VERSION ""

NS_ :

BS_:

BU_: WPC2 PSB SHVU_RR FCS vHS_B2 EMCU SLB GW_APSU GW_DLBCU RCM ARS CGW_CCU vDummy_HS_B GW_RLPSU ATS RLHV SGU PFSU GW_RRPSU ALBCU DSAU SWRC SHVU_FR RCS GW_DPSU BLTN_CAM SCM OHCL RWPC RRHV WPC HOD ASAU

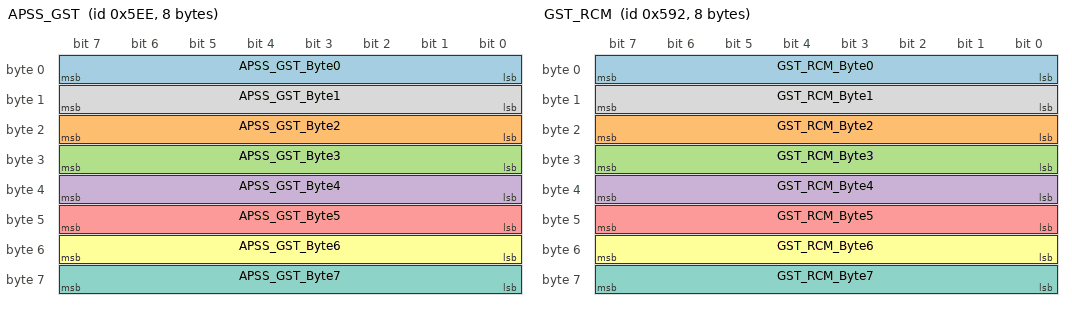
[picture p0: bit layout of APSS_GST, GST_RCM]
BO_ 1518 APSS_GST: 8 GW_APSU
 SG_ APSS_GST_Byte0 : 0|8@1+ (1,0) [0|0] ""  CGW_CCU
 SG_ APSS_GST_Byte2 : 16|8@1+ (1,0) [0|0] ""  CGW_CCU
 SG_ APSS_GST_Byte3 : 24|8@1+ (1,0) [0|0] ""  CGW_CCU
 SG_ APSS_GST_Byte4 : 32|8@1+ (1,0) [0|0] ""  CGW_CCU
 SG_ APSS_GST_Byte5 : 40|8@1+ (1,0) [0|0] ""  CGW_CCU
 SG_ APSS_GST_Byte6 : 48|8@1+ (1,0) [0|0] ""  CGW_CCU
 SG_ APSS_GST_Byte7 : 56|8@1+ (1,0) [0|0] ""  CGW_CCU
 SG_ APSS_GST_Byte1 : 8|8@1+ (1,0) [0|0] ""  CGW_CCU

BO_ 1426 GST_RCM: 8 CGW_CCU
 SG_ GST_RCM_Byte0 : 0|8@1+ (1,0) [0|0] ""  RCM
 SG_ GST_RCM_Byte2 : 16|8@1+ (1,0) [0|0] ""  RCM
 SG_ GST_RCM_Byte3 : 24|8@1+ (1,0) [0|0] ""  RCM
 SG_ GST_RCM_Byte4 : 32|8@1+ (1,0) [0|0] ""  RCM
 SG_ GST_RCM_Byte5 : 40|8@1+ (1,0) [0|0] ""  RCM
 SG_ GST_RCM_Byte6 : 48|8@1+ (1,0) [0|0] ""  RCM
 SG_ GST_RCM_Byte7 : 56|8@1+ (1,0) [0|0] ""  RCM
 SG_ GST_RCM_Byte1 : 8|8@1+ (1,0) [0|0] ""  RCM

BO_ 479 ALBCU_06_200ms: 8 ALBCU
 SG_ ALBCU_LumbarUpDis : 0|2@1+ (1,0) [0|0] "" Vector__XXX
 SG_ ALBCU_BolsterDefDis : 10|2@1+ (1,0) [0|0] "" Vector__XXX
 SG_ ALBCU_CushInfDis : 12|2@1+ (1,0) [0|0] "" Vector__XXX
 SG_ ALBCU_CushDefDis : 14|2@1+ (1,0) [0|0] "" Vector__XXX
 SG_ ALBCU_ActiveDis : 16|3@1+ (1,0) [0|0] ""  CGW_CCU
 SG_ ALBCU_DrvModUSMSta : 19|2@1+ (1,0) [0|0] ""  CGW_CCU
 SG_ ALBCU_LumbarMidDis : 2|2@1+ (1,0) [0|0] "" Vector__XXX
 SG_ ALBCU_ActiveStrSta : 21|2@1+ (1,0) [0|0] ""  CGW_CCU
 SG_ ALBCU_ActiveTimeSta : 23|3@1+ (1,0) [0|0] ""  CGW_CCU
 SG_ ALBCU_CellOpt : 26|3@1+ (1,0) [0|0] ""  CGW_CCU
 SG_ ALBCU_BodySpprtSta : 29|2@1+ (1,0) [0|0] ""  CGW_CCU
 SG_ ALBCU_BodySpprtDis : 31|2@1+ (1,0) [0|0] "" Vector__XXX
 SG_ ALBCU_SmartCtrl_Set_Rvalue : 33|4@1+ (1,0) [0|0] "" Vector__XXX
 SG_ ALBCU_MoodTrpyRValueSet : 37|2@1+ (1,0) [0|0] ""  CGW_CCU
 SG_ ALBCU_MoodTrpyCareSta : 39|2@1+ (1,0) [0|0] ""  CGW_CCU
 SG_ ALBCU_LumbarLowDis : 4|2@1+ (1,0) [0|0] "" Vector__XXX
 SG_ ALBCU_MoodTrpyComfSta : 41|2@1+ (1,0) [0|0] ""  CGW_CCU
 SG_ ALBCU_CushLeftPSnsrVtg : 48|6@1+ (1,0) [0|0] "V"  CGW_CCU
 SG_ ALBCU_CushRightPSnsrVtg : 56|6@1+ (1,0) [0|0] "V"  CGW_CCU
 SG_ ALBCU_LumbarDefDis : 6|2@1+ (1,0) [0|0] "" Vector__XXX
 SG_ ALBCU_BolsterInfDis : 8|2@1+ (1,0) [0|0] "" Vector__XXX

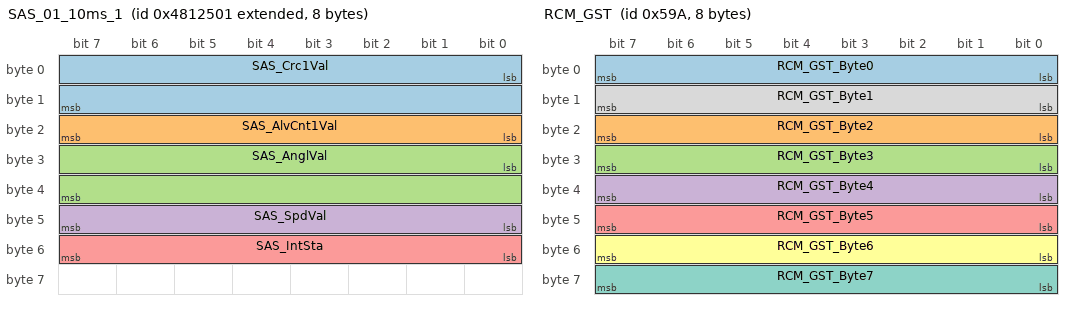
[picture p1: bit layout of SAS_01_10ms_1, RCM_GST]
BO_ 2223056129 SAS_01_10ms_1: 8 CGW_CCU
 SG_ SAS_Crc1Val : 0|16@1+ (1,0) [0|0] "" Vector__XXX
 SG_ SAS_AlvCnt1Val : 16|8@1+ (1,0) [0|0] "" Vector__XXX
 SG_ SAS_AnglVal : 24|16@1- (0.1,0) [0|0] "Deg"  BLTN_CAM,GW_DLBCU,PSB
 SG_ SAS_SpdVal : 40|8@1+ (4,0) [0|0] "Deg/s"  GW_DLBCU
 SG_ SAS_IntSta : 48|8@1+ (1,0) [0|0] "" Vector__XXX

BO_ 2223056130 SAS_01_10ms_2: 8 CGW_CCU

BO_ 1434 RCM_GST: 8 RCM
 SG_ RCM_GST_Byte0 : 0|8@1+ (1,0) [0|0] ""  CGW_CCU
 SG_ RCM_GST_Byte2 : 16|8@1+ (1,0) [0|0] ""  CGW_CCU
 SG_ RCM_GST_Byte3 : 24|8@1+ (1,0) [0|0] ""  CGW_CCU
 SG_ RCM_GST_Byte4 : 32|8@1+ (1,0) [0|0] ""  CGW_CCU
 SG_ RCM_GST_Byte5 : 40|8@1+ (1,0) [0|0] ""  CGW_CCU
 SG_ RCM_GST_Byte6 : 48|8@1+ (1,0) [0|0] ""  CGW_CCU
 SG_ RCM_GST_Byte7 : 56|8@1+ (1,0) [0|0] ""  CGW_CCU
 SG_ RCM_GST_Byte1 : 8|8@1+ (1,0) [0|0] ""  CGW_CCU

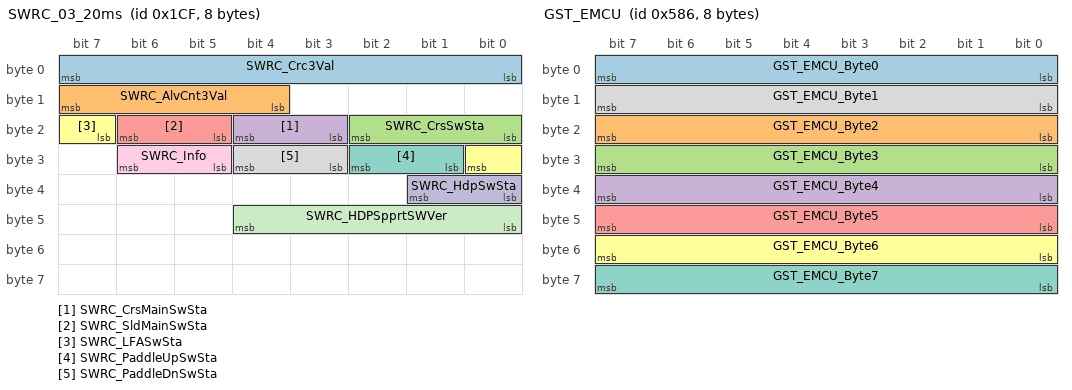
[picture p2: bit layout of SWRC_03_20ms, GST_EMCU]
BO_ 463 SWRC_03_20ms: 8 SWRC
 SG_ SWRC_Crc3Val : 0|8@1+ (1,0) [0|0] ""  CGW_CCU
 SG_ SWRC_AlvCnt3Val : 12|4@1+ (1,0) [0|0] ""  CGW_CCU
 SG_ SWRC_CrsSwSta : 16|3@1+ (1,0) [0|0] ""  CGW_CCU
 SG_ SWRC_CrsMainSwSta : 19|2@1+ (1,0) [0|0] ""  CGW_CCU
 SG_ SWRC_SldMainSwSta : 21|2@1+ (1,0) [0|0] ""  CGW_CCU
 SG_ SWRC_LFASwSta : 23|2@1+ (1,0) [0|0] ""  CGW_CCU
 SG_ SWRC_PaddleUpSwSta : 25|2@1+ (1,0) [0|0] ""  CGW_CCU
 SG_ SWRC_PaddleDnSwSta : 27|2@1+ (1,0) [0|0] ""  CGW_CCU
 SG_ SWRC_Info : 29|2@1+ (1,0) [0|0] ""  CGW_CCU
 SG_ SWRC_HdpSwSta : 32|2@1+ (1,0) [0|0] ""  CGW_CCU
 SG_ SWRC_HDPSpprtSWVer : 40|5@1+ (1,0) [0|0] ""  CGW_CCU

BO_ 1414 GST_EMCU: 8 CGW_CCU
 SG_ GST_EMCU_Byte0 : 0|8@1+ (1,0) [0|0] ""  EMCU
 SG_ GST_EMCU_Byte2 : 16|8@1+ (1,0) [0|0] ""  EMCU
 SG_ GST_EMCU_Byte3 : 24|8@1+ (1,0) [0|0] ""  EMCU
 SG_ GST_EMCU_Byte4 : 32|8@1+ (1,0) [0|0] ""  EMCU
 SG_ GST_EMCU_Byte5 : 40|8@1+ (1,0) [0|0] ""  EMCU
 SG_ GST_EMCU_Byte6 : 48|8@1+ (1,0) [0|0] ""  EMCU
 SG_ GST_EMCU_Byte7 : 56|8@1+ (1,0) [0|0] ""  EMCU
 SG_ GST_EMCU_Byte1 : 8|8@1+ (1,0) [0|0] ""  EMCU

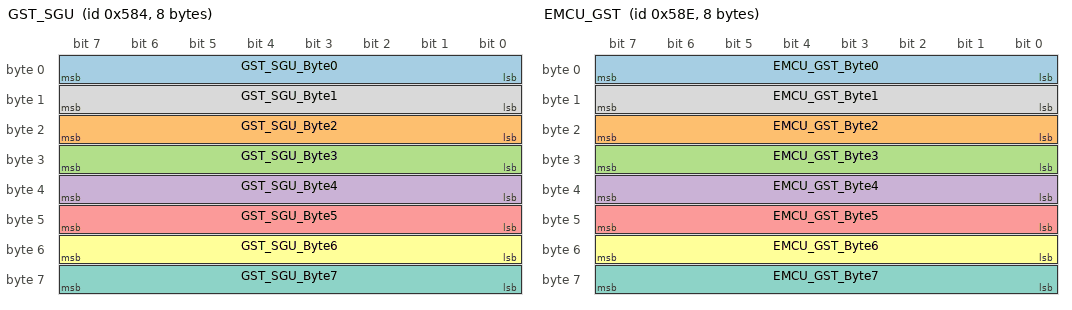
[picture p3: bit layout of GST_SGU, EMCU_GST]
BO_ 1412 GST_SGU: 8 CGW_CCU
 SG_ GST_SGU_Byte0 : 0|8@1+ (1,0) [0|0] ""  SGU
 SG_ GST_SGU_Byte2 : 16|8@1+ (1,0) [0|0] ""  SGU
 SG_ GST_SGU_Byte3 : 24|8@1+ (1,0) [0|0] ""  SGU
 SG_ GST_SGU_Byte4 : 32|8@1+ (1,0) [0|0] ""  SGU
 SG_ GST_SGU_Byte5 : 40|8@1+ (1,0) [0|0] ""  SGU
 SG_ GST_SGU_Byte6 : 48|8@1+ (1,0) [0|0] ""  SGU
 SG_ GST_SGU_Byte7 : 56|8@1+ (1,0) [0|0] ""  SGU
 SG_ GST_SGU_Byte1 : 8|8@1+ (1,0) [0|0] ""  SGU

BO_ 1422 EMCU_GST: 8 EMCU
 SG_ EMCU_GST_Byte0 : 0|8@1+ (1,0) [0|0] ""  CGW_CCU
 SG_ EMCU_GST_Byte2 : 16|8@1+ (1,0) [0|0] ""  CGW_CCU
 SG_ EMCU_GST_Byte3 : 24|8@1+ (1,0) [0|0] ""  CGW_CCU
 SG_ EMCU_GST_Byte4 : 32|8@1+ (1,0) [0|0] ""  CGW_CCU
 SG_ EMCU_GST_Byte5 : 40|8@1+ (1,0) [0|0] ""  CGW_CCU
 SG_ EMCU_GST_Byte6 : 48|8@1+ (1,0) [0|0] ""  CGW_CCU
 SG_ EMCU_GST_Byte7 : 56|8@1+ (1,0) [0|0] ""  CGW_CCU
 SG_ EMCU_GST_Byte1 : 8|8@1+ (1,0) [0|0] ""  CGW_CCU

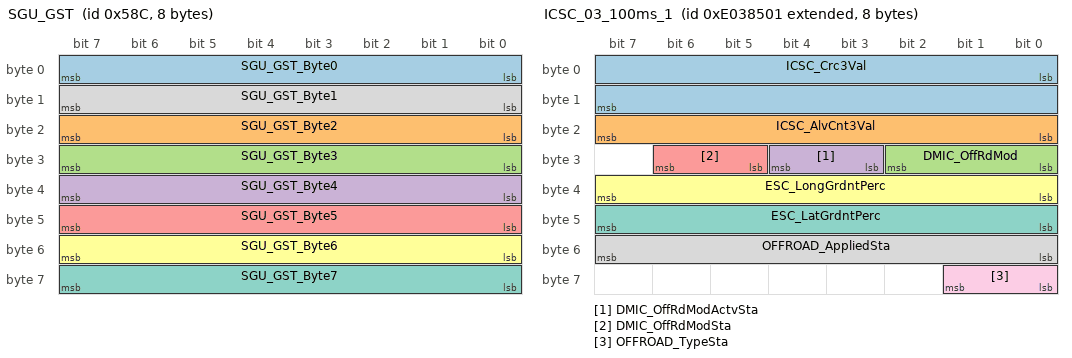
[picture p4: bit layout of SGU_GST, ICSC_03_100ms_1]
BO_ 1420 SGU_GST: 8 SGU
 SG_ SGU_GST_Byte0 : 0|8@1+ (1,0) [0|0] ""  CGW_CCU
 SG_ SGU_GST_Byte2 : 16|8@1+ (1,0) [0|0] ""  CGW_CCU
 SG_ SGU_GST_Byte3 : 24|8@1+ (1,0) [0|0] ""  CGW_CCU
 SG_ SGU_GST_Byte4 : 32|8@1+ (1,0) [0|0] ""  CGW_CCU
 SG_ SGU_GST_Byte5 : 40|8@1+ (1,0) [0|0] ""  CGW_CCU
 SG_ SGU_GST_Byte6 : 48|8@1+ (1,0) [0|0] ""  CGW_CCU
 SG_ SGU_GST_Byte7 : 56|8@1+ (1,0) [0|0] ""  CGW_CCU
 SG_ SGU_GST_Byte1 : 8|8@1+ (1,0) [0|0] ""  CGW_CCU

BO_ 2382595329 ICSC_03_100ms_1: 8 CGW_CCU
 SG_ ICSC_Crc3Val : 0|16@1+ (1,0) [0|0] "" Vector__XXX
 SG_ ICSC_AlvCnt3Val : 16|8@1+ (1,0) [0|0] "" Vector__XXX
 SG_ DMIC_OffRdMod : 24|3@1+ (1,0) [0|0] "" Vector__XXX
 SG_ DMIC_OffRdModActvSta : 27|2@1+ (1,0) [0|0] ""  RCS
 SG_ DMIC_OffRdModSta : 29|2@1+ (1,0) [0|0] "" Vector__XXX
 SG_ ESC_LongGrdntPerc : 32|8@1- (1,0) [0|0] "%"  EMCU
 SG_ ESC_LatGrdntPerc : 40|8@1- (1,0) [0|0] "%"  EMCU
 SG_ OFFROAD_AppliedSta : 48|8@1+ (1,0) [0|0] "" Vector__XXX
 SG_ OFFROAD_TypeSta : 56|2@1+ (1,0) [0|0] "" Vector__XXX

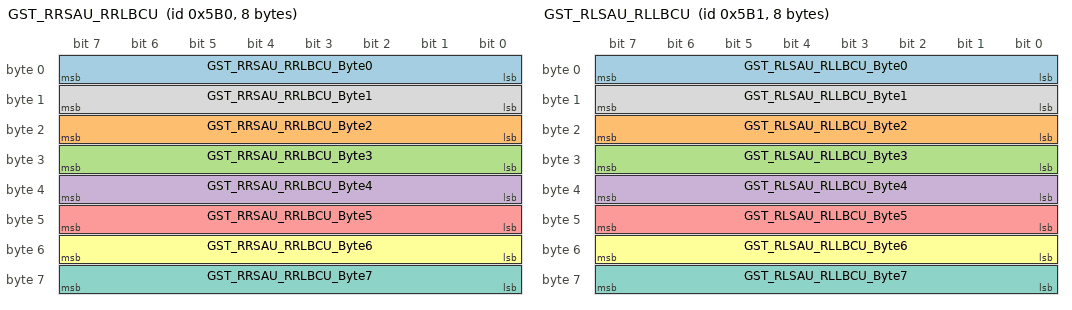
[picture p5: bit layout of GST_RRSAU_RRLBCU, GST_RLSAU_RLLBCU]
BO_ 1456 GST_RRSAU_RRLBCU: 8 CGW_CCU
 SG_ GST_RRSAU_RRLBCU_Byte0 : 0|8@1+ (1,0) [0|0] ""  GW_DLBCU
 SG_ GST_RRSAU_RRLBCU_Byte2 : 16|8@1+ (1,0) [0|0] ""  GW_DLBCU
 SG_ GST_RRSAU_RRLBCU_Byte3 : 24|8@1+ (1,0) [0|0] ""  GW_DLBCU
 SG_ GST_RRSAU_RRLBCU_Byte4 : 32|8@1+ (1,0) [0|0] ""  GW_DLBCU
 SG_ GST_RRSAU_RRLBCU_Byte5 : 40|8@1+ (1,0) [0|0] ""  GW_DLBCU
 SG_ GST_RRSAU_RRLBCU_Byte6 : 48|8@1+ (1,0) [0|0] ""  GW_DLBCU
 SG_ GST_RRSAU_RRLBCU_Byte7 : 56|8@1+ (1,0) [0|0] ""  GW_DLBCU
 SG_ GST_RRSAU_RRLBCU_Byte1 : 8|8@1+ (1,0) [0|0] ""  GW_DLBCU

BO_ 1457 GST_RLSAU_RLLBCU: 8 CGW_CCU
 SG_ GST_RLSAU_RLLBCU_Byte0 : 0|8@1+ (1,0) [0|0] ""  GW_DLBCU
 SG_ GST_RLSAU_RLLBCU_Byte2 : 16|8@1+ (1,0) [0|0] ""  GW_DLBCU
 SG_ GST_RLSAU_RLLBCU_Byte3 : 24|8@1+ (1,0) [0|0] ""  GW_DLBCU
 SG_ GST_RLSAU_RLLBCU_Byte4 : 32|8@1+ (1,0) [0|0] ""  GW_DLBCU
 SG_ GST_RLSAU_RLLBCU_Byte5 : 40|8@1+ (1,0) [0|0] ""  GW_DLBCU
 SG_ GST_RLSAU_RLLBCU_Byte6 : 48|8@1+ (1,0) [0|0] ""  GW_DLBCU
 SG_ GST_RLSAU_RLLBCU_Byte7 : 56|8@1+ (1,0) [0|0] ""  GW_DLBCU
 SG_ GST_RLSAU_RLLBCU_Byte1 : 8|8@1+ (1,0) [0|0] ""  GW_DLBCU

BO_ 2328014852 DATC_17_200ms_4: 8 CGW_CCU

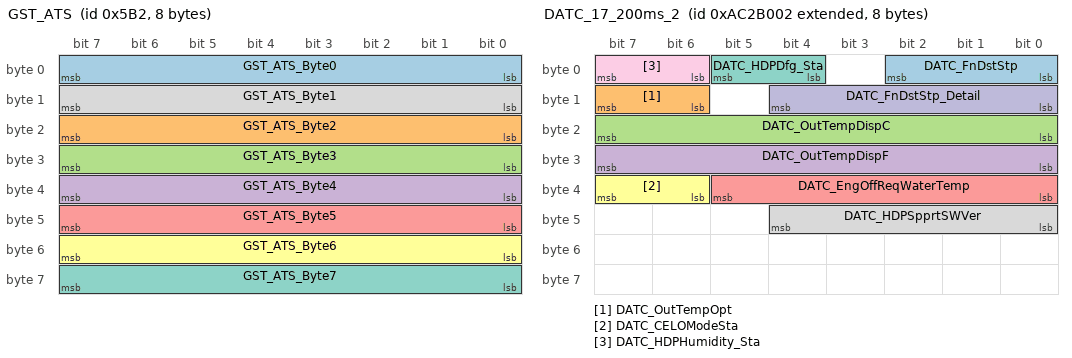
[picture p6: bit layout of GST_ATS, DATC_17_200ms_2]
BO_ 1458 GST_ATS: 8 CGW_CCU
 SG_ GST_ATS_Byte0 : 0|8@1+ (1,0) [0|0] ""  ATS
 SG_ GST_ATS_Byte2 : 16|8@1+ (1,0) [0|0] ""  ATS
 SG_ GST_ATS_Byte3 : 24|8@1+ (1,0) [0|0] ""  ATS
 SG_ GST_ATS_Byte4 : 32|8@1+ (1,0) [0|0] ""  ATS
 SG_ GST_ATS_Byte5 : 40|8@1+ (1,0) [0|0] ""  ATS
 SG_ GST_ATS_Byte6 : 48|8@1+ (1,0) [0|0] ""  ATS
 SG_ GST_ATS_Byte7 : 56|8@1+ (1,0) [0|0] ""  ATS
 SG_ GST_ATS_Byte1 : 8|8@1+ (1,0) [0|0] ""  ATS

BO_ 2328014850 DATC_17_200ms_2: 8 CGW_CCU
 SG_ DATC_FnDstStp : 0|3@1+ (1,0) [0|0] ""  ATS
 SG_ DATC_OutTempOpt : 14|2@1+ (1,0) [0|0] "" Vector__XXX
 SG_ DATC_OutTempDispC : 16|8@1+ (0.5,-41) [0|0] "¡É"  ATS
 SG_ DATC_OutTempDispF : 24|8@1+ (1,-42) [0|0] "¢µ"  ATS
 SG_ DATC_EngOffReqWaterTemp : 32|6@1+ (1,38) [0|0] "¡É" Vector__XXX
 SG_ DATC_CELOModeSta : 38|2@1+ (1,0) [0|0] "" Vector__XXX
 SG_ DATC_HDPDfg_Sta : 4|2@1+ (1,0) [0|0] "" Vector__XXX
 SG_ DATC_HDPSpprtSWVer : 40|5@1+ (1,0) [0|0] "" Vector__XXX
 SG_ DATC_HDPHumidity_Sta : 6|2@1+ (1,0) [0|0] "" Vector__XXX
 SG_ DATC_FnDstStp_Detail : 8|5@1+ (1,0) [0|0] ""  ATS

BO_ 2328014851 DATC_17_200ms_3: 8 CGW_CCU

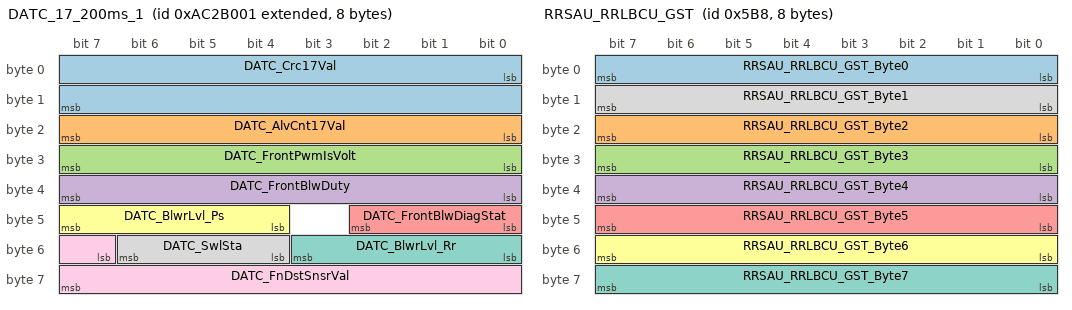
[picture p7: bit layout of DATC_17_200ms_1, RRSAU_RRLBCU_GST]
BO_ 2328014849 DATC_17_200ms_1: 8 CGW_CCU
 SG_ DATC_Crc17Val : 0|16@1+ (1,0) [0|0] "" Vector__XXX
 SG_ DATC_AlvCnt17Val : 16|8@1+ (1,0) [0|0] "" Vector__XXX
 SG_ DATC_FrontPwmIsVolt : 24|8@1+ (0.02,0) [0|0] "V" Vector__XXX
 SG_ DATC_FrontBlwDuty : 32|8@1+ (1,0) [0|0] "" Vector__XXX
 SG_ DATC_FrontBlwDiagStat : 40|3@1+ (1,0) [0|0] "" Vector__XXX
 SG_ DATC_BlwrLvl_Ps : 44|4@1+ (1,0) [0|0] "" Vector__XXX
 SG_ DATC_BlwrLvl_Rr : 48|4@1+ (1,0) [0|0] "" Vector__XXX
 SG_ DATC_SwlSta : 52|3@1+ (1,0) [0|0] "" Vector__XXX
 SG_ DATC_FnDstSnsrVal : 55|9@1+ (1,0) [0|0] "" Vector__XXX

BO_ 1464 RRSAU_RRLBCU_GST: 8 GW_DLBCU
 SG_ RRSAU_RRLBCU_GST_Byte0 : 0|8@1+ (1,0) [0|0] ""  CGW_CCU
 SG_ RRSAU_RRLBCU_GST_Byte2 : 16|8@1+ (1,0) [0|0] ""  CGW_CCU
 SG_ RRSAU_RRLBCU_GST_Byte3 : 24|8@1+ (1,0) [0|0] ""  CGW_CCU
 SG_ RRSAU_RRLBCU_GST_Byte4 : 32|8@1+ (1,0) [0|0] ""  CGW_CCU
 SG_ RRSAU_RRLBCU_GST_Byte5 : 40|8@1+ (1,0) [0|0] ""  CGW_CCU
 SG_ RRSAU_RRLBCU_GST_Byte6 : 48|8@1+ (1,0) [0|0] ""  CGW_CCU
 SG_ RRSAU_RRLBCU_GST_Byte7 : 56|8@1+ (1,0) [0|0] ""  CGW_CCU
 SG_ RRSAU_RRLBCU_GST_Byte1 : 8|8@1+ (1,0) [0|0] ""  CGW_CCU

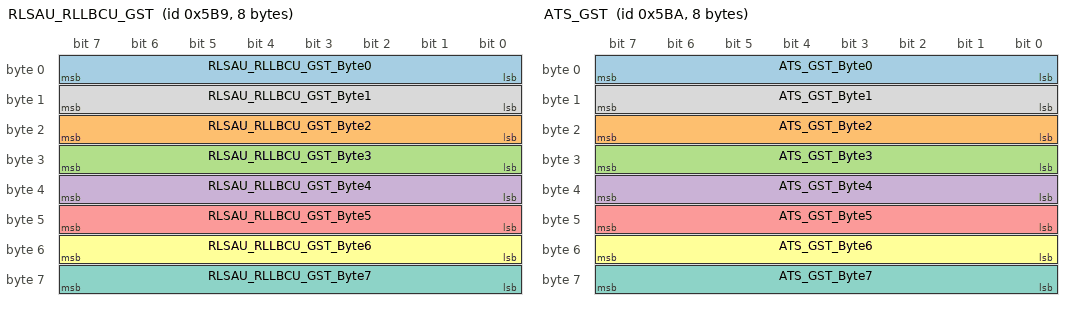
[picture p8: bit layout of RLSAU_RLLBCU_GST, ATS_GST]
BO_ 1465 RLSAU_RLLBCU_GST: 8 GW_DLBCU
 SG_ RLSAU_RLLBCU_GST_Byte0 : 0|8@1+ (1,0) [0|0] ""  CGW_CCU
 SG_ RLSAU_RLLBCU_GST_Byte2 : 16|8@1+ (1,0) [0|0] ""  CGW_CCU
 SG_ RLSAU_RLLBCU_GST_Byte3 : 24|8@1+ (1,0) [0|0] ""  CGW_CCU
 SG_ RLSAU_RLLBCU_GST_Byte4 : 32|8@1+ (1,0) [0|0] ""  CGW_CCU
 SG_ RLSAU_RLLBCU_GST_Byte5 : 40|8@1+ (1,0) [0|0] ""  CGW_CCU
 SG_ RLSAU_RLLBCU_GST_Byte6 : 48|8@1+ (1,0) [0|0] ""  CGW_CCU
 SG_ RLSAU_RLLBCU_GST_Byte7 : 56|8@1+ (1,0) [0|0] ""  CGW_CCU
 SG_ RLSAU_RLLBCU_GST_Byte1 : 8|8@1+ (1,0) [0|0] ""  CGW_CCU

BO_ 1466 ATS_GST: 8 ATS
 SG_ ATS_GST_Byte0 : 0|8@1+ (1,0) [0|0] ""  CGW_CCU
 SG_ ATS_GST_Byte2 : 16|8@1+ (1,0) [0|0] ""  CGW_CCU
 SG_ ATS_GST_Byte3 : 24|8@1+ (1,0) [0|0] ""  CGW_CCU
 SG_ ATS_GST_Byte4 : 32|8@1+ (1,0) [0|0] ""  CGW_CCU
 SG_ ATS_GST_Byte5 : 40|8@1+ (1,0) [0|0] ""  CGW_CCU
 SG_ ATS_GST_Byte6 : 48|8@1+ (1,0) [0|0] ""  CGW_CCU
 SG_ ATS_GST_Byte7 : 56|8@1+ (1,0) [0|0] ""  CGW_CCU
 SG_ ATS_GST_Byte1 : 8|8@1+ (1,0) [0|0] ""  CGW_CCU

BO_ 491 HU_USM_E_14: 8 CGW_CCU
 SG_ CF_AVN_Roof_OprLvSet : 0|3@1+ (1,0) [0|0] ""  SGU
 SG_ CF_AVN_3rdRightDoor_OptLvlSet : 12|3@1+ (1,0) [0|0] ""  SGU
 SG_ CF_AVN_RearDoor_OptLvlSet : 15|3@1+ (1,0) [0|0] ""  SGU
 SG_ CF_AVN_RollBlindOnOffSet : 18|2@1+ (1,0) [0|0] ""  SGU
 SG_ CF_AVN_CluThmAutoSet_New : 20|2@1+ (1,0) [0|0] "" Vector__XXX
 SG_ CF_AVN_CluThmSet_New : 22|3@1+ (1,0) [0|0] "" Vector__XXX
 SG_ CF_AVN_CluThmDtlSet_New : 25|3@1+ (1,0) [0|0] "" Vector__XXX
 SG_ CF_AVN_MdLmpAIVoiceUSMNValueSet : 28|2@1+ (1,0) [0|0] "" Vector__XXX
 SG_ CF_AVN_2ndLeftDoor_OptLvSet : 3|3@1+ (1,0) [0|0] ""  SGU
 SG_ CF_AVN_DWL_SelectNvalueSet : 30|4@1+ (1,0) [0|0] "" Vector__XXX
 SG_ PwrDRClosingDrvDrReq : 34|2@1+ (1,0) [0|0] "" Vector__XXX
 SG_ CF_Gway_WPCAnimationNvalueSet : 40|3@1+ (1,0) [0|0] ""  RWPC,WPC,WPC2
 SG_ PwrDRClosingAstDrReq : 43|2@1+ (1,0) [0|0] "" Vector__XXX
 SG_ PwrDRClosingRLDrReq : 45|2@1+ (1,0) [0|0] "" Vector__XXX
 SG_ PwrDrClosingRRDrReq : 47|2@1+ (1,0) [0|0] "" Vector__XXX
 SG_ USM_BtnIllumiAlwaysOnReq : 49|2@1+ (1,0) [0|0] "" Vector__XXX
 SG_ CF_AVN_LKAWrngVolNvalueSet : 51|2@1+ (1,0) [0|0] "" Vector__XXX
 SG_ DAB_IlluminationVrModeSet : 53|3@1+ (1,0) [0|0] ""  SWRC
 SG_ USM_IllAlwaysOnwithPSTNReq : 56|3@1+ (1,0) [0|0] "" Vector__XXX
 SG_ CF_AVN_AutoStopTimerResetSet : 59|3@1+ (1,0) [0|0] "" Vector__XXX
 SG_ CF_AVN_2ndRightDoor_OptLvSet : 6|3@1+ (1,0) [0|0] ""  SGU
 SG_ USM_RrCurtainSet : 62|2@1+ (1,0) [0|0] "" Vector__XXX
 SG_ CF_AVN_3rdLeftDoor_OptLvlSet : 9|3@1+ (1,0) [0|0] ""  SGU

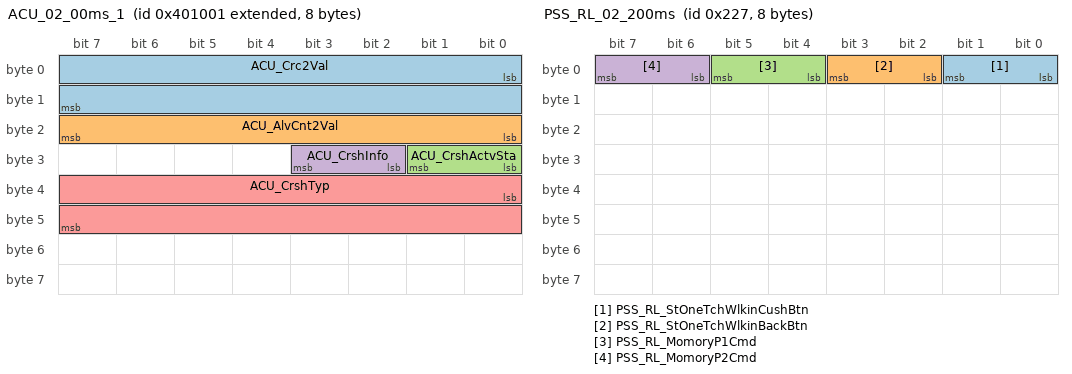
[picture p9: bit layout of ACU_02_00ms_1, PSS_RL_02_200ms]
BO_ 2151682049 ACU_02_00ms_1: 8 CGW_CCU
 SG_ ACU_Crc2Val : 0|16@1+ (1,0) [0|0] "" Vector__XXX
 SG_ ACU_AlvCnt2Val : 16|8@1+ (1,0) [0|0] "" Vector__XXX
 SG_ ACU_CrshActvSta : 24|2@1+ (1,0) [0|0] ""  GW_APSU,GW_DPSU,GW_RLPSU,GW_RRPSU
 SG_ ACU_CrshInfo : 26|2@1+ (1,0) [0|0] "" Vector__XXX
 SG_ ACU_CrshTyp : 32|16@1+ (1,0) [0|0] "" Vector__XXX

BO_ 550 PSS_RL_01_200ms: 8 GW_RLPSU
 SG_ PSS_RL_StSldFwdMvBtn : 0|2@1+ (1,0) [0|0] ""  CGW_CCU
 SG_ PSS_RL_StTltDnMvBtn : 10|2@1+ (1,0) [0|0] ""  CGW_CCU
 SG_ PSS_RL_StHRestUpMvBtn : 12|2@1+ (1,0) [0|0] ""  CGW_CCU
 SG_ PSS_RL_StHRestDnMvBtn : 14|2@1+ (1,0) [0|0] ""  CGW_CCU
 SG_ PSS_RL_StHRestFwdMvBtn : 16|2@1+ (1,0) [0|0] ""  CGW_CCU
 SG_ PSS_RL_StHRestBwdMvBtn : 18|2@1+ (1,0) [0|0] ""  CGW_CCU
 SG_ PSS_RL_StSldBwdMvBtn : 2|2@1+ (1,0) [0|0] ""  CGW_CCU
 SG_ PSS_RL_StLegRestUpBtn : 20|2@1+ (1,0) [0|0] ""  CGW_CCU
 SG_ PSS_RL_StLegRestDnBtn : 22|2@1+ (1,0) [0|0] ""  CGW_CCU
 SG_ PSS_RL_StLegRestExtFwdBtn : 24|2@1+ (1,0) [0|0] ""  CGW_CCU
 SG_ PSS_RL_StLegRestExtBwdBtn : 26|2@1+ (1,0) [0|0] ""  CGW_CCU
 SG_ PSS_RL_StRlxModeBtn : 28|2@1+ (1,0) [0|0] ""  CGW_CCU
 SG_ PSS_RL_StRlxReturnBtn : 30|2@1+ (1,0) [0|0] ""  CGW_CCU
 SG_ PSS_RL_StRlxTltUpMvBtn : 32|2@1+ (1,0) [0|0] ""  CGW_CCU
 SG_ PSS_RL_StRlxTltDnMvBtn : 34|2@1+ (1,0) [0|0] ""  CGW_CCU
 SG_ PSS_RL_StMnlRlxModeBtn : 36|2@1+ (1,0) [0|0] ""  CGW_CCU
 SG_ PSS_RL_StMnlRlxReturnBtn : 38|2@1+ (1,0) [0|0] ""  CGW_CCU
 SG_ PSS_RL_StRclFwdMvBtn : 4|2@1+ (1,0) [0|0] ""  CGW_CCU
 SG_ PSS_RL_WalkInSwitchSts : 40|2@1+ (1,0) [0|0] ""  CGW_CCU
 SG_ PSS_RL_StRclBwdMvBtn : 6|2@1+ (1,0) [0|0] ""  CGW_CCU
 SG_ PSS_RL_StTltUpMvBtn : 8|2@1+ (1,0) [0|0] ""  CGW_CCU

BO_ 551 PSS_RL_02_200ms: 8 GW_RLPSU
 SG_ PSS_RL_StOneTchWlkinCushBtn : 0|2@1+ (1,0) [0|0] ""  CGW_CCU
 SG_ PSS_RL_StOneTchWlkinBackBtn : 2|2@1+ (1,0) [0|0] ""  CGW_CCU
 SG_ PSS_RL_MomoryP1Cmd : 4|2@1+ (1,0) [0|0] ""  CGW_CCU
 SG_ PSS_RL_MomoryP2Cmd : 6|2@1+ (1,0) [0|0] ""  CGW_CCU

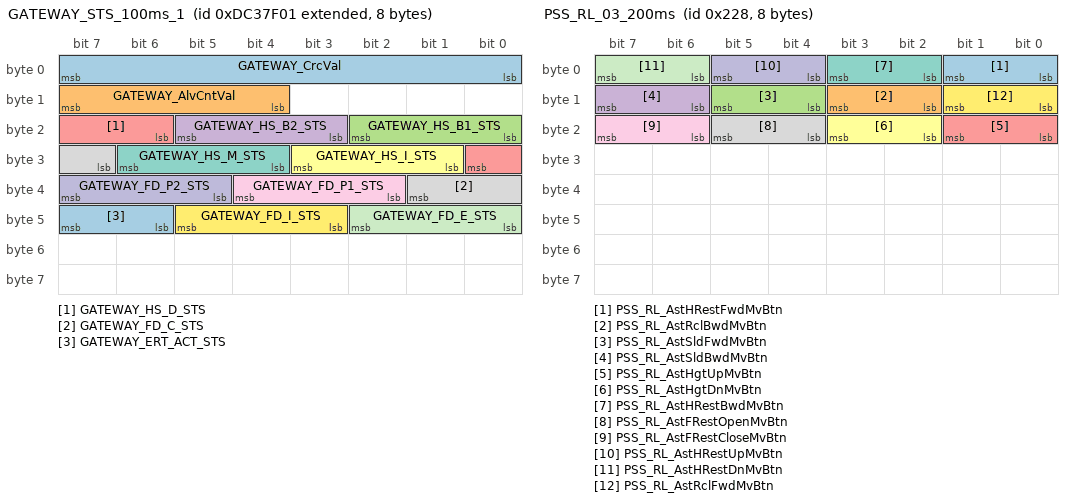
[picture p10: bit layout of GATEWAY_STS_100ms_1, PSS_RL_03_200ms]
BO_ 2378399489 GATEWAY_STS_100ms_1: 8 CGW_CCU
 SG_ GATEWAY_CrcVal : 0|8@1+ (1,0) [0|0] ""  vHS_B2
 SG_ GATEWAY_AlvCntVal : 12|4@1+ (1,0) [0|0] "" Vector__XXX
 SG_ GATEWAY_HS_B1_STS : 16|3@1+ (1,0) [0|0] ""  vHS_B2
 SG_ GATEWAY_HS_B2_STS : 19|3@1+ (1,0) [0|0] ""  vHS_B2
 SG_ GATEWAY_HS_D_STS : 22|3@1+ (1,0) [0|0] ""  vHS_B2
 SG_ GATEWAY_HS_I_STS : 25|3@1+ (1,0) [0|0] "" Vector__XXX
 SG_ GATEWAY_HS_M_STS : 28|3@1+ (1,0) [0|0] "" Vector__XXX
 SG_ GATEWAY_FD_C_STS : 31|3@1+ (1,0) [0|0] "" Vector__XXX
 SG_ GATEWAY_FD_P1_STS : 34|3@1+ (1,0) [0|0] "" Vector__XXX
 SG_ GATEWAY_FD_P2_STS : 37|3@1+ (1,0) [0|0] "" Vector__XXX
 SG_ GATEWAY_FD_E_STS : 40|3@1+ (1,0) [0|0] "" Vector__XXX
 SG_ GATEWAY_FD_I_STS : 43|3@1+ (1,0) [0|0] ""  vHS_B2
 SG_ GATEWAY_ERT_ACT_STS : 46|2@1+ (1,0) [0|0] "" Vector__XXX

BO_ 552 PSS_RL_03_200ms: 8 GW_RLPSU
 SG_ PSS_RL_AstHRestFwdMvBtn : 0|2@1+ (1,0) [0|0] ""  CGW_CCU
 SG_ PSS_RL_AstRclBwdMvBtn : 10|2@1+ (1,0) [0|0] ""  CGW_CCU
 SG_ PSS_RL_AstSldFwdMvBtn : 12|2@1+ (1,0) [0|0] ""  CGW_CCU
 SG_ PSS_RL_AstSldBwdMvBtn : 14|2@1+ (1,0) [0|0] ""  CGW_CCU
 SG_ PSS_RL_AstHgtUpMvBtn : 16|2@1+ (1,0) [0|0] ""  CGW_CCU
 SG_ PSS_RL_AstHgtDnMvBtn : 18|2@1+ (1,0) [0|0] ""  CGW_CCU
 SG_ PSS_RL_AstHRestBwdMvBtn : 2|2@1+ (1,0) [0|0] ""  CGW_CCU
 SG_ PSS_RL_AstFRestOpenMvBtn : 20|2@1+ (1,0) [0|0] ""  CGW_CCU
 SG_ PSS_RL_AstFRestCloseMvBtn : 22|2@1+ (1,0) [0|0] ""  CGW_CCU
 SG_ PSS_RL_AstHRestUpMvBtn : 4|2@1+ (1,0) [0|0] ""  CGW_CCU
 SG_ PSS_RL_AstHRestDnMvBtn : 6|2@1+ (1,0) [0|0] ""  CGW_CCU
 SG_ PSS_RL_AstRclFwdMvBtn : 8|2@1+ (1,0) [0|0] ""  CGW_CCU

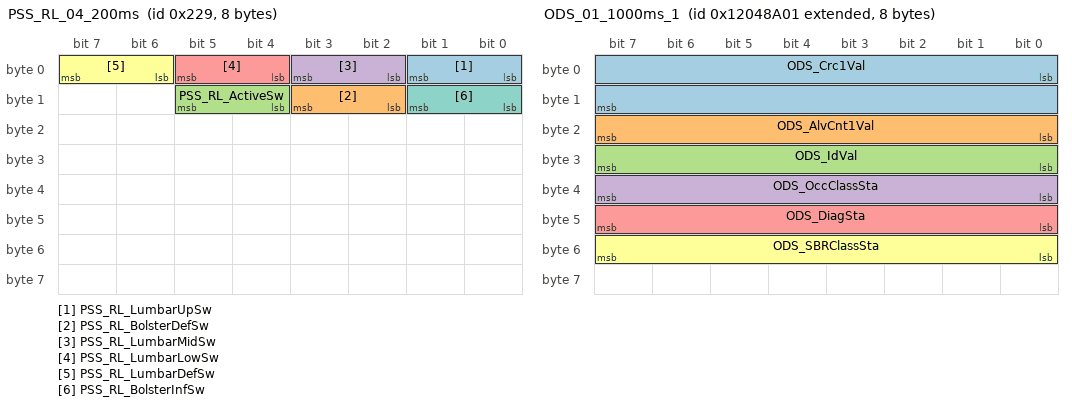
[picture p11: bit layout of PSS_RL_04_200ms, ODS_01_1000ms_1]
BO_ 553 PSS_RL_04_200ms: 8 GW_RLPSU
 SG_ PSS_RL_LumbarUpSw : 0|2@1+ (1,0) [0|0] ""  CGW_CCU,DSAU,GW_DLBCU
 SG_ PSS_RL_BolsterDefSw : 10|2@1+ (1,0) [0|0] ""  CGW_CCU,DSAU,GW_DLBCU
 SG_ PSS_RL_ActiveSw : 12|2@1+ (1,0) [0|0] ""  CGW_CCU,DSAU,GW_DLBCU
 SG_ PSS_RL_LumbarMidSw : 2|2@1+ (1,0) [0|0] ""  CGW_CCU,DSAU,GW_DLBCU
 SG_ PSS_RL_LumbarLowSw : 4|2@1+ (1,0) [0|0] ""  CGW_CCU,DSAU,GW_DLBCU
 SG_ PSS_RL_LumbarDefSw : 6|2@1+ (1,0) [0|0] ""  CGW_CCU,DSAU,GW_DLBCU
 SG_ PSS_RL_BolsterInfSw : 8|2@1+ (1,0) [0|0] ""  CGW_CCU,DSAU,GW_DLBCU

BO_ 2449771009 ODS_01_1000ms_1: 8 CGW_CCU
 SG_ ODS_Crc1Val : 0|16@1+ (1,0) [0|0] "" Vector__XXX
 SG_ ODS_AlvCnt1Val : 16|8@1+ (1,0) [0|0] "" Vector__XXX
 SG_ ODS_IdVal : 24|8@1+ (1,0) [0|0] "" Vector__XXX
 SG_ ODS_OccClassSta : 32|8@1+ (1,0) [0|0] ""  ATS,GW_APSU,GW_DPSU,GW_RLPSU,GW_RRPSU
 SG_ ODS_DiagSta : 40|8@1+ (1,0) [0|0] "" Vector__XXX
 SG_ ODS_SBRClassSta : 48|8@1+ (1,0) [0|0] "" Vector__XXX

BO_ 2449771010 ODS_01_1000ms_2: 8 CGW_CCU

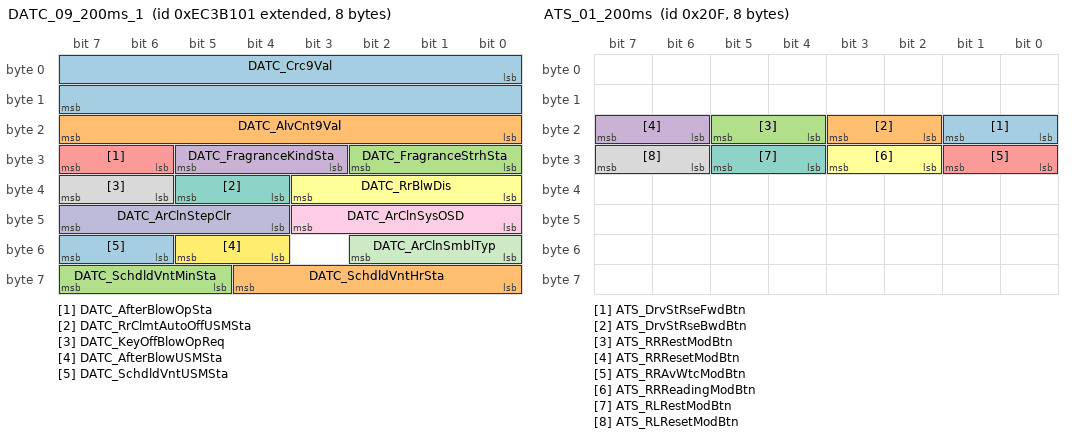
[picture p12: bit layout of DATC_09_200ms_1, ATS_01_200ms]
BO_ 2395189505 DATC_09_200ms_1: 8 CGW_CCU
 SG_ DATC_Crc9Val : 0|16@1+ (1,0) [0|0] "" Vector__XXX
 SG_ DATC_AlvCnt9Val : 16|8@1+ (1,0) [0|0] "" Vector__XXX
 SG_ DATC_FragranceStrhSta : 24|3@1+ (1,0) [0|0] ""  ATS
 SG_ DATC_FragranceKindSta : 27|3@1+ (1,0) [0|0] ""  ATS
 SG_ DATC_AfterBlowOpSta : 30|2@1+ (1,0) [0|0] "" Vector__XXX
 SG_ DATC_RrBlwDis : 32|4@1+ (1,0) [0|0] ""  ATS
 SG_ DATC_RrClmtAutoOffUSMSta : 36|2@1+ (1,0) [0|0] "" Vector__XXX
 SG_ DATC_KeyOffBlowOpReq : 38|2@1+ (1,0) [0|0] "" Vector__XXX
 SG_ DATC_ArClnSysOSD : 40|4@1+ (1,0) [0|0] "" Vector__XXX
 SG_ DATC_ArClnStepClr : 44|4@1+ (1,0) [0|0] ""  ATS
 SG_ DATC_ArClnSmblTyp : 48|3@1+ (1,0) [0|0] ""  ATS
 SG_ DATC_AfterBlowUSMSta : 52|2@1+ (1,0) [0|0] "" Vector__XXX
 SG_ DATC_SchdldVntUSMSta : 54|2@1+ (1,0) [0|0] "" Vector__XXX
 SG_ DATC_SchdldVntHrSta : 56|5@1+ (1,0) [0|0] "" Vector__XXX
 SG_ DATC_SchdldVntMinSta : 61|3@1+ (1,0) [0|0] "" Vector__XXX

BO_ 527 ATS_01_200ms: 8 ATS
 SG_ ATS_DrvStRseFwdBtn : 16|2@1+ (1,0) [0|0] "" Vector__XXX
 SG_ ATS_DrvStRseBwdBtn : 18|2@1+ (1,0) [0|0] "" Vector__XXX
 SG_ ATS_RRRestModBtn : 20|2@1+ (1,0) [0|0] "" Vector__XXX
 SG_ ATS_RRResetModBtn : 22|2@1+ (1,0) [0|0] "" Vector__XXX
 SG_ ATS_RRAvWtcModBtn : 24|2@1+ (1,0) [0|0] "" Vector__XXX
 SG_ ATS_RRReadingModBtn : 26|2@1+ (1,0) [0|0] "" Vector__XXX
 SG_ ATS_RLRestModBtn : 28|2@1+ (1,0) [0|0] "" Vector__XXX
 SG_ ATS_RLResetModBtn : 30|2@1+ (1,0) [0|0] "" Vector__XXX

BO_ 1616 MKBD_HU_E_01: 8 CGW_CCU
 SG_ MKBD_IllumiState : 48|2@1+ (1,0) [0|0] "" Vector__XXX
 SG_ MKBD_SeatKeySet : 50|2@1+ (1,0) [0|0] ""  GW_APSU,GW_DPSU,SHVU_FR

BO_ 543 ATS_02_200ms: 8 ATS
 SG_ ATS_AstStSldFwdBtn : 16|2@1+ (1,0) [0|0] "" Vector__XXX
 SG_ ATS_AstStSldBwdBtn : 18|2@1+ (1,0) [0|0] "" Vector__XXX
 SG_ ATS_AstStRclFwdBtn : 20|2@1+ (1,0) [0|0] "" Vector__XXX
 SG_ ATS_AstStRclBwdBtn : 22|2@1+ (1,0) [0|0] "" Vector__XXX
 SG_ ATS_AstStHgtUpBtn : 28|2@1+ (1,0) [0|0] "" Vector__XXX
 SG_ ATS_AstStHgtDnBtn : 30|2@1+ (1,0) [0|0] "" Vector__XXX
 SG_ ATS_AstStHRestUpBtn : 40|2@1+ (1,0) [0|0] "" Vector__XXX
 SG_ ATS_AstStHRestDnBtn : 42|2@1+ (1,0) [0|0] "" Vector__XXX
 SG_ ATS_AstStHRestFwdBtn : 44|2@1+ (1,0) [0|0] "" Vector__XXX
 SG_ ATS_AstStHRestBwdBtn : 46|2@1+ (1,0) [0|0] "" Vector__XXX
 SG_ ATS_AstStHRestFldBtn : 48|2@1+ (1,0) [0|0] "" Vector__XXX
 SG_ ATS_AstStHRestUnFldBtn : 50|2@1+ (1,0) [0|0] "" Vector__XXX
 SG_ ATS_AstStRseFwdBtn : 52|2@1+ (1,0) [0|0] "" Vector__XXX
 SG_ ATS_AstStRseBwdBtn : 54|2@1+ (1,0) [0|0] "" Vector__XXX
 SG_ ATS_AstStFRestFldBtn : 56|2@1+ (1,0) [0|0] "" Vector__XXX
 SG_ ATS_AstStFRestUnFldBtn : 58|2@1+ (1,0) [0|0] "" Vector__XXX
 SG_ ATS_AstTltUpBtn : 60|2@1+ (1,0) [0|0] "" Vector__XXX
 SG_ ATS_AstTltDnBtn : 62|2@1+ (1,0) [0|0] "" Vector__XXX

CM_ BO_ 1518 "[TP] Transport Protocol";
CM_ BO_ 1426 "[TP] Transport Protocol";
CM_ BO_ 479 "[PE] Periodic and On Event";
CM_ SG_ 479 ALBCU_LumbarUpDis "ALBCU_LumbarUppperDisplay";
CM_ SG_ 479 ALBCU_BolsterDefDis "ALBCU_BolsterDeflationDisplay";
CM_ SG_ 479 ALBCU_CushInfDis "ALBCU_CushionInflationDisplay";
CM_ SG_ 479 ALBCU_CushDefDis "ALBCU_CushionDeflationDisplay";
CM_ SG_ 479 ALBCU_ActiveDis "ALBCU_ActiveModeDisplay";
CM_ SG_ 479 ALBCU_DrvModUSMSta "ALBCU_DriveModeStatus";
CM_ SG_ 479 ALBCU_LumbarMidDis "ALBCU_LumbarMidDisplay";
CM_ SG_ 479 ALBCU_ActiveStrSta "ALBCU_ActiveStrengthStatus";
CM_ SG_ 479 ALBCU_ActiveTimeSta "ALBCU_ActiveTimeStatus";
CM_ SG_ 479 ALBCU_CellOpt "ALBCU_CellOption Status";
CM_ SG_ 479 ALBCU_BodySpprtSta "Seat Body Support Function USM R Value";
CM_ SG_ 479 ALBCU_BodySpprtDis "Seat body Support Function Display Request";
CM_ SG_ 479 ALBCU_SmartCtrl_Set_Rvalue "Smart Posture Adjust Function USM R Value";
CM_ SG_ 479 ALBCU_MoodTrpyRValueSet "Passenger Seat Mood Therapy R Value";
CM_ SG_ 479 ALBCU_MoodTrpyCareSta "Passenger Seat Mood Therapy Care Mode R Value";
CM_ SG_ 479 ALBCU_LumbarLowDis "ALBCU_LumbarLowerDisplay";
CM_ SG_ 479 ALBCU_MoodTrpyComfSta "Passenger Seat Mood Therapy Comfort Mode R Value";
CM_ SG_ 479 ALBCU_LumbarDefDis "ALBCU_LumbarDeflationDisplay";
CM_ SG_ 479 ALBCU_BolsterInfDis "ALBCU_BolsterInflationDisplay";
CM_ BO_ 2223056129 "[P] Periodic";
CM_ SG_ 2223056129 SAS_Crc1Val "SAS_CyclicRedundancyCheck1Value";
CM_ SG_ 2223056129 SAS_AlvCnt1Val "SAS_AliveCounter1Value";
CM_ SG_ 2223056129 SAS_AnglVal "SAS_AngleValue";
CM_ SG_ 2223056129 SAS_SpdVal "SAS_SpeedValue";
CM_ SG_ 2223056129 SAS_IntSta "SAS_InternalStatus";
CM_ BO_ 2223056130 "[P] Periodic";
CM_ BO_ 1434 "[TP] Transport Protocol";
CM_ BO_ 463 "[P] Periodic";
CM_ SG_ 463 SWRC_Crc3Val "SWRC_CyclicRedundancyCheck3Value";
CM_ SG_ 463 SWRC_AlvCnt3Val "SWRC_AliveCounter3Value";
CM_ SG_ 463 SWRC_CrsSwSta "SWRC_CruiseSwitchStatus";
CM_ SG_ 463 SWRC_CrsMainSwSta "SWRC_CruiseMainSwitchStatus";
CM_ SG_ 463 SWRC_SldMainSwSta "SWRC_SpeedLimiterMainSwitchStatus";
CM_ SG_ 463 SWRC_LFASwSta "SWRC_LFASwitchStatus";
CM_ SG_ 463 SWRC_PaddleUpSwSta "SWRC_PaddleUpSwitchStatus";
CM_ SG_ 463 SWRC_PaddleDnSwSta "SWRC_PaddleDownSwitchStatus";
CM_ SG_ 463 SWRC_Info "SWRC_Information_Type";
CM_ SG_ 463 SWRC_HdpSwSta "SWRC_HDPSwitchStatus";
CM_ SG_ 463 SWRC_HDPSpprtSWVer "SWRC HDP Support Software Version";
CM_ BO_ 1414 "[TP] Transport Protocol";
CM_ BO_ 1412 "[TP] Transport Protocol";
CM_ BO_ 1422 "[TP] Transport Protocol";
CM_ BO_ 1420 "[TP] Transport Protocol";
CM_ BO_ 2382595329 "[P] Periodic";
CM_ SG_ 2382595329 ICSC_Crc3Val "ICSC_CyclicRedundancyCheck3Value";
CM_ SG_ 2382595329 ICSC_AlvCnt3Val "ICSC_AliveCounter3Value";
CM_ SG_ 2382595329 DMIC_OffRdMod "DMIC_OffRoadMode";
CM_ SG_ 2382595329 DMIC_OffRdModActvSta "DMIC_OffRoadModeActivationStatus";
CM_ SG_ 2382595329 DMIC_OffRdModSta "DMIC_OffRoadModeStatus";
CM_ SG_ 2382595329 ESC_LongGrdntPerc "ESC_LongitudinalGradientPercent";
CM_ SG_ 2382595329 ESC_LatGrdntPerc "ESC_LateralGradientPercent";
CM_ SG_ 2382595329 OFFROAD_AppliedSta "OFFROAD_AppliedStatus";
CM_ SG_ 2382595329 OFFROAD_TypeSta "OFFROAD_TypeStatus";
CM_ BO_ 1456 "[TP] Transport Protocol";
CM_ SG_ 1456 GST_RRSAU_RRLBCU_Byte0 "Diag Request for RRSAU, RRLBCU (Exclusion ECU)";
CM_ SG_ 1456 GST_RRSAU_RRLBCU_Byte2 "Diag Request for RRSAU, RRLBCU (Exclusion ECU)";
CM_ SG_ 1456 GST_RRSAU_RRLBCU_Byte3 "Diag Request for RRSAU, RRLBCU (Exclusion ECU)";
CM_ SG_ 1456 GST_RRSAU_RRLBCU_Byte4 "Diag Request for RRSAU, RRLBCU (Exclusion ECU)";
CM_ SG_ 1456 GST_RRSAU_RRLBCU_Byte5 "Diag Request for RRSAU, RRLBCU (Exclusion ECU)";
CM_ SG_ 1456 GST_RRSAU_RRLBCU_Byte6 "Diag Request for RRSAU, RRLBCU (Exclusion ECU)";
CM_ SG_ 1456 GST_RRSAU_RRLBCU_Byte7 "Diag Request for RRSAU, RRLBCU (Exclusion ECU)";
CM_ SG_ 1456 GST_RRSAU_RRLBCU_Byte1 "Diag Request for RRSAU, RRLBCU (Exclusion ECU)";
CM_ BO_ 1457 "[TP] Transport Protocol";
CM_ SG_ 1457 GST_RLSAU_RLLBCU_Byte0 "Diag Request for RLSAU, RLLBCU (Exclusion ECU)";
CM_ SG_ 1457 GST_RLSAU_RLLBCU_Byte2 "Diag Request for RLSAU, RLLBCU (Exclusion ECU)";
CM_ SG_ 1457 GST_RLSAU_RLLBCU_Byte3 "Diag Request for RLSAU, RLLBCU (Exclusion ECU)";
CM_ SG_ 1457 GST_RLSAU_RLLBCU_Byte4 "Diag Request for RLSAU, RLLBCU (Exclusion ECU)";
CM_ SG_ 1457 GST_RLSAU_RLLBCU_Byte5 "Diag Request for RLSAU, RLLBCU (Exclusion ECU)";
CM_ SG_ 1457 GST_RLSAU_RLLBCU_Byte6 "Diag Request for RLSAU, RLLBCU (Exclusion ECU)";
CM_ SG_ 1457 GST_RLSAU_RLLBCU_Byte7 "Diag Request for RLSAU, RLLBCU (Exclusion ECU)";
CM_ SG_ 1457 GST_RLSAU_RLLBCU_Byte1 "Diag Request for RLSAU, RLLBCU (Exclusion ECU)";
CM_ BO_ 2328014852 "[P] Periodic";
CM_ BO_ 1458 "[TP] Transport Protocol";
CM_ SG_ 1458 GST_ATS_Byte0 "Diag Request for ATS";
CM_ SG_ 1458 GST_ATS_Byte2 "Diag Request for ATS";
CM_ SG_ 1458 GST_ATS_Byte3 "Diag Request for ATS";
CM_ SG_ 1458 GST_ATS_Byte4 "Diag Request for ATS";
CM_ SG_ 1458 GST_ATS_Byte5 "Diag Request for ATS";
CM_ SG_ 1458 GST_ATS_Byte6 "Diag Request for ATS";
CM_ SG_ 1458 GST_ATS_Byte7 "Diag Request for ATS";
CM_ SG_ 1458 GST_ATS_Byte1 "Diag Request for ATS";
CM_ BO_ 2328014850 "[P] Periodic";
CM_ SG_ 2328014850 DATC_FnDstStp "DATC_FineDustStep";
CM_ SG_ 2328014850 DATC_OutTempDispC "DATC_OutsideTemperatureDisplay(¡É)";
CM_ SG_ 2328014850 DATC_OutTempDispF "DATC_OutsideTemperatureDisplay(¢µ)";
CM_ SG_ 2328014850 DATC_EngOffReqWaterTemp "Cooling water temperature conditions to request the engine off";
CM_ SG_ 2328014850 DATC_HDPDfg_Sta "DATC_HDPAutoDefog_Status";
CM_ SG_ 2328014850 DATC_HDPSpprtSWVer "DATC_HDPSupportSoftWareVersion";
CM_ SG_ 2328014850 DATC_HDPHumidity_Sta "DATC_HDPHumidity_Status";
CM_ SG_ 2328014850 DATC_FnDstStp_Detail "DATC_FineDustStep_Detail";
CM_ BO_ 2328014851 "[P] Periodic";
CM_ BO_ 2328014849 "[P] Periodic";
CM_ SG_ 2328014849 DATC_Crc17Val "DATC_CyclicRedundancyCheck17Value";
CM_ SG_ 2328014849 DATC_AlvCnt17Val "DATC_AliveCounter17Value";
CM_ SG_ 2328014849 DATC_FrontPwmIsVolt "DATC Blow Motor converted Voltage";
CM_ SG_ 2328014849 DATC_FrontBlwDuty "DATC Blow Motor command duty";
CM_ SG_ 2328014849 DATC_FrontBlwDiagStat "DATC Blow Motor diagnosis state";
CM_ SG_ 2328014849 DATC_BlwrLvl_Ps "DATC_BlowerLevel_Passenger";
CM_ SG_ 2328014849 DATC_BlwrLvl_Rr "DATC_BlowerLevel_Rear";
CM_ SG_ 2328014849 DATC_SwlSta "SRS Warning lamp status";
CM_ BO_ 1464 "[TP] Transport Protocol";
CM_ SG_ 1464 RRSAU_RRLBCU_GST_Byte0 "Diag Response from RRSAU, RRLBCU (Exclusion ECU)";
CM_ SG_ 1464 RRSAU_RRLBCU_GST_Byte2 "Diag Response from RRSAU, RRLBCU (Exclusion ECU)";
CM_ SG_ 1464 RRSAU_RRLBCU_GST_Byte3 "Diag Response from RRSAU, RRLBCU (Exclusion ECU)";
CM_ SG_ 1464 RRSAU_RRLBCU_GST_Byte4 "Diag Response from RRSAU, RRLBCU (Exclusion ECU)";
CM_ SG_ 1464 RRSAU_RRLBCU_GST_Byte5 "Diag Response from RRSAU, RRLBCU (Exclusion ECU)";
CM_ SG_ 1464 RRSAU_RRLBCU_GST_Byte6 "Diag Response from RRSAU, RRLBCU (Exclusion ECU)";
CM_ SG_ 1464 RRSAU_RRLBCU_GST_Byte7 "Diag Response from RRSAU, RRLBCU (Exclusion ECU)";
CM_ SG_ 1464 RRSAU_RRLBCU_GST_Byte1 "Diag Response from RRSAU, RRLBCU (Exclusion ECU)";
CM_ BO_ 1465 "[TP] Transport Protocol";
CM_ SG_ 1465 RLSAU_RLLBCU_GST_Byte0 "Diag Response from RLSAU, RLLBCU (Exclusion ECU)";
CM_ SG_ 1465 RLSAU_RLLBCU_GST_Byte2 "Diag Response from RLSAU, RLLBCU (Exclusion ECU)";
CM_ SG_ 1465 RLSAU_RLLBCU_GST_Byte3 "Diag Response from RLSAU, RLLBCU (Exclusion ECU)";
CM_ SG_ 1465 RLSAU_RLLBCU_GST_Byte4 "Diag Response from RLSAU, RLLBCU (Exclusion ECU)";
CM_ SG_ 1465 RLSAU_RLLBCU_GST_Byte5 "Diag Response from RLSAU, RLLBCU (Exclusion ECU)";
CM_ SG_ 1465 RLSAU_RLLBCU_GST_Byte6 "Diag Response from RLSAU, RLLBCU (Exclusion ECU)";
CM_ SG_ 1465 RLSAU_RLLBCU_GST_Byte7 "Diag Response from RLSAU, RLLBCU (Exclusion ECU)";
CM_ SG_ 1465 RLSAU_RLLBCU_GST_Byte1 "Diag Response from RLSAU, RLLBCU (Exclusion ECU)";
CM_ BO_ 1466 "[TP] Transport Protocol";
CM_ SG_ 1466 ATS_GST_Byte0 "Diag Response from ATS";
CM_ SG_ 1466 ATS_GST_Byte2 "Diag Response from ATS";
CM_ SG_ 1466 ATS_GST_Byte3 "Diag Response from ATS";
CM_ SG_ 1466 ATS_GST_Byte4 "Diag Response from ATS";
CM_ SG_ 1466 ATS_GST_Byte5 "Diag Response from ATS";
CM_ SG_ 1466 ATS_GST_Byte6 "Diag Response from ATS";
CM_ SG_ 1466 ATS_GST_Byte7 "Diag Response from ATS";
CM_ SG_ 1466 ATS_GST_Byte1 "Diag Response from ATS";
CM_ BO_ 491 "[EC] On Event and On Change";
CM_ SG_ 491 DAB_IlluminationVrModeSet "Signal of mood lamp concern about AI voice";
CM_ BO_ 2151682049 "[EW] On Event and On Write";
CM_ SG_ 2151682049 ACU_Crc2Val "ACU_CyclicRedundancyCheck2Value";
CM_ SG_ 2151682049 ACU_AlvCnt2Val "ACU_AliveCounter2Value";
CM_ SG_ 2151682049 ACU_CrshActvSta "ACU_CrashActiveStatus ##2G##ACU - ACU13 - CF_Acu_CshAct";
CM_ SG_ 2151682049 ACU_CrshInfo "ACU Crash Event information";
CM_ SG_ 2151682049 ACU_CrshTyp "Indication of crash type";
CM_ BO_ 550 "[PE] Periodic and On Event";
CM_ SG_ 550 PSS_RL_StSldFwdMvBtn "PSS_RL_SlideForwardMoveButton";
CM_ SG_ 550 PSS_RL_StTltDnMvBtn "PSS_RL_TiltDownMoveButton";
CM_ SG_ 550 PSS_RL_StHRestUpMvBtn "PSS_RL_StHRestUpMvBtn";
CM_ SG_ 550 PSS_RL_StHRestDnMvBtn "PSS_RL_StHRestDnMvBtn";
CM_ SG_ 550 PSS_RL_StHRestFwdMvBtn "PSS_RL_StHRestFwdMvBtn";
CM_ SG_ 550 PSS_RL_StHRestBwdMvBtn "PSS_RL_StHRestBwdMvBtn";
CM_ SG_ 550 PSS_RL_StSldBwdMvBtn "PSS_RL_SlideBackwardMoveButton";
CM_ SG_ 550 PSS_RL_StLegRestUpBtn "PSS_RL_LegUpMoveButton";
CM_ SG_ 550 PSS_RL_StLegRestDnBtn "PSS_RL_LegDownMoveButton";
CM_ SG_ 550 PSS_RL_StLegRestExtFwdBtn "PSS_RL_LegExtFwdMoveButton";
CM_ SG_ 550 PSS_RL_StLegRestExtBwdBtn "PSS_RL_LegExtBwdMoveButton";
CM_ SG_ 550 PSS_RL_StRlxModeBtn "PSS_RL_RelaxModeButton";
CM_ SG_ 550 PSS_RL_StRlxReturnBtn "PSS_RL_RelaxReturnButton";
CM_ SG_ 550 PSS_RL_StRlxTltUpMvBtn "PSS_RL_RelaxTiltUpMoveButton";
CM_ SG_ 550 PSS_RL_StRlxTltDnMvBtn "PSS_RL_RelaxTiltDownMoveButton";
CM_ SG_ 550 PSS_RL_StMnlRlxModeBtn "PSS_RL_MnlRelaxModeButton";
CM_ SG_ 550 PSS_RL_StMnlRlxReturnBtn "PSS_RL_MnlRelaxReturnButton";
CM_ SG_ 550 PSS_RL_StRclFwdMvBtn "PSS_RL_ReclinerForwardMoveButton";
CM_ SG_ 550 PSS_RL_WalkInSwitchSts "PSS_RL_WalkInSwitchStatus";
CM_ SG_ 550 PSS_RL_StRclBwdMvBtn "PSS_RL_ReclinerBackwardMoveButton";
CM_ SG_ 550 PSS_RL_StTltUpMvBtn "PSS_RL_TiltUpMoveButton";
CM_ BO_ 551 "[PE] Periodic and On Event";
CM_ SG_ 551 PSS_RL_StOneTchWlkinCushBtn "PSS_RL_OnetouchWalkinCushMoveButton";
CM_ SG_ 551 PSS_RL_StOneTchWlkinBackBtn "PSS_RL_OnetouchWalkinBackMoveButton";
CM_ SG_ 551 PSS_RL_MomoryP1Cmd "PSS_RL_SeatPositionMemoryP1Request";
CM_ SG_ 551 PSS_RL_MomoryP2Cmd "PSS_RL_SeatPositionMemoryP2Request";
CM_ BO_ 2378399489 "[P] Periodic";
CM_ SG_ 2378399489 GATEWAY_CrcVal "GATEWAY_CyclicRedundancyCheckValue";
CM_ SG_ 2378399489 GATEWAY_AlvCntVal "GATEWAY_AliveCounterValue";
CM_ SG_ 2378399489 GATEWAY_ERT_ACT_STS "ERT_ACT Value";
CM_ BO_ 552 "[PE] Periodic and On Event";
CM_ SG_ 552 PSS_RL_AstHRestFwdMvBtn "PSS_RL_AstStHead Rest UpMoveButton";
CM_ SG_ 552 PSS_RL_AstRclBwdMvBtn "PSS_RL_AstStReclinerBackwardMoveButton";
CM_ SG_ 552 PSS_RL_AstSldFwdMvBtn "PSS_RL_AstStSlideForwardMoveButton";
CM_ SG_ 552 PSS_RL_AstSldBwdMvBtn "PSS_RL_AstStSlideBackwardMoveButton";
CM_ SG_ 552 PSS_RL_AstHgtUpMvBtn "PSS_RL_AstStHeightUpMoveButton";
CM_ SG_ 552 PSS_RL_AstHgtDnMvBtn "PSS_RL_AstStHeightDownMoveButton";
CM_ SG_ 552 PSS_RL_AstHRestBwdMvBtn "PSS_RL_AstStHead Rest DownMoveButton";
CM_ SG_ 552 PSS_RL_AstFRestOpenMvBtn "PSS_RL_AstStFootrestOpenButton";
CM_ SG_ 552 PSS_RL_AstFRestCloseMvBtn "PSS_RL_AstStFootrestCloseButton";
CM_ SG_ 552 PSS_RL_AstHRestUpMvBtn "PSS_RL_AstStHead Rest ForwardMoveButton";
CM_ SG_ 552 PSS_RL_AstHRestDnMvBtn "PSS_RL_AstStHead Rest BackwardMoveButton";
CM_ SG_ 552 PSS_RL_AstRclFwdMvBtn "PSS_RL_AstStReclinerForwardMoveButton";
CM_ BO_ 553 "[PE] Periodic and On Event";
CM_ SG_ 553 PSS_RL_LumbarUpSw "PSS_RL_LumbarUpSwMoveButton";
CM_ SG_ 553 PSS_RL_BolsterDefSw "PSS_RL_BolsterBwdMoveButton";
CM_ SG_ 553 PSS_RL_ActiveSw "PSS_RL_ActiveSw";
CM_ SG_ 553 PSS_RL_LumbarMidSw "PSS_RL_LumbarFwdSwMoveButton";
CM_ SG_ 553 PSS_RL_LumbarLowSw "PSS_RL_LumbarDnSwMoveButton";
CM_ SG_ 553 PSS_RL_LumbarDefSw "PSS_RL_LumbarBwdSwMoveButton";
CM_ SG_ 553 PSS_RL_BolsterInfSw "PSS_RL_BolsterFwdMoveButton";
CM_ BO_ 2449771009 "[P] Periodic";
CM_ SG_ 2449771009 ODS_Crc1Val "ODS_CyclicRedundancyCheck1Value";
CM_ SG_ 2449771009 ODS_AlvCnt1Val "ODS_AliveCounter1Value";
CM_ SG_ 2449771009 ODS_IdVal "ODS_IdValue ##2G##ODS - ODS13 - CR_Ods_ID";
CM_ SG_ 2449771009 ODS_OccClassSta "ODS_OccupantClassificationStatus ##2G##ODS - ODS11 - CR_Wcs_ClassStat";
CM_ SG_ 2449771009 ODS_DiagSta "ODS_SelfDiagnosticStatus ##2G##ODS - ODS11 - CR_Wcs_ErrStat";
CM_ SG_ 2449771009 ODS_SBRClassSta "ODS_SBRClassSta";
CM_ BO_ 2449771010 "[P] Periodic";
CM_ BO_ 2395189505 "[PE] Periodic and On Event";
CM_ SG_ 2395189505 DATC_Crc9Val "DATC_CyclicRedundancyCheck9Value";
CM_ SG_ 2395189505 DATC_AlvCnt9Val "DATC_AliveCounter9Value";
CM_ SG_ 2395189505 DATC_FragranceStrhSta "Fragrance Strength State";
CM_ SG_ 2395189505 DATC_FragranceKindSta "Fragrance Kind State";
CM_ SG_ 2395189505 DATC_AfterBlowOpSta "DATC_AfterBlow Operation Status";
CM_ SG_ 2395189505 DATC_RrBlwDis "DATC_RearBlowerDisplay";
CM_ SG_ 2395189505 DATC_RrClmtAutoOffUSMSta "DATC_RearClimateAutoOffUSMState";
CM_ SG_ 2395189505 DATC_ArClnSysOSD "DATC_AirCleaningSystemOSD";
CM_ SG_ 2395189505 DATC_ArClnStepClr "DATC_AirCleaningStepColor";
CM_ SG_ 2395189505 DATC_ArClnSmblTyp "DATC_AirCleaningSymbolType";
CM_ SG_ 2395189505 DATC_AfterBlowUSMSta "DATC_AfterBlowUSMStatus";
CM_ SG_ 2395189505 DATC_SchdldVntUSMSta "DATC_ScheduledVentilationUSMStatus";
CM_ SG_ 2395189505 DATC_SchdldVntHrSta "DATC_ScheduledVentilationHourStatus";
CM_ SG_ 2395189505 DATC_SchdldVntMinSta "DATC_ScheduledVentilationMinutesStatus";
CM_ BO_ 527 "[PE] Periodic and On Event";
CM_ SG_ 527 ATS_DrvStRseFwdBtn "Drive Seat  RSE Forward Touch Button";
CM_ SG_ 527 ATS_DrvStRseBwdBtn "Drive Seat  RSE Backward Touch Button";
CM_ SG_ 527 ATS_RRRestModBtn "Rear Right Rest Mode Touch Button";
CM_ SG_ 527 ATS_RRResetModBtn "Rear Right Return Mode Touch Button";
CM_ SG_ 527 ATS_RRAvWtcModBtn "Rear Right AV Watching Mode Touch Button";
CM_ SG_ 527 ATS_RRReadingModBtn "Rear Right Reading Mode Touch Button";
CM_ SG_ 527 ATS_RLRestModBtn "Rear Left Rest Mode Touch Button";
CM_ SG_ 527 ATS_RLResetModBtn "Rear Left Return Mode Touch Button";
CM_ BO_ 1616 "[EC] On Event and On Change";
CM_ SG_ 1616 MKBD_IllumiState "Signal to confirm completion transmission of illumination information between MKBD and HU";
CM_ SG_ 1616 MKBD_SeatKeySet "The signal for transmitting Seat Key inputs from MKBD to Seat ECU";
CM_ BO_ 543 "[PE] Periodic and On Event";
CM_ SG_ 543 ATS_AstStSldFwdBtn "Assist Power Seat Slide Forward Rear Walk In Button";
CM_ SG_ 543 ATS_AstStSldBwdBtn "Assist Power Seat Slide Backward Rear Walk In Button";
CM_ SG_ 543 ATS_AstStRclFwdBtn "Assist Power Seat Recline Forward Rear Walk In Button";
CM_ SG_ 543 ATS_AstStRclBwdBtn "Assist Power Seat Recline Backward Rear Walk In Button";
CM_ SG_ 543 ATS_AstStHgtUpBtn "Assist Power Seat Height Up Walk In Button";
CM_ SG_ 543 ATS_AstStHgtDnBtn "Assist Power Seat Height Dn Walk In Button";
CM_ SG_ 543 ATS_AstStHRestUpBtn "Assist Power Seat Head Rest Up Walk In Button";
CM_ SG_ 543 ATS_AstStHRestDnBtn "Assist Power Seat  Head Rest Dn Walk In Button";
CM_ SG_ 543 ATS_AstStHRestFwdBtn "Assist Power Seat Head Rest Forward  Walk In Button";
CM_ SG_ 543 ATS_AstStHRestBwdBtn "Assist Power Seat Head Rest Backward  Walk In Button";
CM_ SG_ 543 ATS_AstStHRestFldBtn "Assist Power Seat Head Rest Folding  Walk In Button";
CM_ SG_ 543 ATS_AstStHRestUnFldBtn "Assist Power Seat Head Rest Unfolding  Walk In Button";
CM_ SG_ 543 ATS_AstStRseFwdBtn "Assist Power Seat RSE Forward  Walk In Button";
CM_ SG_ 543 ATS_AstStRseBwdBtn "Assist Power Seat RSE Backward Walk In Button";
CM_ SG_ 543 ATS_AstStFRestFldBtn "Assist Power Seat Foot Rest Folding Walk In Button";
CM_ SG_ 543 ATS_AstStFRestUnFldBtn "Assist Power Seat Foot Rest Unfolding Walk In Button";
CM_ SG_ 543 ATS_AstTltUpBtn "Assist Power Seat  Tilt Up Walk In Button";
CM_ SG_ 543 ATS_AstTltDnBtn "Assist Power Seat Tilt Down  Walk In Button";
BA_DEF_ BO_  "DiagState" ENUM  "No","Yes";
BA_DEF_ BO_  "DiagResponse" ENUM  "No","Yes";
BA_DEF_ BO_  "DiagRequest" ENUM  "No","Yes";
BA_DEF_ BO_  "TpMessage" ENUM  "No","Yes";
BA_DEF_ BO_  "UsrMsgIDSforwardDeviation" INT 0 100;
BA_DEF_ BO_  "UsrMsgIDSbackwardDeviation" INT 50 1000;
BA_DEF_ BO_  "GenMsgCycleTime" INT 0 2000;
BA_DEF_ BO_  "GenMsgStartDelayTime" INT 0 2000;
BA_DEF_ BO_  "GenMsgSendType" ENUM  "Cyclic","NoMsgSendType";
BA_DEF_ BO_  "GenMsgCycleTimeFast" INT 0 500;
BA_DEF_ BO_  "GenMsgDelayTime" INT 0 20;
BA_DEF_ BO_  "GenMsgILSupport" ENUM  "No","Yes";
BA_DEF_ BO_  "GenMsgNrOfRepetition" INT 0 3;
BA_DEF_ BO_  "NmMessage" ENUM  "No","Yes";
BA_DEF_ BO_  "NWM-Botschaft" ENUM  "No","Yes";
BA_DEF_ BO_  "TpTxIndex" INT 0 65535;
BA_DEF_ BO_  "VFrameFormat" ENUM  "StandardCAN","ExtendedCAN","reserved","reserved","reserved","reserved","reserved","reserved","reserved","reserved","reserved","reserved","reserved","reserved","StandardCAN_FD","ExtendedCAN_FD";
BA_DEF_ SG_  "UserSigValidity" ENUM  "B+","ACC","IG","IG1","IG2","IG3","IG1 or IG2","IG1 or IG3","Undef";
BA_DEF_ SG_  "TimeoutValue" STRING ;
BA_DEF_ SG_  "UsrSigPurpose" ENUM  "Undef","FN","DIAG","DIAG(Req)","DIAG(Res)","DIAG(Phy)","DEV","CCP(Req)","CCP(Res)","NM","TP";
BA_DEF_ SG_  "GenSigStartValue" INT 0 1215752192;
BA_DEF_ SG_  "NetworkRequest" ENUM  "Yes","No";
BA_DEF_ SG_  "NetworkRequestHoldingTime" INT 0 65535;
BA_DEF_ SG_  "Description" STRING ;
BA_DEF_ SG_  "Version" STRING ;
BA_DEF_ SG_  "GenSigEnvVarType" ENUM  "Int","Float","Undef";
BA_DEF_ SG_  "GenSigSendType" ENUM  "Cyclic","OnWrite","OnWriteWithRepetition","OnChange","OnChangeWithRepetition","IfActive","IfActiveWithRepetition","NoSigSendType","OnChangeAndIfActive","OnChangeAndIfActiveWithRepetition";
BA_DEF_ SG_  "GwSigLatencyTime" INT 0 65536;
BA_DEF_ SG_  "GwSigMissingSourceType" ENUM  "Undef","OldValue","DefaultValue","InitialValue";
BA_DEF_ SG_  "NWM-WakeupAllowed" ENUM  "<n.a.>";
BA_DEF_ SG_  "RoutingFactor" INT 1 1215752192;
BA_DEF_ SG_  "SystemSignalLongSymbol" STRING ;
BA_DEF_REL_ BU_SG_REL_  "GenSigTimeoutTime" INT 0 7000;
BA_DEF_DEF_  "DiagState" "No";
BA_DEF_DEF_  "DiagResponse" "No";
BA_DEF_DEF_  "DiagRequest" "No";
BA_DEF_DEF_  "TpMessage" "No";
BA_DEF_DEF_  "UsrMsgIDSforwardDeviation" 10;
BA_DEF_DEF_  "UsrMsgIDSbackwardDeviation" 100;
BA_DEF_DEF_  "GenMsgCycleTime" 200;
BA_DEF_DEF_  "GenMsgStartDelayTime" 0;
BA_DEF_DEF_  "GenMsgSendType" "NoMsgSendType";
BA_DEF_DEF_  "GenMsgCycleTimeFast" 40;
BA_DEF_DEF_  "GenMsgDelayTime" 20;
BA_DEF_DEF_  "GenMsgILSupport" "Yes";
BA_DEF_DEF_  "GenMsgNrOfRepetition" 3;
BA_DEF_DEF_  "NmMessage" "No";
BA_DEF_DEF_  "NWM-Botschaft" "No";
BA_DEF_DEF_  "TpTxIndex" 0;
BA_DEF_DEF_  "VFrameFormat" "StandardCAN";
BA_DEF_DEF_  "UserSigValidity" "IG";
BA_DEF_DEF_  "TimeoutValue" "";
BA_DEF_DEF_  "UsrSigPurpose" "FN";
BA_DEF_DEF_  "GenSigStartValue" 0;
BA_DEF_DEF_  "NetworkRequest" "No";
BA_DEF_DEF_  "NetworkRequestHoldingTime" 0;
BA_DEF_DEF_  "Description" "";
BA_DEF_DEF_  "Version" "";
BA_DEF_DEF_  "GenSigEnvVarType" "Undef";
BA_DEF_DEF_  "GenSigSendType" "NoSigSendType";
BA_DEF_DEF_  "GwSigLatencyTime" 40;
BA_DEF_DEF_  "GwSigMissingSourceType" "Undef";
BA_DEF_DEF_  "NWM-WakeupAllowed" "<n.a.>";
BA_DEF_DEF_  "RoutingFactor" 1;
BA_DEF_DEF_REL_ "GenSigTimeoutTime" 500;
BA_DEF_DEF_  "SystemSignalLongSymbol" "";
BA_ "TpTxIndex" BO_ 1518 108;
BA_ "TpMessage" BO_ 1518 1;
BA_ "GenMsgILSupport" BO_ 1518 0;
BA_ "DiagResponse" BO_ 1518 1;
BA_ "GenMsgNrOfRepetition" BO_ 1518 0;
BA_ "GenMsgCycleTimeFast" BO_ 1518 0;
BA_ "GenMsgCycleTime" BO_ 1518 0;
BA_ "TpTxIndex" BO_ 1426 55;
BA_ "TpMessage" BO_ 1426 1;
BA_ "GenMsgILSupport" BO_ 1426 0;
BA_ "DiagRequest" BO_ 1426 1;
BA_ "GenMsgNrOfRepetition" BO_ 1426 0;
BA_ "GenMsgCycleTimeFast" BO_ 1426 0;
BA_ "GenMsgCycleTime" BO_ 1426 0;
BA_ "GenMsgSendType" BO_ 479 0;
BA_ "VFrameFormat" BO_ 2223056129 1;
BA_ "GenMsgNrOfRepetition" BO_ 2223056129 0;
BA_ "GenMsgCycleTimeFast" BO_ 2223056129 0;
BA_ "GenMsgCycleTime" BO_ 2223056129 50;
BA_ "GenMsgSendType" BO_ 2223056129 0;
BA_ "VFrameFormat" BO_ 2223056130 1;
BA_ "GenMsgNrOfRepetition" BO_ 2223056130 0;
BA_ "GenMsgCycleTimeFast" BO_ 2223056130 0;
BA_ "GenMsgCycleTime" BO_ 2223056130 50;
BA_ "GenMsgSendType" BO_ 2223056130 0;
BA_ "TpTxIndex" BO_ 1434 55;
BA_ "TpMessage" BO_ 1434 1;
BA_ "GenMsgILSupport" BO_ 1434 0;
BA_ "DiagResponse" BO_ 1434 1;
BA_ "GenMsgNrOfRepetition" BO_ 1434 0;
BA_ "GenMsgCycleTimeFast" BO_ 1434 0;
BA_ "GenMsgCycleTime" BO_ 1434 0;
BA_ "GenMsgDelayTime" BO_ 463 0;
BA_ "GenMsgNrOfRepetition" BO_ 463 0;
BA_ "GenMsgCycleTimeFast" BO_ 463 0;
BA_ "GenMsgCycleTime" BO_ 463 20;
BA_ "GenMsgSendType" BO_ 463 0;
BA_ "TpTxIndex" BO_ 1414 95;
BA_ "TpMessage" BO_ 1414 1;
BA_ "GenMsgILSupport" BO_ 1414 0;
BA_ "DiagRequest" BO_ 1414 1;
BA_ "GenMsgNrOfRepetition" BO_ 1414 0;
BA_ "GenMsgCycleTimeFast" BO_ 1414 0;
BA_ "GenMsgCycleTime" BO_ 1414 0;
BA_ "TpTxIndex" BO_ 1412 233;
BA_ "TpMessage" BO_ 1412 1;
BA_ "GenMsgILSupport" BO_ 1412 0;
BA_ "DiagRequest" BO_ 1412 1;
BA_ "GenMsgNrOfRepetition" BO_ 1412 0;
BA_ "GenMsgCycleTimeFast" BO_ 1412 0;
BA_ "GenMsgCycleTime" BO_ 1412 0;
BA_ "TpTxIndex" BO_ 1422 95;
BA_ "TpMessage" BO_ 1422 1;
BA_ "GenMsgILSupport" BO_ 1422 0;
BA_ "DiagResponse" BO_ 1422 1;
BA_ "GenMsgNrOfRepetition" BO_ 1422 0;
BA_ "GenMsgCycleTimeFast" BO_ 1422 0;
BA_ "GenMsgCycleTime" BO_ 1422 0;
BA_ "TpTxIndex" BO_ 1420 233;
BA_ "TpMessage" BO_ 1420 1;
BA_ "GenMsgILSupport" BO_ 1420 0;
BA_ "DiagResponse" BO_ 1420 1;
BA_ "GenMsgNrOfRepetition" BO_ 1420 0;
BA_ "GenMsgCycleTimeFast" BO_ 1420 0;
BA_ "GenMsgCycleTime" BO_ 1420 0;
BA_ "VFrameFormat" BO_ 2382595329 1;
BA_ "GenMsgNrOfRepetition" BO_ 2382595329 0;
BA_ "GenMsgCycleTimeFast" BO_ 2382595329 0;
BA_ "GenMsgSendType" BO_ 2382595329 0;
BA_ "TpTxIndex" BO_ 1456 210;
BA_ "TpMessage" BO_ 1456 1;
BA_ "GenMsgILSupport" BO_ 1456 0;
BA_ "DiagRequest" BO_ 1456 1;
BA_ "GenMsgNrOfRepetition" BO_ 1456 0;
BA_ "GenMsgCycleTimeFast" BO_ 1456 0;
BA_ "GenMsgCycleTime" BO_ 1456 0;
BA_ "TpTxIndex" BO_ 1457 211;
BA_ "TpMessage" BO_ 1457 1;
BA_ "GenMsgILSupport" BO_ 1457 0;
BA_ "DiagRequest" BO_ 1457 1;
BA_ "GenMsgNrOfRepetition" BO_ 1457 0;
BA_ "GenMsgCycleTimeFast" BO_ 1457 0;
BA_ "GenMsgCycleTime" BO_ 1457 0;
BA_ "VFrameFormat" BO_ 2328014852 1;
BA_ "GenMsgNrOfRepetition" BO_ 2328014852 0;
BA_ "GenMsgCycleTimeFast" BO_ 2328014852 0;
BA_ "GenMsgSendType" BO_ 2328014852 0;
BA_ "TpTxIndex" BO_ 1458 212;
BA_ "TpMessage" BO_ 1458 1;
BA_ "GenMsgILSupport" BO_ 1458 0;
BA_ "DiagRequest" BO_ 1458 1;
BA_ "GenMsgNrOfRepetition" BO_ 1458 0;
BA_ "GenMsgCycleTimeFast" BO_ 1458 0;
BA_ "GenMsgCycleTime" BO_ 1458 0;
BA_ "VFrameFormat" BO_ 2328014850 1;
BA_ "GenMsgNrOfRepetition" BO_ 2328014850 0;
BA_ "GenMsgCycleTimeFast" BO_ 2328014850 0;
BA_ "GenMsgSendType" BO_ 2328014850 0;
BA_ "VFrameFormat" BO_ 2328014851 1;
BA_ "GenMsgNrOfRepetition" BO_ 2328014851 0;
BA_ "GenMsgCycleTimeFast" BO_ 2328014851 0;
BA_ "GenMsgSendType" BO_ 2328014851 0;
BA_ "VFrameFormat" BO_ 2328014849 1;
BA_ "GenMsgNrOfRepetition" BO_ 2328014849 0;
BA_ "GenMsgCycleTimeFast" BO_ 2328014849 0;
BA_ "GenMsgSendType" BO_ 2328014849 0;
BA_ "TpTxIndex" BO_ 1464 210;
BA_ "TpMessage" BO_ 1464 1;
BA_ "GenMsgILSupport" BO_ 1464 0;
BA_ "DiagResponse" BO_ 1464 1;
BA_ "GenMsgNrOfRepetition" BO_ 1464 0;
BA_ "GenMsgCycleTimeFast" BO_ 1464 0;
BA_ "GenMsgCycleTime" BO_ 1464 0;
BA_ "TpTxIndex" BO_ 1465 211;
BA_ "TpMessage" BO_ 1465 1;
BA_ "GenMsgILSupport" BO_ 1465 0;
BA_ "DiagResponse" BO_ 1465 1;
BA_ "GenMsgNrOfRepetition" BO_ 1465 0;
BA_ "GenMsgCycleTimeFast" BO_ 1465 0;
BA_ "GenMsgCycleTime" BO_ 1465 0;
BA_ "TpTxIndex" BO_ 1466 212;
BA_ "TpMessage" BO_ 1466 1;
BA_ "GenMsgILSupport" BO_ 1466 0;
BA_ "DiagResponse" BO_ 1466 1;
BA_ "GenMsgNrOfRepetition" BO_ 1466 0;
BA_ "GenMsgCycleTimeFast" BO_ 1466 0;
BA_ "GenMsgCycleTime" BO_ 1466 0;
BA_ "GenMsgCycleTime" BO_ 491 0;
BA_ "VFrameFormat" BO_ 2151682049 1;
BA_ "GenMsgDelayTime" BO_ 2151682049 10;
BA_ "GenMsgNrOfRepetition" BO_ 2151682049 0;
BA_ "GenMsgCycleTime" BO_ 2151682049 0;
BA_ "GenMsgSendType" BO_ 550 0;
BA_ "GenMsgSendType" BO_ 551 0;
BA_ "VFrameFormat" BO_ 2378399489 1;
BA_ "GenMsgNrOfRepetition" BO_ 2378399489 0;
BA_ "GenMsgCycleTimeFast" BO_ 2378399489 0;
BA_ "GenMsgCycleTime" BO_ 2378399489 100;
BA_ "GenMsgSendType" BO_ 2378399489 0;
BA_ "GenMsgSendType" BO_ 552 0;
BA_ "GenMsgSendType" BO_ 553 0;
BA_ "VFrameFormat" BO_ 2449771009 1;
BA_ "GenMsgNrOfRepetition" BO_ 2449771009 0;
BA_ "GenMsgCycleTimeFast" BO_ 2449771009 0;
BA_ "GenMsgCycleTime" BO_ 2449771009 1000;
BA_ "GenMsgSendType" BO_ 2449771009 0;
BA_ "VFrameFormat" BO_ 2449771010 1;
BA_ "GenMsgNrOfRepetition" BO_ 2449771010 0;
BA_ "GenMsgCycleTimeFast" BO_ 2449771010 0;
BA_ "GenMsgCycleTime" BO_ 2449771010 1000;
BA_ "GenMsgSendType" BO_ 2449771010 0;
BA_ "VFrameFormat" BO_ 2395189505 1;
BA_ "GenMsgSendType" BO_ 2395189505 0;
BA_ "GenMsgSendType" BO_ 527 0;
BA_ "GenMsgCycleTime" BO_ 1616 0;
BA_ "GenMsgSendType" BO_ 543 0;
BA_ "Version" SG_ 1518 APSS_GST_Byte0 "22.07.01";
BA_ "NetworkRequestHoldingTime" SG_ 1518 APSS_GST_Byte0 5000;
BA_ "NetworkRequest" SG_ 1518 APSS_GST_Byte0 0;
BA_ "UserSigValidity" SG_ 1518 APSS_GST_Byte0 0;
BA_ "UsrSigPurpose" SG_ 1518 APSS_GST_Byte0 4;
BA_ "Description" SG_ 1518 APSS_GST_Byte0 "TP Index : 108";
BA_ "Version" SG_ 1518 APSS_GST_Byte2 "22.07.01";
BA_ "NetworkRequestHoldingTime" SG_ 1518 APSS_GST_Byte2 5000;
BA_ "NetworkRequest" SG_ 1518 APSS_GST_Byte2 0;
BA_ "UserSigValidity" SG_ 1518 APSS_GST_Byte2 0;
BA_ "UsrSigPurpose" SG_ 1518 APSS_GST_Byte2 4;
BA_ "Description" SG_ 1518 APSS_GST_Byte2 "TP Index : 108";
BA_ "Version" SG_ 1518 APSS_GST_Byte3 "22.07.01";
BA_ "NetworkRequestHoldingTime" SG_ 1518 APSS_GST_Byte3 5000;
BA_ "NetworkRequest" SG_ 1518 APSS_GST_Byte3 0;
BA_ "UserSigValidity" SG_ 1518 APSS_GST_Byte3 0;
BA_ "UsrSigPurpose" SG_ 1518 APSS_GST_Byte3 4;
BA_ "Description" SG_ 1518 APSS_GST_Byte3 "TP Index : 108";
BA_ "Version" SG_ 1518 APSS_GST_Byte4 "22.07.01";
BA_ "NetworkRequestHoldingTime" SG_ 1518 APSS_GST_Byte4 5000;
BA_ "NetworkRequest" SG_ 1518 APSS_GST_Byte4 0;
BA_ "UserSigValidity" SG_ 1518 APSS_GST_Byte4 0;
BA_ "UsrSigPurpose" SG_ 1518 APSS_GST_Byte4 4;
BA_ "Description" SG_ 1518 APSS_GST_Byte4 "TP Index : 108";
BA_ "Version" SG_ 1518 APSS_GST_Byte5 "22.07.01";
BA_ "NetworkRequestHoldingTime" SG_ 1518 APSS_GST_Byte5 5000;
BA_ "NetworkRequest" SG_ 1518 APSS_GST_Byte5 0;
BA_ "UserSigValidity" SG_ 1518 APSS_GST_Byte5 0;
BA_ "UsrSigPurpose" SG_ 1518 APSS_GST_Byte5 4;
BA_ "Description" SG_ 1518 APSS_GST_Byte5 "TP Index : 108";
BA_ "Version" SG_ 1518 APSS_GST_Byte6 "22.07.01";
BA_ "NetworkRequestHoldingTime" SG_ 1518 APSS_GST_Byte6 5000;
BA_ "NetworkRequest" SG_ 1518 APSS_GST_Byte6 0;
BA_ "UserSigValidity" SG_ 1518 APSS_GST_Byte6 0;
BA_ "UsrSigPurpose" SG_ 1518 APSS_GST_Byte6 4;
BA_ "Description" SG_ 1518 APSS_GST_Byte6 "TP Index : 108";
BA_ "Version" SG_ 1518 APSS_GST_Byte7 "22.07.01";
BA_ "NetworkRequestHoldingTime" SG_ 1518 APSS_GST_Byte7 5000;
BA_ "NetworkRequest" SG_ 1518 APSS_GST_Byte7 0;
BA_ "UserSigValidity" SG_ 1518 APSS_GST_Byte7 0;
BA_ "UsrSigPurpose" SG_ 1518 APSS_GST_Byte7 4;
BA_ "Description" SG_ 1518 APSS_GST_Byte7 "TP Index : 108";
BA_ "Version" SG_ 1518 APSS_GST_Byte1 "22.07.01";
BA_ "NetworkRequestHoldingTime" SG_ 1518 APSS_GST_Byte1 5000;
BA_ "NetworkRequest" SG_ 1518 APSS_GST_Byte1 0;
BA_ "UserSigValidity" SG_ 1518 APSS_GST_Byte1 0;
BA_ "UsrSigPurpose" SG_ 1518 APSS_GST_Byte1 4;
BA_ "Description" SG_ 1518 APSS_GST_Byte1 "TP Index : 108";
BA_ "Version" SG_ 1426 GST_RCM_Byte0 "20.11.01";
BA_ "NetworkRequestHoldingTime" SG_ 1426 GST_RCM_Byte0 5000;
BA_ "NetworkRequest" SG_ 1426 GST_RCM_Byte0 0;
BA_ "UserSigValidity" SG_ 1426 GST_RCM_Byte0 0;
BA_ "UsrSigPurpose" SG_ 1426 GST_RCM_Byte0 3;
BA_ "Description" SG_ 1426 GST_RCM_Byte0 "TP Index : 55";
BA_ "Version" SG_ 1426 GST_RCM_Byte2 "20.11.01";
BA_ "NetworkRequestHoldingTime" SG_ 1426 GST_RCM_Byte2 5000;
BA_ "NetworkRequest" SG_ 1426 GST_RCM_Byte2 0;
BA_ "UserSigValidity" SG_ 1426 GST_RCM_Byte2 0;
BA_ "UsrSigPurpose" SG_ 1426 GST_RCM_Byte2 3;
BA_ "Description" SG_ 1426 GST_RCM_Byte2 "TP Index : 55";
BA_ "Version" SG_ 1426 GST_RCM_Byte3 "20.11.01";
BA_ "NetworkRequestHoldingTime" SG_ 1426 GST_RCM_Byte3 5000;
BA_ "NetworkRequest" SG_ 1426 GST_RCM_Byte3 0;
BA_ "UserSigValidity" SG_ 1426 GST_RCM_Byte3 0;
BA_ "UsrSigPurpose" SG_ 1426 GST_RCM_Byte3 3;
BA_ "Description" SG_ 1426 GST_RCM_Byte3 "TP Index : 55";
BA_ "Version" SG_ 1426 GST_RCM_Byte4 "20.11.01";
BA_ "NetworkRequestHoldingTime" SG_ 1426 GST_RCM_Byte4 5000;
BA_ "NetworkRequest" SG_ 1426 GST_RCM_Byte4 0;
BA_ "UserSigValidity" SG_ 1426 GST_RCM_Byte4 0;
BA_ "UsrSigPurpose" SG_ 1426 GST_RCM_Byte4 3;
BA_ "Description" SG_ 1426 GST_RCM_Byte4 "TP Index : 55";
BA_ "Version" SG_ 1426 GST_RCM_Byte5 "20.11.01";
BA_ "NetworkRequestHoldingTime" SG_ 1426 GST_RCM_Byte5 5000;
BA_ "NetworkRequest" SG_ 1426 GST_RCM_Byte5 0;
BA_ "UserSigValidity" SG_ 1426 GST_RCM_Byte5 0;
BA_ "UsrSigPurpose" SG_ 1426 GST_RCM_Byte5 3;
BA_ "Description" SG_ 1426 GST_RCM_Byte5 "TP Index : 55";
BA_ "Version" SG_ 1426 GST_RCM_Byte6 "20.11.01";
BA_ "NetworkRequestHoldingTime" SG_ 1426 GST_RCM_Byte6 5000;
BA_ "NetworkRequest" SG_ 1426 GST_RCM_Byte6 0;
BA_ "UserSigValidity" SG_ 1426 GST_RCM_Byte6 0;
BA_ "UsrSigPurpose" SG_ 1426 GST_RCM_Byte6 3;
BA_ "Description" SG_ 1426 GST_RCM_Byte6 "TP Index : 55";
BA_ "Version" SG_ 1426 GST_RCM_Byte7 "20.11.01";
BA_ "NetworkRequestHoldingTime" SG_ 1426 GST_RCM_Byte7 5000;
BA_ "NetworkRequest" SG_ 1426 GST_RCM_Byte7 0;
BA_ "UserSigValidity" SG_ 1426 GST_RCM_Byte7 0;
BA_ "UsrSigPurpose" SG_ 1426 GST_RCM_Byte7 3;
BA_ "Description" SG_ 1426 GST_RCM_Byte7 "TP Index : 55";
BA_ "Version" SG_ 1426 GST_RCM_Byte1 "20.11.01";
BA_ "NetworkRequestHoldingTime" SG_ 1426 GST_RCM_Byte1 5000;
BA_ "NetworkRequest" SG_ 1426 GST_RCM_Byte1 0;
BA_ "UserSigValidity" SG_ 1426 GST_RCM_Byte1 0;
BA_ "UsrSigPurpose" SG_ 1426 GST_RCM_Byte1 3;
BA_ "Description" SG_ 1426 GST_RCM_Byte1 "TP Index : 55";
BA_ "Version" SG_ 479 ALBCU_LumbarUpDis "20.10.02";
BA_ "RoutingFactor" SG_ 479 ALBCU_LumbarUpDis 0;
BA_ "NetworkRequestHoldingTime" SG_ 479 ALBCU_LumbarUpDis 5000;
BA_ "NetworkRequest" SG_ 479 ALBCU_LumbarUpDis 0;
BA_ "UserSigValidity" SG_ 479 ALBCU_LumbarUpDis 1;
BA_ "GenSigSendType" SG_ 479 ALBCU_LumbarUpDis 4;
BA_ "Description" SG_ 479 ALBCU_LumbarUpDis "This signal is used to display the seat movement to AVN";
BA_ "Version" SG_ 479 ALBCU_BolsterDefDis "20.10.02";
BA_ "RoutingFactor" SG_ 479 ALBCU_BolsterDefDis 0;
BA_ "NetworkRequestHoldingTime" SG_ 479 ALBCU_BolsterDefDis 5000;
BA_ "NetworkRequest" SG_ 479 ALBCU_BolsterDefDis 0;
BA_ "UserSigValidity" SG_ 479 ALBCU_BolsterDefDis 1;
BA_ "GenSigSendType" SG_ 479 ALBCU_BolsterDefDis 4;
BA_ "Description" SG_ 479 ALBCU_BolsterDefDis "This signal is used to display the seat movement to AVN";
BA_ "Version" SG_ 479 ALBCU_CushInfDis "20.10.02";
BA_ "RoutingFactor" SG_ 479 ALBCU_CushInfDis 0;
BA_ "NetworkRequestHoldingTime" SG_ 479 ALBCU_CushInfDis 5000;
BA_ "NetworkRequest" SG_ 479 ALBCU_CushInfDis 0;
BA_ "UserSigValidity" SG_ 479 ALBCU_CushInfDis 1;
BA_ "GenSigSendType" SG_ 479 ALBCU_CushInfDis 4;
BA_ "Description" SG_ 479 ALBCU_CushInfDis "This signal is used to display the seat movement to AVN";
BA_ "Version" SG_ 479 ALBCU_CushDefDis "20.10.02";
BA_ "RoutingFactor" SG_ 479 ALBCU_CushDefDis 0;
BA_ "NetworkRequestHoldingTime" SG_ 479 ALBCU_CushDefDis 5000;
BA_ "NetworkRequest" SG_ 479 ALBCU_CushDefDis 0;
BA_ "UserSigValidity" SG_ 479 ALBCU_CushDefDis 1;
BA_ "GenSigSendType" SG_ 479 ALBCU_CushDefDis 4;
BA_ "Description" SG_ 479 ALBCU_CushDefDis "This signal is used to display the seat movement to AVN";
BA_ "Version" SG_ 479 ALBCU_ActiveDis "20.10.02";
BA_ "RoutingFactor" SG_ 479 ALBCU_ActiveDis 0;
BA_ "NetworkRequestHoldingTime" SG_ 479 ALBCU_ActiveDis 5000;
BA_ "NetworkRequest" SG_ 479 ALBCU_ActiveDis 0;
BA_ "UserSigValidity" SG_ 479 ALBCU_ActiveDis 1;
BA_ "GenSigSendType" SG_ 479 ALBCU_ActiveDis 4;
BA_ "Description" SG_ 479 ALBCU_ActiveDis "Display Air support mode to AVN";
BA_ "Version" SG_ 479 ALBCU_DrvModUSMSta "20.10.02";
BA_ "RoutingFactor" SG_ 479 ALBCU_DrvModUSMSta 0;
BA_ "NetworkRequestHoldingTime" SG_ 479 ALBCU_DrvModUSMSta 5000;
BA_ "NetworkRequest" SG_ 479 ALBCU_DrvModUSMSta 0;
BA_ "UserSigValidity" SG_ 479 ALBCU_DrvModUSMSta 1;
BA_ "GenSigSendType" SG_ 479 ALBCU_DrvModUSMSta 4;
BA_ "Description" SG_ 479 ALBCU_DrvModUSMSta "Drivemode interlock signal feedback to AVN";
BA_ "Version" SG_ 479 ALBCU_LumbarMidDis "20.10.02";
BA_ "RoutingFactor" SG_ 479 ALBCU_LumbarMidDis 0;
BA_ "NetworkRequestHoldingTime" SG_ 479 ALBCU_LumbarMidDis 5000;
BA_ "NetworkRequest" SG_ 479 ALBCU_LumbarMidDis 0;
BA_ "UserSigValidity" SG_ 479 ALBCU_LumbarMidDis 1;
BA_ "GenSigSendType" SG_ 479 ALBCU_LumbarMidDis 4;
BA_ "Description" SG_ 479 ALBCU_LumbarMidDis "This signal is used to display the seat movement to AVN";
BA_ "Version" SG_ 479 ALBCU_ActiveStrSta "20.10.02";
BA_ "RoutingFactor" SG_ 479 ALBCU_ActiveStrSta 0;
BA_ "NetworkRequestHoldingTime" SG_ 479 ALBCU_ActiveStrSta 5000;
BA_ "NetworkRequest" SG_ 479 ALBCU_ActiveStrSta 0;
BA_ "UserSigValidity" SG_ 479 ALBCU_ActiveStrSta 1;
BA_ "GenSigSendType" SG_ 479 ALBCU_ActiveStrSta 4;
BA_ "Description" SG_ 479 ALBCU_ActiveStrSta "Air support mode strength Signal feedback to AVN";
BA_ "Version" SG_ 479 ALBCU_ActiveTimeSta "20.10.02";
BA_ "RoutingFactor" SG_ 479 ALBCU_ActiveTimeSta 0;
BA_ "NetworkRequestHoldingTime" SG_ 479 ALBCU_ActiveTimeSta 5000;
BA_ "NetworkRequest" SG_ 479 ALBCU_ActiveTimeSta 0;
BA_ "UserSigValidity" SG_ 479 ALBCU_ActiveTimeSta 1;
BA_ "GenSigSendType" SG_ 479 ALBCU_ActiveTimeSta 4;
BA_ "Description" SG_ 479 ALBCU_ActiveTimeSta "Air support refresh time Signal feedback to AVN";
BA_ "Version" SG_ 479 ALBCU_CellOpt "20.10.02";
BA_ "RoutingFactor" SG_ 479 ALBCU_CellOpt 0;
BA_ "NetworkRequestHoldingTime" SG_ 479 ALBCU_CellOpt 5000;
BA_ "NetworkRequest" SG_ 479 ALBCU_CellOpt 0;
BA_ "UserSigValidity" SG_ 479 ALBCU_CellOpt 0;
BA_ "GenSigSendType" SG_ 479 ALBCU_CellOpt 4;
BA_ "Description" SG_ 479 ALBCU_CellOpt "Seat air pressure system spec data signal 

(3Cell:Lumber support / 5Cell:Lumber bolster / 7Cell:Lumber bolster coushion)";
BA_ "Version" SG_ 479 ALBCU_BodySpprtSta "20.10.02";
BA_ "RoutingFactor" SG_ 479 ALBCU_BodySpprtSta 0;
BA_ "UserSigValidity" SG_ 479 ALBCU_BodySpprtSta 1;
BA_ "GenSigSendType" SG_ 479 ALBCU_BodySpprtSta 4;
BA_ "Description" SG_ 479 ALBCU_BodySpprtSta "Seat Body Support Function USM R Value";
BA_ "Version" SG_ 479 ALBCU_BodySpprtDis "20.10.02";
BA_ "RoutingFactor" SG_ 479 ALBCU_BodySpprtDis 0;
BA_ "UserSigValidity" SG_ 479 ALBCU_BodySpprtDis 1;
BA_ "GenSigSendType" SG_ 479 ALBCU_BodySpprtDis 4;
BA_ "Description" SG_ 479 ALBCU_BodySpprtDis "Seat Body Support Function Display Request";
BA_ "Version" SG_ 479 ALBCU_SmartCtrl_Set_Rvalue "21.12.05";
BA_ "RoutingFactor" SG_ 479 ALBCU_SmartCtrl_Set_Rvalue 0;
BA_ "UserSigValidity" SG_ 479 ALBCU_SmartCtrl_Set_Rvalue 1;
BA_ "GenSigSendType" SG_ 479 ALBCU_SmartCtrl_Set_Rvalue 4;
BA_ "Version" SG_ 479 ALBCU_MoodTrpyRValueSet "23.02.11";
BA_ "RoutingFactor" SG_ 479 ALBCU_MoodTrpyRValueSet 0;
BA_ "NetworkRequestHoldingTime" SG_ 479 ALBCU_MoodTrpyRValueSet 5000;
BA_ "NetworkRequest" SG_ 479 ALBCU_MoodTrpyRValueSet 0;
BA_ "UserSigValidity" SG_ 479 ALBCU_MoodTrpyRValueSet 3;
BA_ "GenSigSendType" SG_ 479 ALBCU_MoodTrpyRValueSet 4;
BA_ "Description" SG_ 479 ALBCU_MoodTrpyRValueSet "Passenger Seat Mood Therapy R Value";
BA_ "Version" SG_ 479 ALBCU_MoodTrpyCareSta "23.02.11";
BA_ "RoutingFactor" SG_ 479 ALBCU_MoodTrpyCareSta 0;
BA_ "NetworkRequestHoldingTime" SG_ 479 ALBCU_MoodTrpyCareSta 5000;
BA_ "NetworkRequest" SG_ 479 ALBCU_MoodTrpyCareSta 0;
BA_ "UserSigValidity" SG_ 479 ALBCU_MoodTrpyCareSta 3;
BA_ "GenSigSendType" SG_ 479 ALBCU_MoodTrpyCareSta 4;
BA_ "Description" SG_ 479 ALBCU_MoodTrpyCareSta "Passenger Seat Mood Therapy Care Mode R Value";
BA_ "Version" SG_ 479 ALBCU_LumbarLowDis "20.10.02";
BA_ "RoutingFactor" SG_ 479 ALBCU_LumbarLowDis 0;
BA_ "NetworkRequestHoldingTime" SG_ 479 ALBCU_LumbarLowDis 5000;
BA_ "NetworkRequest" SG_ 479 ALBCU_LumbarLowDis 0;
BA_ "UserSigValidity" SG_ 479 ALBCU_LumbarLowDis 1;
BA_ "GenSigSendType" SG_ 479 ALBCU_LumbarLowDis 4;
BA_ "Description" SG_ 479 ALBCU_LumbarLowDis "This signal is used to display the seat movement to AVN";
BA_ "Version" SG_ 479 ALBCU_MoodTrpyComfSta "23.02.11";
BA_ "RoutingFactor" SG_ 479 ALBCU_MoodTrpyComfSta 0;
BA_ "NetworkRequestHoldingTime" SG_ 479 ALBCU_MoodTrpyComfSta 5000;
BA_ "NetworkRequest" SG_ 479 ALBCU_MoodTrpyComfSta 0;
BA_ "UserSigValidity" SG_ 479 ALBCU_MoodTrpyComfSta 3;
BA_ "GenSigSendType" SG_ 479 ALBCU_MoodTrpyComfSta 4;
BA_ "Description" SG_ 479 ALBCU_MoodTrpyComfSta "Passenger Seat Mood Therapy Comfort Mode R Value";
BA_ "Version" SG_ 479 ALBCU_CushLeftPSnsrVtg "23.10.04";
BA_ "RoutingFactor" SG_ 479 ALBCU_CushLeftPSnsrVtg 0;
BA_ "NetworkRequestHoldingTime" SG_ 479 ALBCU_CushLeftPSnsrVtg 5000;
BA_ "NetworkRequest" SG_ 479 ALBCU_CushLeftPSnsrVtg 0;
BA_ "UserSigValidity" SG_ 479 ALBCU_CushLeftPSnsrVtg 0;
BA_ "GenSigSendType" SG_ 479 ALBCU_CushLeftPSnsrVtg 4;
BA_ "Description" SG_ 479 ALBCU_CushLeftPSnsrVtg "ALBCU Cushion Left Pressure Sensor Voltage Value (Unit : V / 0.1V per 1 Value / Min Value : 0.2V / Max Value °ª : 4.8V)";
BA_ "Version" SG_ 479 ALBCU_CushRightPSnsrVtg "23.10.04";
BA_ "RoutingFactor" SG_ 479 ALBCU_CushRightPSnsrVtg 0;
BA_ "NetworkRequestHoldingTime" SG_ 479 ALBCU_CushRightPSnsrVtg 5000;
BA_ "NetworkRequest" SG_ 479 ALBCU_CushRightPSnsrVtg 0;
BA_ "UserSigValidity" SG_ 479 ALBCU_CushRightPSnsrVtg 0;
BA_ "GenSigSendType" SG_ 479 ALBCU_CushRightPSnsrVtg 4;
BA_ "Description" SG_ 479 ALBCU_CushRightPSnsrVtg "ALBCU Cushion Right Pressure Sensor Voltage Value (Unit : V / 0.1V per 1 Value / Min Value : 0.2V / Max Value : 4.8V)";
BA_ "Version" SG_ 479 ALBCU_LumbarDefDis "20.10.02";
BA_ "RoutingFactor" SG_ 479 ALBCU_LumbarDefDis 0;
BA_ "NetworkRequestHoldingTime" SG_ 479 ALBCU_LumbarDefDis 5000;
BA_ "NetworkRequest" SG_ 479 ALBCU_LumbarDefDis 0;
BA_ "UserSigValidity" SG_ 479 ALBCU_LumbarDefDis 1;
BA_ "GenSigSendType" SG_ 479 ALBCU_LumbarDefDis 4;
BA_ "Description" SG_ 479 ALBCU_LumbarDefDis "This signal is used to display the seat movement to AVN";
BA_ "Version" SG_ 479 ALBCU_BolsterInfDis "20.10.02";
BA_ "RoutingFactor" SG_ 479 ALBCU_BolsterInfDis 0;
BA_ "NetworkRequestHoldingTime" SG_ 479 ALBCU_BolsterInfDis 5000;
BA_ "NetworkRequest" SG_ 479 ALBCU_BolsterInfDis 0;
BA_ "UserSigValidity" SG_ 479 ALBCU_BolsterInfDis 1;
BA_ "GenSigSendType" SG_ 479 ALBCU_BolsterInfDis 4;
BA_ "Description" SG_ 479 ALBCU_BolsterInfDis "This signal is used to display the seat movement to AVN";
BA_ "Version" SG_ 2223056129 SAS_Crc1Val "18.11.08";
BA_ "RoutingFactor" SG_ 2223056129 SAS_Crc1Val 5;
BA_ "UserSigValidity" SG_ 2223056129 SAS_Crc1Val 3;
BA_ "GenSigStartValue" SG_ 2223056129 SAS_Crc1Val 65535;
BA_ "Description" SG_ 2223056129 SAS_Crc1Val "The data area for CRC calculation is based on the data length (DLC) of the message DB.

The CRC shall be calculated over the entire data block (excluding the CRC bytes) including the user data, alive counter and Data ID

 

- CRC Polynomial (0x1021) , In";
BA_ "Version" SG_ 2223056129 SAS_AlvCnt1Val "18.11.08";
BA_ "RoutingFactor" SG_ 2223056129 SAS_AlvCnt1Val 5;
BA_ "UserSigValidity" SG_ 2223056129 SAS_AlvCnt1Val 3;
BA_ "Description" SG_ 2223056129 SAS_AlvCnt1Val "For the first transmission request for a data element the counter shall be initialized with 0 and shall be incremented by 1 for every subsequent send request. 

When the counter reaches the maximum value(0xFF), then it shall restart with 0 for the next s";
BA_ "Version" SG_ 2223056129 SAS_AnglVal "21.07.05";
BA_ "RoutingFactor" SG_ 2223056129 SAS_AnglVal 5;
BA_ "UserSigValidity" SG_ 2223056129 SAS_AnglVal 3;
BA_ "GenSigStartValue" SG_ 2223056129 SAS_AnglVal 32767;
BA_ "Description" SG_ 2223056129 SAS_AnglVal "Information regarding the steering wheel angle.  (PH) = (HEX) * 0.1 (0 <  HEX < 7FFFH) or (PH) = (HEX - 65536) * 0.1 (HEX > 7FFFH)



this signal has direction information.

'+' Value means Counter clock wise rotation.

'-' value means Clock wise rotatio";
BA_ "Version" SG_ 2223056129 SAS_SpdVal "21.07.05";
BA_ "RoutingFactor" SG_ 2223056129 SAS_SpdVal 5;
BA_ "UserSigValidity" SG_ 2223056129 SAS_SpdVal 3;
BA_ "GenSigStartValue" SG_ 2223056129 SAS_SpdVal 255;
BA_ "Description" SG_ 2223056129 SAS_SpdVal "Information regarding the steering wheel rotation speed 

(PH) = (HEX) * 4 (0 ¡Â HEX < 254)";
BA_ "Version" SG_ 2223056129 SAS_IntSta "21.07.05";
BA_ "RoutingFactor" SG_ 2223056129 SAS_IntSta 5;
BA_ "UserSigValidity" SG_ 2223056129 SAS_IntSta 3;
BA_ "GenSigStartValue" SG_ 2223056129 SAS_IntSta 14;
BA_ "Description" SG_ 2223056129 SAS_IntSta "Information regarding the steering angle sensor¡¯s internal state. If SAS_AnglVal value is O.K., SAS_OK flag is set and otherwise SAS_OK flag is cleared. If steering angle sensor has been calibrated, SAS_CAL flag is set and otherwise cleared.

SF1 - SF5 ";
BA_ "Version" SG_ 1434 RCM_GST_Byte0 "20.11.01";
BA_ "NetworkRequestHoldingTime" SG_ 1434 RCM_GST_Byte0 5000;
BA_ "UserSigValidity" SG_ 1434 RCM_GST_Byte0 0;
BA_ "UsrSigPurpose" SG_ 1434 RCM_GST_Byte0 4;
BA_ "Description" SG_ 1434 RCM_GST_Byte0 "TP Index : 55";
BA_ "Version" SG_ 1434 RCM_GST_Byte2 "20.11.01";
BA_ "NetworkRequestHoldingTime" SG_ 1434 RCM_GST_Byte2 5000;
BA_ "UserSigValidity" SG_ 1434 RCM_GST_Byte2 0;
BA_ "UsrSigPurpose" SG_ 1434 RCM_GST_Byte2 4;
BA_ "Description" SG_ 1434 RCM_GST_Byte2 "TP Index : 55";
BA_ "Version" SG_ 1434 RCM_GST_Byte3 "20.11.01";
BA_ "NetworkRequestHoldingTime" SG_ 1434 RCM_GST_Byte3 5000;
BA_ "UserSigValidity" SG_ 1434 RCM_GST_Byte3 0;
BA_ "UsrSigPurpose" SG_ 1434 RCM_GST_Byte3 4;
BA_ "Description" SG_ 1434 RCM_GST_Byte3 "TP Index : 55";
BA_ "Version" SG_ 1434 RCM_GST_Byte4 "20.11.01";
BA_ "NetworkRequestHoldingTime" SG_ 1434 RCM_GST_Byte4 5000;
BA_ "UserSigValidity" SG_ 1434 RCM_GST_Byte4 0;
BA_ "UsrSigPurpose" SG_ 1434 RCM_GST_Byte4 4;
BA_ "Description" SG_ 1434 RCM_GST_Byte4 "TP Index : 55";
BA_ "Version" SG_ 1434 RCM_GST_Byte5 "20.11.01";
BA_ "NetworkRequestHoldingTime" SG_ 1434 RCM_GST_Byte5 5000;
BA_ "UserSigValidity" SG_ 1434 RCM_GST_Byte5 0;
BA_ "UsrSigPurpose" SG_ 1434 RCM_GST_Byte5 4;
BA_ "Description" SG_ 1434 RCM_GST_Byte5 "TP Index : 55";
BA_ "Version" SG_ 1434 RCM_GST_Byte6 "20.11.01";
BA_ "NetworkRequestHoldingTime" SG_ 1434 RCM_GST_Byte6 5000;
BA_ "UserSigValidity" SG_ 1434 RCM_GST_Byte6 0;
BA_ "UsrSigPurpose" SG_ 1434 RCM_GST_Byte6 4;
BA_ "Description" SG_ 1434 RCM_GST_Byte6 "TP Index : 55";
BA_ "Version" SG_ 1434 RCM_GST_Byte7 "20.11.01";
BA_ "NetworkRequestHoldingTime" SG_ 1434 RCM_GST_Byte7 5000;
BA_ "UserSigValidity" SG_ 1434 RCM_GST_Byte7 0;
BA_ "UsrSigPurpose" SG_ 1434 RCM_GST_Byte7 4;
BA_ "Description" SG_ 1434 RCM_GST_Byte7 "TP Index : 55";
BA_ "Version" SG_ 1434 RCM_GST_Byte1 "20.11.01";
BA_ "NetworkRequestHoldingTime" SG_ 1434 RCM_GST_Byte1 5000;
BA_ "UserSigValidity" SG_ 1434 RCM_GST_Byte1 0;
BA_ "UsrSigPurpose" SG_ 1434 RCM_GST_Byte1 4;
BA_ "Description" SG_ 1434 RCM_GST_Byte1 "TP Index : 55";
BA_ "Version" SG_ 463 SWRC_Crc3Val "21.09.03";
BA_ "UserSigValidity" SG_ 463 SWRC_Crc3Val 0;
BA_ "Description" SG_ 463 SWRC_Crc3Val "The data area for CRC calculation is based on the data length (DLC) of the message DB.

The CRC shall be calculated over the entire data block (excluding the CRC bytes) including the user data, alive counter and Data ID 

 

- CRC Polynomial (0x1D) , Ini";
BA_ "Version" SG_ 463 SWRC_AlvCnt3Val "21.09.03";
BA_ "UserSigValidity" SG_ 463 SWRC_AlvCnt3Val 0;
BA_ "Description" SG_ 463 SWRC_AlvCnt3Val "For the first transmission request for a data element the counter shall be initialized with 0 and shall be incremented by 1

for every subsequent send request. When the counter reaches the maximum value(0xE), then it shall restart with 0 for the next sen";
BA_ "Version" SG_ 463 SWRC_CrsSwSta "21.07.05";
BA_ "UserSigValidity" SG_ 463 SWRC_CrsSwSta 0;
BA_ "Description" SG_ 463 SWRC_CrsSwSta "Cruise switch status

C-CAN Gateway needed";
BA_ "Version" SG_ 463 SWRC_CrsMainSwSta "21.07.05";
BA_ "UserSigValidity" SG_ 463 SWRC_CrsMainSwSta 0;
BA_ "Description" SG_ 463 SWRC_CrsMainSwSta "Cruise on/off switch

C-CAN Gateway needed";
BA_ "Version" SG_ 463 SWRC_SldMainSwSta "19.11.02";
BA_ "UserSigValidity" SG_ 463 SWRC_SldMainSwSta 0;
BA_ "Description" SG_ 463 SWRC_SldMainSwSta "Speedlimiter on/off switch

C-CAN Gateway needed";
BA_ "Version" SG_ 463 SWRC_LFASwSta "21.07.05";
BA_ "UserSigValidity" SG_ 463 SWRC_LFASwSta 0;
BA_ "Description" SG_ 463 SWRC_LFASwSta "LFA on/off switch

C-CAN Gateway needed";
BA_ "Version" SG_ 463 SWRC_PaddleUpSwSta "19.11.02";
BA_ "UserSigValidity" SG_ 463 SWRC_PaddleUpSwSta 0;
BA_ "Description" SG_ 463 SWRC_PaddleUpSwSta "Paddle Up switch

C-CAN Gateway needed";
BA_ "Version" SG_ 463 SWRC_PaddleDnSwSta "19.11.02";
BA_ "UserSigValidity" SG_ 463 SWRC_PaddleDnSwSta 0;
BA_ "Description" SG_ 463 SWRC_PaddleDnSwSta "Paddle Down switch

C-CAN Gateway needed";
BA_ "Version" SG_ 463 SWRC_Info "21.07.05";
BA_ "UserSigValidity" SG_ 463 SWRC_Info 0;
BA_ "Description" SG_ 463 SWRC_Info "Steering Wheel Remocon switch information 

This signal is used to determine 'CAN type SWRX' is applied or not in this vehicle.



0x0 : CAN type SWRC is Not Applied

0x1 : CAN type SWRC Applied";
BA_ "Version" SG_ 463 SWRC_HdpSwSta "19.12.00";
BA_ "UserSigValidity" SG_ 463 SWRC_HdpSwSta 0;
BA_ "Version" SG_ 463 SWRC_HDPSpprtSWVer "21.11.00";
BA_ "UserSigValidity" SG_ 463 SWRC_HDPSpprtSWVer 0;
BA_ "Version" SG_ 1414 GST_EMCU_Byte0 "21.04.08";
BA_ "NetworkRequestHoldingTime" SG_ 1414 GST_EMCU_Byte0 5000;
BA_ "NetworkRequest" SG_ 1414 GST_EMCU_Byte0 0;
BA_ "UserSigValidity" SG_ 1414 GST_EMCU_Byte0 0;
BA_ "UsrSigPurpose" SG_ 1414 GST_EMCU_Byte0 3;
BA_ "Description" SG_ 1414 GST_EMCU_Byte0 "TP Index : 95";
BA_ "Version" SG_ 1414 GST_EMCU_Byte2 "21.04.08";
BA_ "NetworkRequestHoldingTime" SG_ 1414 GST_EMCU_Byte2 5000;
BA_ "NetworkRequest" SG_ 1414 GST_EMCU_Byte2 0;
BA_ "UserSigValidity" SG_ 1414 GST_EMCU_Byte2 0;
BA_ "UsrSigPurpose" SG_ 1414 GST_EMCU_Byte2 3;
BA_ "Description" SG_ 1414 GST_EMCU_Byte2 "TP Index : 95";
BA_ "Version" SG_ 1414 GST_EMCU_Byte3 "21.04.08";
BA_ "NetworkRequestHoldingTime" SG_ 1414 GST_EMCU_Byte3 5000;
BA_ "NetworkRequest" SG_ 1414 GST_EMCU_Byte3 0;
BA_ "UserSigValidity" SG_ 1414 GST_EMCU_Byte3 0;
BA_ "UsrSigPurpose" SG_ 1414 GST_EMCU_Byte3 3;
BA_ "Description" SG_ 1414 GST_EMCU_Byte3 "TP Index : 95";
BA_ "Version" SG_ 1414 GST_EMCU_Byte4 "21.04.08";
BA_ "NetworkRequestHoldingTime" SG_ 1414 GST_EMCU_Byte4 5000;
BA_ "NetworkRequest" SG_ 1414 GST_EMCU_Byte4 0;
BA_ "UserSigValidity" SG_ 1414 GST_EMCU_Byte4 0;
BA_ "UsrSigPurpose" SG_ 1414 GST_EMCU_Byte4 3;
BA_ "Description" SG_ 1414 GST_EMCU_Byte4 "TP Index : 95";
BA_ "Version" SG_ 1414 GST_EMCU_Byte5 "21.04.08";
BA_ "NetworkRequestHoldingTime" SG_ 1414 GST_EMCU_Byte5 5000;
BA_ "NetworkRequest" SG_ 1414 GST_EMCU_Byte5 0;
BA_ "UserSigValidity" SG_ 1414 GST_EMCU_Byte5 0;
BA_ "UsrSigPurpose" SG_ 1414 GST_EMCU_Byte5 3;
BA_ "Description" SG_ 1414 GST_EMCU_Byte5 "TP Index : 95";
BA_ "Version" SG_ 1414 GST_EMCU_Byte6 "21.04.08";
BA_ "NetworkRequestHoldingTime" SG_ 1414 GST_EMCU_Byte6 5000;
BA_ "NetworkRequest" SG_ 1414 GST_EMCU_Byte6 0;
BA_ "UserSigValidity" SG_ 1414 GST_EMCU_Byte6 0;
BA_ "UsrSigPurpose" SG_ 1414 GST_EMCU_Byte6 3;
BA_ "Description" SG_ 1414 GST_EMCU_Byte6 "TP Index : 95";
BA_ "Version" SG_ 1414 GST_EMCU_Byte7 "21.04.08";
BA_ "NetworkRequestHoldingTime" SG_ 1414 GST_EMCU_Byte7 5000;
BA_ "NetworkRequest" SG_ 1414 GST_EMCU_Byte7 0;
BA_ "UserSigValidity" SG_ 1414 GST_EMCU_Byte7 0;
BA_ "UsrSigPurpose" SG_ 1414 GST_EMCU_Byte7 3;
BA_ "Description" SG_ 1414 GST_EMCU_Byte7 "TP Index : 95";
BA_ "Version" SG_ 1414 GST_EMCU_Byte1 "21.04.08";
BA_ "NetworkRequestHoldingTime" SG_ 1414 GST_EMCU_Byte1 5000;
BA_ "NetworkRequest" SG_ 1414 GST_EMCU_Byte1 0;
BA_ "UserSigValidity" SG_ 1414 GST_EMCU_Byte1 0;
BA_ "UsrSigPurpose" SG_ 1414 GST_EMCU_Byte1 3;
BA_ "Description" SG_ 1414 GST_EMCU_Byte1 "TP Index : 95";
BA_ "Version" SG_ 1412 GST_SGU_Byte0 "21.07.07";
BA_ "NetworkRequestHoldingTime" SG_ 1412 GST_SGU_Byte0 5000;
BA_ "NetworkRequest" SG_ 1412 GST_SGU_Byte0 0;
BA_ "UserSigValidity" SG_ 1412 GST_SGU_Byte0 0;
BA_ "UsrSigPurpose" SG_ 1412 GST_SGU_Byte0 3;
BA_ "Description" SG_ 1412 GST_SGU_Byte0 "TP Index : 233";
BA_ "Version" SG_ 1412 GST_SGU_Byte2 "21.07.07";
BA_ "NetworkRequestHoldingTime" SG_ 1412 GST_SGU_Byte2 5000;
BA_ "NetworkRequest" SG_ 1412 GST_SGU_Byte2 0;
BA_ "UserSigValidity" SG_ 1412 GST_SGU_Byte2 0;
BA_ "UsrSigPurpose" SG_ 1412 GST_SGU_Byte2 3;
BA_ "Description" SG_ 1412 GST_SGU_Byte2 "TP Index : 233";
BA_ "Version" SG_ 1412 GST_SGU_Byte3 "21.07.07";
BA_ "NetworkRequestHoldingTime" SG_ 1412 GST_SGU_Byte3 5000;
BA_ "NetworkRequest" SG_ 1412 GST_SGU_Byte3 0;
BA_ "UserSigValidity" SG_ 1412 GST_SGU_Byte3 0;
BA_ "UsrSigPurpose" SG_ 1412 GST_SGU_Byte3 3;
BA_ "Description" SG_ 1412 GST_SGU_Byte3 "TP Index : 233";
BA_ "Version" SG_ 1412 GST_SGU_Byte4 "21.07.07";
BA_ "NetworkRequestHoldingTime" SG_ 1412 GST_SGU_Byte4 5000;
BA_ "NetworkRequest" SG_ 1412 GST_SGU_Byte4 0;
BA_ "UserSigValidity" SG_ 1412 GST_SGU_Byte4 0;
BA_ "UsrSigPurpose" SG_ 1412 GST_SGU_Byte4 3;
BA_ "Description" SG_ 1412 GST_SGU_Byte4 "TP Index : 233";
BA_ "Version" SG_ 1412 GST_SGU_Byte5 "21.07.07";
BA_ "NetworkRequestHoldingTime" SG_ 1412 GST_SGU_Byte5 5000;
BA_ "NetworkRequest" SG_ 1412 GST_SGU_Byte5 0;
BA_ "UserSigValidity" SG_ 1412 GST_SGU_Byte5 0;
BA_ "UsrSigPurpose" SG_ 1412 GST_SGU_Byte5 3;
BA_ "Description" SG_ 1412 GST_SGU_Byte5 "TP Index : 233";
BA_ "Version" SG_ 1412 GST_SGU_Byte6 "21.07.07";
BA_ "NetworkRequestHoldingTime" SG_ 1412 GST_SGU_Byte6 5000;
BA_ "NetworkRequest" SG_ 1412 GST_SGU_Byte6 0;
BA_ "UserSigValidity" SG_ 1412 GST_SGU_Byte6 0;
BA_ "UsrSigPurpose" SG_ 1412 GST_SGU_Byte6 3;
BA_ "Description" SG_ 1412 GST_SGU_Byte6 "TP Index : 233";
BA_ "Version" SG_ 1412 GST_SGU_Byte7 "21.07.07";
BA_ "NetworkRequestHoldingTime" SG_ 1412 GST_SGU_Byte7 5000;
BA_ "NetworkRequest" SG_ 1412 GST_SGU_Byte7 0;
BA_ "UserSigValidity" SG_ 1412 GST_SGU_Byte7 0;
BA_ "UsrSigPurpose" SG_ 1412 GST_SGU_Byte7 3;
BA_ "Description" SG_ 1412 GST_SGU_Byte7 "TP Index : 233";
BA_ "Version" SG_ 1412 GST_SGU_Byte1 "21.07.07";
BA_ "NetworkRequestHoldingTime" SG_ 1412 GST_SGU_Byte1 5000;
BA_ "NetworkRequest" SG_ 1412 GST_SGU_Byte1 0;
BA_ "UserSigValidity" SG_ 1412 GST_SGU_Byte1 0;
BA_ "UsrSigPurpose" SG_ 1412 GST_SGU_Byte1 3;
BA_ "Description" SG_ 1412 GST_SGU_Byte1 "TP Index : 233";
BA_ "Version" SG_ 1422 EMCU_GST_Byte0 "21.05.04";
BA_ "UserSigValidity" SG_ 1422 EMCU_GST_Byte0 3;
BA_ "UsrSigPurpose" SG_ 1422 EMCU_GST_Byte0 4;
BA_ "Description" SG_ 1422 EMCU_GST_Byte0 "TP Index : 95";
BA_ "Version" SG_ 1422 EMCU_GST_Byte2 "21.05.04";
BA_ "UserSigValidity" SG_ 1422 EMCU_GST_Byte2 3;
BA_ "UsrSigPurpose" SG_ 1422 EMCU_GST_Byte2 4;
BA_ "Description" SG_ 1422 EMCU_GST_Byte2 "TP Index : 95";
BA_ "Version" SG_ 1422 EMCU_GST_Byte3 "21.05.04";
BA_ "UserSigValidity" SG_ 1422 EMCU_GST_Byte3 3;
BA_ "UsrSigPurpose" SG_ 1422 EMCU_GST_Byte3 4;
BA_ "Description" SG_ 1422 EMCU_GST_Byte3 "TP Index : 95";
BA_ "Version" SG_ 1422 EMCU_GST_Byte4 "21.05.04";
BA_ "UserSigValidity" SG_ 1422 EMCU_GST_Byte4 3;
BA_ "UsrSigPurpose" SG_ 1422 EMCU_GST_Byte4 4;
BA_ "Description" SG_ 1422 EMCU_GST_Byte4 "TP Index : 95";
BA_ "Version" SG_ 1422 EMCU_GST_Byte5 "21.05.04";
BA_ "UserSigValidity" SG_ 1422 EMCU_GST_Byte5 3;
BA_ "UsrSigPurpose" SG_ 1422 EMCU_GST_Byte5 4;
BA_ "Description" SG_ 1422 EMCU_GST_Byte5 "TP Index : 95";
BA_ "Version" SG_ 1422 EMCU_GST_Byte6 "21.05.04";
BA_ "UserSigValidity" SG_ 1422 EMCU_GST_Byte6 3;
BA_ "UsrSigPurpose" SG_ 1422 EMCU_GST_Byte6 4;
BA_ "Description" SG_ 1422 EMCU_GST_Byte6 "TP Index : 95";
BA_ "Version" SG_ 1422 EMCU_GST_Byte7 "21.05.04";
BA_ "UserSigValidity" SG_ 1422 EMCU_GST_Byte7 3;
BA_ "UsrSigPurpose" SG_ 1422 EMCU_GST_Byte7 4;
BA_ "Description" SG_ 1422 EMCU_GST_Byte7 "TP Index : 95";
BA_ "Version" SG_ 1422 EMCU_GST_Byte1 "21.05.04";
BA_ "UserSigValidity" SG_ 1422 EMCU_GST_Byte1 3;
BA_ "UsrSigPurpose" SG_ 1422 EMCU_GST_Byte1 4;
BA_ "Description" SG_ 1422 EMCU_GST_Byte1 "TP Index : 95";
BA_ "Version" SG_ 1420 SGU_GST_Byte0 "21.08.02";
BA_ "UserSigValidity" SG_ 1420 SGU_GST_Byte0 0;
BA_ "UsrSigPurpose" SG_ 1420 SGU_GST_Byte0 4;
BA_ "Description" SG_ 1420 SGU_GST_Byte0 "TP Index : 233";
BA_ "Version" SG_ 1420 SGU_GST_Byte2 "21.08.02";
BA_ "UserSigValidity" SG_ 1420 SGU_GST_Byte2 0;
BA_ "UsrSigPurpose" SG_ 1420 SGU_GST_Byte2 4;
BA_ "Description" SG_ 1420 SGU_GST_Byte2 "TP Index : 233";
BA_ "Version" SG_ 1420 SGU_GST_Byte3 "21.08.02";
BA_ "UserSigValidity" SG_ 1420 SGU_GST_Byte3 0;
BA_ "UsrSigPurpose" SG_ 1420 SGU_GST_Byte3 4;
BA_ "Description" SG_ 1420 SGU_GST_Byte3 "TP Index : 233";
BA_ "Version" SG_ 1420 SGU_GST_Byte4 "21.08.02";
BA_ "UserSigValidity" SG_ 1420 SGU_GST_Byte4 0;
BA_ "UsrSigPurpose" SG_ 1420 SGU_GST_Byte4 4;
BA_ "Description" SG_ 1420 SGU_GST_Byte4 "TP Index : 233";
BA_ "Version" SG_ 1420 SGU_GST_Byte5 "21.08.02";
BA_ "UserSigValidity" SG_ 1420 SGU_GST_Byte5 0;
BA_ "UsrSigPurpose" SG_ 1420 SGU_GST_Byte5 4;
BA_ "Description" SG_ 1420 SGU_GST_Byte5 "TP Index : 233";
BA_ "Version" SG_ 1420 SGU_GST_Byte6 "21.08.02";
BA_ "UserSigValidity" SG_ 1420 SGU_GST_Byte6 0;
BA_ "UsrSigPurpose" SG_ 1420 SGU_GST_Byte6 4;
BA_ "Description" SG_ 1420 SGU_GST_Byte6 "TP Index : 233";
BA_ "Version" SG_ 1420 SGU_GST_Byte7 "21.08.02";
BA_ "UserSigValidity" SG_ 1420 SGU_GST_Byte7 0;
BA_ "UsrSigPurpose" SG_ 1420 SGU_GST_Byte7 4;
BA_ "Description" SG_ 1420 SGU_GST_Byte7 "TP Index : 233";
BA_ "Version" SG_ 1420 SGU_GST_Byte1 "21.08.02";
BA_ "UserSigValidity" SG_ 1420 SGU_GST_Byte1 0;
BA_ "UsrSigPurpose" SG_ 1420 SGU_GST_Byte1 4;
BA_ "Description" SG_ 1420 SGU_GST_Byte1 "TP Index : 233";
BA_ "Version" SG_ 2382595329 ICSC_Crc3Val "21.09.03";
BA_ "RoutingFactor" SG_ 2382595329 ICSC_Crc3Val 2;
BA_ "UserSigValidity" SG_ 2382595329 ICSC_Crc3Val 3;
BA_ "GenSigStartValue" SG_ 2382595329 ICSC_Crc3Val 65535;
BA_ "Description" SG_ 2382595329 ICSC_Crc3Val "The data area for CRC calculation is based on the data length (DLC) of the message DB.

The CRC shall be calculated over the entire data block (excluding the CRC bytes) including the user data, alive counter and Data ID



- CRC Polynomial (0x1021) , Ini";
BA_ "Version" SG_ 2382595329 ICSC_AlvCnt3Val "21.09.03";
BA_ "RoutingFactor" SG_ 2382595329 ICSC_AlvCnt3Val 2;
BA_ "UserSigValidity" SG_ 2382595329 ICSC_AlvCnt3Val 3;
BA_ "Description" SG_ 2382595329 ICSC_AlvCnt3Val "For the first transmission request for a data element the counter shall be initialized with 0 and shall be incremented by 1 for every subsequent send request. 

When the counter reaches the maximum value(0xFF), then it shall restart with 0 for the next s";
BA_ "Version" SG_ 2382595329 DMIC_OffRdMod "23.04.02";
BA_ "RoutingFactor" SG_ 2382595329 DMIC_OffRdMod 2;
BA_ "UserSigValidity" SG_ 2382595329 DMIC_OffRdMod 3;
BA_ "Description" SG_ 2382595329 DMIC_OffRdMod "This signal indicates that which offroad mode vehicle drives.";
BA_ "Version" SG_ 2382595329 DMIC_OffRdModActvSta "18.03.04";
BA_ "RoutingFactor" SG_ 2382595329 DMIC_OffRdModActvSta 2;
BA_ "UserSigValidity" SG_ 2382595329 DMIC_OffRdModActvSta 3;
BA_ "Description" SG_ 2382595329 DMIC_OffRdModActvSta "Information about offroad";
BA_ "Version" SG_ 2382595329 DMIC_OffRdModSta "18.03.04";
BA_ "RoutingFactor" SG_ 2382595329 DMIC_OffRdModSta 2;
BA_ "UserSigValidity" SG_ 2382595329 DMIC_OffRdModSta 3;
BA_ "Description" SG_ 2382595329 DMIC_OffRdModSta "Information about offroad mode change";
BA_ "Version" SG_ 2382595329 ESC_LongGrdntPerc "18.11.02";
BA_ "RoutingFactor" SG_ 2382595329 ESC_LongGrdntPerc 2;
BA_ "UserSigValidity" SG_ 2382595329 ESC_LongGrdntPerc 3;
BA_ "Description" SG_ 2382595329 ESC_LongGrdntPerc "This signal indicates longitudinal gradient in % unit.";
BA_ "Version" SG_ 2382595329 ESC_LatGrdntPerc "18.11.02";
BA_ "RoutingFactor" SG_ 2382595329 ESC_LatGrdntPerc 2;
BA_ "UserSigValidity" SG_ 2382595329 ESC_LatGrdntPerc 3;
BA_ "Description" SG_ 2382595329 ESC_LatGrdntPerc "This signal indicates lateral gradient in % unit.";
BA_ "Version" SG_ 2382595329 OFFROAD_AppliedSta "23.06.02";
BA_ "RoutingFactor" SG_ 2382595329 OFFROAD_AppliedSta 2;
BA_ "UserSigValidity" SG_ 2382595329 OFFROAD_AppliedSta 3;
BA_ "Description" SG_ 2382595329 OFFROAD_AppliedSta "This signal indicates whether the each offroad mode is applied or not.

For each bit value, 0x0 means 'Not Applied'. And 0x1 means 'Applied'.

 - Bit 0 : Snow

 - Bit 1 : Mud

 - Bit 2 : Sand

 - Bit 3 : Auto

 - Bit 4 : Deep Snow

 - Bit 5 : Rock

 - Bi";
BA_ "Version" SG_ 2382595329 OFFROAD_TypeSta "21.03.09";
BA_ "RoutingFactor" SG_ 2382595329 OFFROAD_TypeSta 2;
BA_ "UserSigValidity" SG_ 2382595329 OFFROAD_TypeSta 3;
BA_ "Description" SG_ 2382595329 OFFROAD_TypeSta "This signal indicates the type of offroad mode function.

 0X0 : Not applied

 0X1 : Terrain w/ Button

 0X2 : Traction w/ Button

 0X3 : w/o Button";
BA_ "Version" SG_ 1456 GST_RRSAU_RRLBCU_Byte0 "22.10.20";
BA_ "NetworkRequestHoldingTime" SG_ 1456 GST_RRSAU_RRLBCU_Byte0 5000;
BA_ "NetworkRequest" SG_ 1456 GST_RRSAU_RRLBCU_Byte0 0;
BA_ "UserSigValidity" SG_ 1456 GST_RRSAU_RRLBCU_Byte0 0;
BA_ "UsrSigPurpose" SG_ 1456 GST_RRSAU_RRLBCU_Byte0 3;
BA_ "Description" SG_ 1456 GST_RRSAU_RRLBCU_Byte0 "TP Index : 210";
BA_ "Version" SG_ 1456 GST_RRSAU_RRLBCU_Byte2 "22.10.20";
BA_ "NetworkRequestHoldingTime" SG_ 1456 GST_RRSAU_RRLBCU_Byte2 5000;
BA_ "NetworkRequest" SG_ 1456 GST_RRSAU_RRLBCU_Byte2 0;
BA_ "UserSigValidity" SG_ 1456 GST_RRSAU_RRLBCU_Byte2 0;
BA_ "UsrSigPurpose" SG_ 1456 GST_RRSAU_RRLBCU_Byte2 3;
BA_ "Description" SG_ 1456 GST_RRSAU_RRLBCU_Byte2 "TP Index : 210";
BA_ "Version" SG_ 1456 GST_RRSAU_RRLBCU_Byte3 "22.10.20";
BA_ "NetworkRequestHoldingTime" SG_ 1456 GST_RRSAU_RRLBCU_Byte3 5000;
BA_ "NetworkRequest" SG_ 1456 GST_RRSAU_RRLBCU_Byte3 0;
BA_ "UserSigValidity" SG_ 1456 GST_RRSAU_RRLBCU_Byte3 0;
BA_ "UsrSigPurpose" SG_ 1456 GST_RRSAU_RRLBCU_Byte3 3;
BA_ "Description" SG_ 1456 GST_RRSAU_RRLBCU_Byte3 "TP Index : 210";
BA_ "Version" SG_ 1456 GST_RRSAU_RRLBCU_Byte4 "22.10.20";
BA_ "NetworkRequestHoldingTime" SG_ 1456 GST_RRSAU_RRLBCU_Byte4 5000;
BA_ "NetworkRequest" SG_ 1456 GST_RRSAU_RRLBCU_Byte4 0;
BA_ "UserSigValidity" SG_ 1456 GST_RRSAU_RRLBCU_Byte4 0;
BA_ "UsrSigPurpose" SG_ 1456 GST_RRSAU_RRLBCU_Byte4 3;
BA_ "Description" SG_ 1456 GST_RRSAU_RRLBCU_Byte4 "TP Index : 210";
BA_ "Version" SG_ 1456 GST_RRSAU_RRLBCU_Byte5 "22.10.20";
BA_ "NetworkRequestHoldingTime" SG_ 1456 GST_RRSAU_RRLBCU_Byte5 5000;
BA_ "NetworkRequest" SG_ 1456 GST_RRSAU_RRLBCU_Byte5 0;
BA_ "UserSigValidity" SG_ 1456 GST_RRSAU_RRLBCU_Byte5 0;
BA_ "UsrSigPurpose" SG_ 1456 GST_RRSAU_RRLBCU_Byte5 3;
BA_ "Description" SG_ 1456 GST_RRSAU_RRLBCU_Byte5 "TP Index : 210";
BA_ "Version" SG_ 1456 GST_RRSAU_RRLBCU_Byte6 "22.10.20";
BA_ "NetworkRequestHoldingTime" SG_ 1456 GST_RRSAU_RRLBCU_Byte6 5000;
BA_ "NetworkRequest" SG_ 1456 GST_RRSAU_RRLBCU_Byte6 0;
BA_ "UserSigValidity" SG_ 1456 GST_RRSAU_RRLBCU_Byte6 0;
BA_ "UsrSigPurpose" SG_ 1456 GST_RRSAU_RRLBCU_Byte6 3;
BA_ "Description" SG_ 1456 GST_RRSAU_RRLBCU_Byte6 "TP Index : 210";
BA_ "Version" SG_ 1456 GST_RRSAU_RRLBCU_Byte7 "22.10.20";
BA_ "NetworkRequestHoldingTime" SG_ 1456 GST_RRSAU_RRLBCU_Byte7 5000;
BA_ "NetworkRequest" SG_ 1456 GST_RRSAU_RRLBCU_Byte7 0;
BA_ "UserSigValidity" SG_ 1456 GST_RRSAU_RRLBCU_Byte7 0;
BA_ "UsrSigPurpose" SG_ 1456 GST_RRSAU_RRLBCU_Byte7 3;
BA_ "Description" SG_ 1456 GST_RRSAU_RRLBCU_Byte7 "TP Index : 210";
BA_ "Version" SG_ 1456 GST_RRSAU_RRLBCU_Byte1 "22.10.20";
BA_ "NetworkRequestHoldingTime" SG_ 1456 GST_RRSAU_RRLBCU_Byte1 5000;
BA_ "NetworkRequest" SG_ 1456 GST_RRSAU_RRLBCU_Byte1 0;
BA_ "UserSigValidity" SG_ 1456 GST_RRSAU_RRLBCU_Byte1 0;
BA_ "UsrSigPurpose" SG_ 1456 GST_RRSAU_RRLBCU_Byte1 3;
BA_ "Description" SG_ 1456 GST_RRSAU_RRLBCU_Byte1 "TP Index : 210";
BA_ "Version" SG_ 1457 GST_RLSAU_RLLBCU_Byte0 "22.10.20";
BA_ "NetworkRequestHoldingTime" SG_ 1457 GST_RLSAU_RLLBCU_Byte0 5000;
BA_ "NetworkRequest" SG_ 1457 GST_RLSAU_RLLBCU_Byte0 0;
BA_ "UserSigValidity" SG_ 1457 GST_RLSAU_RLLBCU_Byte0 0;
BA_ "UsrSigPurpose" SG_ 1457 GST_RLSAU_RLLBCU_Byte0 3;
BA_ "Description" SG_ 1457 GST_RLSAU_RLLBCU_Byte0 "TP Index : 211";
BA_ "Version" SG_ 1457 GST_RLSAU_RLLBCU_Byte2 "22.10.20";
BA_ "NetworkRequestHoldingTime" SG_ 1457 GST_RLSAU_RLLBCU_Byte2 5000;
BA_ "NetworkRequest" SG_ 1457 GST_RLSAU_RLLBCU_Byte2 0;
BA_ "UserSigValidity" SG_ 1457 GST_RLSAU_RLLBCU_Byte2 0;
BA_ "UsrSigPurpose" SG_ 1457 GST_RLSAU_RLLBCU_Byte2 3;
BA_ "Description" SG_ 1457 GST_RLSAU_RLLBCU_Byte2 "TP Index : 211";
BA_ "Version" SG_ 1457 GST_RLSAU_RLLBCU_Byte3 "22.10.20";
BA_ "NetworkRequestHoldingTime" SG_ 1457 GST_RLSAU_RLLBCU_Byte3 5000;
BA_ "NetworkRequest" SG_ 1457 GST_RLSAU_RLLBCU_Byte3 0;
BA_ "UserSigValidity" SG_ 1457 GST_RLSAU_RLLBCU_Byte3 0;
BA_ "UsrSigPurpose" SG_ 1457 GST_RLSAU_RLLBCU_Byte3 3;
BA_ "Description" SG_ 1457 GST_RLSAU_RLLBCU_Byte3 "TP Index : 211";
BA_ "Version" SG_ 1457 GST_RLSAU_RLLBCU_Byte4 "22.10.20";
BA_ "NetworkRequestHoldingTime" SG_ 1457 GST_RLSAU_RLLBCU_Byte4 5000;
BA_ "NetworkRequest" SG_ 1457 GST_RLSAU_RLLBCU_Byte4 0;
BA_ "UserSigValidity" SG_ 1457 GST_RLSAU_RLLBCU_Byte4 0;
BA_ "UsrSigPurpose" SG_ 1457 GST_RLSAU_RLLBCU_Byte4 3;
BA_ "Description" SG_ 1457 GST_RLSAU_RLLBCU_Byte4 "TP Index : 211";
BA_ "Version" SG_ 1457 GST_RLSAU_RLLBCU_Byte5 "22.10.20";
BA_ "NetworkRequestHoldingTime" SG_ 1457 GST_RLSAU_RLLBCU_Byte5 5000;
BA_ "NetworkRequest" SG_ 1457 GST_RLSAU_RLLBCU_Byte5 0;
BA_ "UserSigValidity" SG_ 1457 GST_RLSAU_RLLBCU_Byte5 0;
BA_ "UsrSigPurpose" SG_ 1457 GST_RLSAU_RLLBCU_Byte5 3;
BA_ "Description" SG_ 1457 GST_RLSAU_RLLBCU_Byte5 "TP Index : 211";
BA_ "Version" SG_ 1457 GST_RLSAU_RLLBCU_Byte6 "22.10.20";
BA_ "NetworkRequestHoldingTime" SG_ 1457 GST_RLSAU_RLLBCU_Byte6 5000;
BA_ "NetworkRequest" SG_ 1457 GST_RLSAU_RLLBCU_Byte6 0;
BA_ "UserSigValidity" SG_ 1457 GST_RLSAU_RLLBCU_Byte6 0;
BA_ "UsrSigPurpose" SG_ 1457 GST_RLSAU_RLLBCU_Byte6 3;
BA_ "Description" SG_ 1457 GST_RLSAU_RLLBCU_Byte6 "TP Index : 211";
BA_ "Version" SG_ 1457 GST_RLSAU_RLLBCU_Byte7 "22.10.20";
BA_ "NetworkRequestHoldingTime" SG_ 1457 GST_RLSAU_RLLBCU_Byte7 5000;
BA_ "NetworkRequest" SG_ 1457 GST_RLSAU_RLLBCU_Byte7 0;
BA_ "UserSigValidity" SG_ 1457 GST_RLSAU_RLLBCU_Byte7 0;
BA_ "UsrSigPurpose" SG_ 1457 GST_RLSAU_RLLBCU_Byte7 3;
BA_ "Description" SG_ 1457 GST_RLSAU_RLLBCU_Byte7 "TP Index : 211";
BA_ "Version" SG_ 1457 GST_RLSAU_RLLBCU_Byte1 "22.10.20";
BA_ "NetworkRequestHoldingTime" SG_ 1457 GST_RLSAU_RLLBCU_Byte1 5000;
BA_ "NetworkRequest" SG_ 1457 GST_RLSAU_RLLBCU_Byte1 0;
BA_ "UserSigValidity" SG_ 1457 GST_RLSAU_RLLBCU_Byte1 0;
BA_ "UsrSigPurpose" SG_ 1457 GST_RLSAU_RLLBCU_Byte1 3;
BA_ "Description" SG_ 1457 GST_RLSAU_RLLBCU_Byte1 "TP Index : 211";
BA_ "Version" SG_ 1458 GST_ATS_Byte0 "21.02.04";
BA_ "NetworkRequestHoldingTime" SG_ 1458 GST_ATS_Byte0 5000;
BA_ "NetworkRequest" SG_ 1458 GST_ATS_Byte0 0;
BA_ "UserSigValidity" SG_ 1458 GST_ATS_Byte0 0;
BA_ "UsrSigPurpose" SG_ 1458 GST_ATS_Byte0 3;
BA_ "Description" SG_ 1458 GST_ATS_Byte0 "TP Index : 212";
BA_ "Version" SG_ 1458 GST_ATS_Byte2 "21.02.04";
BA_ "NetworkRequestHoldingTime" SG_ 1458 GST_ATS_Byte2 5000;
BA_ "NetworkRequest" SG_ 1458 GST_ATS_Byte2 0;
BA_ "UserSigValidity" SG_ 1458 GST_ATS_Byte2 0;
BA_ "UsrSigPurpose" SG_ 1458 GST_ATS_Byte2 3;
BA_ "Description" SG_ 1458 GST_ATS_Byte2 "TP Index : 212";
BA_ "Version" SG_ 1458 GST_ATS_Byte3 "21.02.04";
BA_ "NetworkRequestHoldingTime" SG_ 1458 GST_ATS_Byte3 5000;
BA_ "NetworkRequest" SG_ 1458 GST_ATS_Byte3 0;
BA_ "UserSigValidity" SG_ 1458 GST_ATS_Byte3 0;
BA_ "UsrSigPurpose" SG_ 1458 GST_ATS_Byte3 3;
BA_ "Description" SG_ 1458 GST_ATS_Byte3 "TP Index : 212";
BA_ "Version" SG_ 1458 GST_ATS_Byte4 "21.02.04";
BA_ "NetworkRequestHoldingTime" SG_ 1458 GST_ATS_Byte4 5000;
BA_ "NetworkRequest" SG_ 1458 GST_ATS_Byte4 0;
BA_ "UserSigValidity" SG_ 1458 GST_ATS_Byte4 0;
BA_ "UsrSigPurpose" SG_ 1458 GST_ATS_Byte4 3;
BA_ "Description" SG_ 1458 GST_ATS_Byte4 "TP Index : 212";
BA_ "Version" SG_ 1458 GST_ATS_Byte5 "21.02.04";
BA_ "NetworkRequestHoldingTime" SG_ 1458 GST_ATS_Byte5 5000;
BA_ "NetworkRequest" SG_ 1458 GST_ATS_Byte5 0;
BA_ "UserSigValidity" SG_ 1458 GST_ATS_Byte5 0;
BA_ "UsrSigPurpose" SG_ 1458 GST_ATS_Byte5 3;
BA_ "Description" SG_ 1458 GST_ATS_Byte5 "TP Index : 212";
BA_ "Version" SG_ 1458 GST_ATS_Byte6 "21.02.04";
BA_ "NetworkRequestHoldingTime" SG_ 1458 GST_ATS_Byte6 5000;
BA_ "NetworkRequest" SG_ 1458 GST_ATS_Byte6 0;
BA_ "UserSigValidity" SG_ 1458 GST_ATS_Byte6 0;
BA_ "UsrSigPurpose" SG_ 1458 GST_ATS_Byte6 3;
BA_ "Description" SG_ 1458 GST_ATS_Byte6 "TP Index : 212";
BA_ "Version" SG_ 1458 GST_ATS_Byte7 "21.02.04";
BA_ "NetworkRequestHoldingTime" SG_ 1458 GST_ATS_Byte7 5000;
BA_ "NetworkRequest" SG_ 1458 GST_ATS_Byte7 0;
BA_ "UserSigValidity" SG_ 1458 GST_ATS_Byte7 0;
BA_ "UsrSigPurpose" SG_ 1458 GST_ATS_Byte7 3;
BA_ "Description" SG_ 1458 GST_ATS_Byte7 "TP Index : 212";
BA_ "Version" SG_ 1458 GST_ATS_Byte1 "21.02.04";
BA_ "NetworkRequestHoldingTime" SG_ 1458 GST_ATS_Byte1 5000;
BA_ "NetworkRequest" SG_ 1458 GST_ATS_Byte1 0;
BA_ "UserSigValidity" SG_ 1458 GST_ATS_Byte1 0;
BA_ "UsrSigPurpose" SG_ 1458 GST_ATS_Byte1 3;
BA_ "Description" SG_ 1458 GST_ATS_Byte1 "TP Index : 212";
BA_ "Version" SG_ 2328014850 DATC_FnDstStp "20.07.10";
BA_ "UserSigValidity" SG_ 2328014850 DATC_FnDstStp 7;
BA_ "Description" SG_ 2328014850 DATC_FnDstStp "This signal indicate Fine Dust Step for CCS";
BA_ "Version" SG_ 2328014850 DATC_OutTempOpt "21.01.02";
BA_ "UserSigValidity" SG_ 2328014850 DATC_OutTempOpt 7;
BA_ "Version" SG_ 2328014850 DATC_OutTempDispC "20.10.00";
BA_ "UserSigValidity" SG_ 2328014850 DATC_OutTempDispC 7;
BA_ "Description" SG_ 2328014850 DATC_OutTempDispC "This signal indicates Outside temperature (¡É).

(Use for display only)";
BA_ "Version" SG_ 2328014850 DATC_OutTempDispF "20.10.00";
BA_ "UserSigValidity" SG_ 2328014850 DATC_OutTempDispF 7;
BA_ "Description" SG_ 2328014850 DATC_OutTempDispF "This signal indicates Outside Temperature (¢µ)

(Use for display only)";
BA_ "Version" SG_ 2328014850 DATC_EngOffReqWaterTemp "21.07.05";
BA_ "UserSigValidity" SG_ 2328014850 DATC_EngOffReqWaterTemp 7;
BA_ "Description" SG_ 2328014850 DATC_EngOffReqWaterTemp "Cooling water temperature conditions to request the engine off";
BA_ "Version" SG_ 2328014850 DATC_CELOModeSta "23.08.08";
BA_ "UserSigValidity" SG_ 2328014850 DATC_CELOModeSta 7;
BA_ "Description" SG_ 2328014850 DATC_CELOModeSta "This is a signal for determining the flow stop by Cold Engine Lock Out.";
BA_ "Version" SG_ 2328014850 DATC_HDPDfg_Sta "21.08.02";
BA_ "UserSigValidity" SG_ 2328014850 DATC_HDPDfg_Sta 3;
BA_ "TimeoutValue" SG_ 2328014850 DATC_HDPDfg_Sta "0x1";
BA_ "Description" SG_ 2328014850 DATC_HDPDfg_Sta "This signal indicate AutoDefog status information for HDP.";
BA_ "Version" SG_ 2328014850 DATC_HDPSpprtSWVer "21.12.04";
BA_ "UserSigValidity" SG_ 2328014850 DATC_HDPSpprtSWVer 7;
BA_ "TimeoutValue" SG_ 2328014850 DATC_HDPSpprtSWVer "0x1F";
BA_ "Description" SG_ 2328014850 DATC_HDPSpprtSWVer "This signal indicate the part to be matched on the specification version applied between DATC and ADAS_DRV (HDP control unit) for observe the regulation about autonomous driving.";
BA_ "Version" SG_ 2328014850 DATC_HDPHumidity_Sta "20.05.02";
BA_ "UserSigValidity" SG_ 2328014850 DATC_HDPHumidity_Sta 3;
BA_ "Description" SG_ 2328014850 DATC_HDPHumidity_Sta "This signal indicate Humidity status information for HDP.";
BA_ "Version" SG_ 2328014850 DATC_FnDstStp_Detail "20.09.00";
BA_ "UserSigValidity" SG_ 2328014850 DATC_FnDstStp_Detail 7;
BA_ "Description" SG_ 2328014850 DATC_FnDstStp_Detail "This signal indicate Detail State of Fine Dust Step for ATS.";
BA_ "Version" SG_ 2328014849 DATC_Crc17Val "21.09.03";
BA_ "UserSigValidity" SG_ 2328014849 DATC_Crc17Val 3;
BA_ "GenSigStartValue" SG_ 2328014849 DATC_Crc17Val 65535;
BA_ "Description" SG_ 2328014849 DATC_Crc17Val "The data area for CRC calculation is based on the data length (DLC) of the message DB.

The CRC shall be calculated over the entire data block (excluding the CRC bytes) including the user data, alive counter and Data ID



- CRC Polynomial (0x1021) , Ini";
BA_ "Version" SG_ 2328014849 DATC_AlvCnt17Val "21.09.03";
BA_ "UserSigValidity" SG_ 2328014849 DATC_AlvCnt17Val 3;
BA_ "Description" SG_ 2328014849 DATC_AlvCnt17Val "For the first transmission request for a data element the counter shall be initialized with 0 and shall be incremented by 1 for every subsequent send request. 

When the counter reaches the maximum value(0xFF), then it shall restart with 0 for the next s";
BA_ "Version" SG_ 2328014849 DATC_FrontPwmIsVolt "19.08.05";
BA_ "UserSigValidity" SG_ 2328014849 DATC_FrontPwmIsVolt 7;
BA_ "Version" SG_ 2328014849 DATC_FrontBlwDuty "19.08.05";
BA_ "UserSigValidity" SG_ 2328014849 DATC_FrontBlwDuty 7;
BA_ "Version" SG_ 2328014849 DATC_FrontBlwDiagStat "19.08.05";
BA_ "UserSigValidity" SG_ 2328014849 DATC_FrontBlwDiagStat 7;
BA_ "Version" SG_ 2328014849 DATC_BlwrLvl_Ps "20.02.04";
BA_ "UserSigValidity" SG_ 2328014849 DATC_BlwrLvl_Ps 7;
BA_ "Description" SG_ 2328014849 DATC_BlwrLvl_Ps "This signal indicates step of Front Passenger side blower operation .";
BA_ "Version" SG_ 2328014849 DATC_BlwrLvl_Rr "20.02.03";
BA_ "UserSigValidity" SG_ 2328014849 DATC_BlwrLvl_Rr 7;
BA_ "Description" SG_ 2328014849 DATC_BlwrLvl_Rr "This signal indicates step of Rear blower operation .";
BA_ "Version" SG_ 2328014849 DATC_SwlSta "20.05.00";
BA_ "UserSigValidity" SG_ 2328014849 DATC_SwlSta 3;
BA_ "Description" SG_ 2328014849 DATC_SwlSta "This signal is generated by one of the following 5 self-diagnostic result of micro-controller of DATC.

1) ¡°Lamp ON¡± status as a self-status diagnostic result of DATC

2) ¡°Lamp OFF¡± status as a self-status diagnostic result of DATC

3) ¡°Lamp flashin";
BA_ "Version" SG_ 2328014849 DATC_FnDstSnsrVal "20.09.00";
BA_ "UserSigValidity" SG_ 2328014849 DATC_FnDstSnsrVal 7;
BA_ "Description" SG_ 2328014849 DATC_FnDstSnsrVal "This signal indicate fine dust sensor value.

It is valid from 0 to 500.";
BA_ "Version" SG_ 1464 RRSAU_RRLBCU_GST_Byte0 "22.10.20";
BA_ "NetworkRequestHoldingTime" SG_ 1464 RRSAU_RRLBCU_GST_Byte0 5000;
BA_ "NetworkRequest" SG_ 1464 RRSAU_RRLBCU_GST_Byte0 0;
BA_ "UserSigValidity" SG_ 1464 RRSAU_RRLBCU_GST_Byte0 0;
BA_ "UsrSigPurpose" SG_ 1464 RRSAU_RRLBCU_GST_Byte0 4;
BA_ "Description" SG_ 1464 RRSAU_RRLBCU_GST_Byte0 "TP Index : 210";
BA_ "Version" SG_ 1464 RRSAU_RRLBCU_GST_Byte2 "22.10.20";
BA_ "NetworkRequestHoldingTime" SG_ 1464 RRSAU_RRLBCU_GST_Byte2 5000;
BA_ "NetworkRequest" SG_ 1464 RRSAU_RRLBCU_GST_Byte2 0;
BA_ "UserSigValidity" SG_ 1464 RRSAU_RRLBCU_GST_Byte2 0;
BA_ "UsrSigPurpose" SG_ 1464 RRSAU_RRLBCU_GST_Byte2 4;
BA_ "Description" SG_ 1464 RRSAU_RRLBCU_GST_Byte2 "TP Index : 210";
BA_ "Version" SG_ 1464 RRSAU_RRLBCU_GST_Byte3 "22.10.20";
BA_ "NetworkRequestHoldingTime" SG_ 1464 RRSAU_RRLBCU_GST_Byte3 5000;
BA_ "NetworkRequest" SG_ 1464 RRSAU_RRLBCU_GST_Byte3 0;
BA_ "UserSigValidity" SG_ 1464 RRSAU_RRLBCU_GST_Byte3 0;
BA_ "UsrSigPurpose" SG_ 1464 RRSAU_RRLBCU_GST_Byte3 4;
BA_ "Description" SG_ 1464 RRSAU_RRLBCU_GST_Byte3 "TP Index : 210";
BA_ "Version" SG_ 1464 RRSAU_RRLBCU_GST_Byte4 "22.10.20";
BA_ "NetworkRequestHoldingTime" SG_ 1464 RRSAU_RRLBCU_GST_Byte4 5000;
BA_ "NetworkRequest" SG_ 1464 RRSAU_RRLBCU_GST_Byte4 0;
BA_ "UserSigValidity" SG_ 1464 RRSAU_RRLBCU_GST_Byte4 0;
BA_ "UsrSigPurpose" SG_ 1464 RRSAU_RRLBCU_GST_Byte4 4;
BA_ "Description" SG_ 1464 RRSAU_RRLBCU_GST_Byte4 "TP Index : 210";
BA_ "Version" SG_ 1464 RRSAU_RRLBCU_GST_Byte5 "22.10.20";
BA_ "NetworkRequestHoldingTime" SG_ 1464 RRSAU_RRLBCU_GST_Byte5 5000;
BA_ "NetworkRequest" SG_ 1464 RRSAU_RRLBCU_GST_Byte5 0;
BA_ "UserSigValidity" SG_ 1464 RRSAU_RRLBCU_GST_Byte5 0;
BA_ "UsrSigPurpose" SG_ 1464 RRSAU_RRLBCU_GST_Byte5 4;
BA_ "Description" SG_ 1464 RRSAU_RRLBCU_GST_Byte5 "TP Index : 210";
BA_ "Version" SG_ 1464 RRSAU_RRLBCU_GST_Byte6 "22.10.20";
BA_ "NetworkRequestHoldingTime" SG_ 1464 RRSAU_RRLBCU_GST_Byte6 5000;
BA_ "NetworkRequest" SG_ 1464 RRSAU_RRLBCU_GST_Byte6 0;
BA_ "UserSigValidity" SG_ 1464 RRSAU_RRLBCU_GST_Byte6 0;
BA_ "UsrSigPurpose" SG_ 1464 RRSAU_RRLBCU_GST_Byte6 4;
BA_ "Description" SG_ 1464 RRSAU_RRLBCU_GST_Byte6 "TP Index : 210";
BA_ "Version" SG_ 1464 RRSAU_RRLBCU_GST_Byte7 "22.10.20";
BA_ "NetworkRequestHoldingTime" SG_ 1464 RRSAU_RRLBCU_GST_Byte7 5000;
BA_ "NetworkRequest" SG_ 1464 RRSAU_RRLBCU_GST_Byte7 0;
BA_ "UserSigValidity" SG_ 1464 RRSAU_RRLBCU_GST_Byte7 0;
BA_ "UsrSigPurpose" SG_ 1464 RRSAU_RRLBCU_GST_Byte7 4;
BA_ "Description" SG_ 1464 RRSAU_RRLBCU_GST_Byte7 "TP Index : 210";
BA_ "Version" SG_ 1464 RRSAU_RRLBCU_GST_Byte1 "22.10.20";
BA_ "NetworkRequestHoldingTime" SG_ 1464 RRSAU_RRLBCU_GST_Byte1 5000;
BA_ "NetworkRequest" SG_ 1464 RRSAU_RRLBCU_GST_Byte1 0;
BA_ "UserSigValidity" SG_ 1464 RRSAU_RRLBCU_GST_Byte1 0;
BA_ "UsrSigPurpose" SG_ 1464 RRSAU_RRLBCU_GST_Byte1 4;
BA_ "Description" SG_ 1464 RRSAU_RRLBCU_GST_Byte1 "TP Index : 210";
BA_ "Version" SG_ 1465 RLSAU_RLLBCU_GST_Byte0 "22.10.20";
BA_ "NetworkRequestHoldingTime" SG_ 1465 RLSAU_RLLBCU_GST_Byte0 5000;
BA_ "NetworkRequest" SG_ 1465 RLSAU_RLLBCU_GST_Byte0 0;
BA_ "UserSigValidity" SG_ 1465 RLSAU_RLLBCU_GST_Byte0 0;
BA_ "UsrSigPurpose" SG_ 1465 RLSAU_RLLBCU_GST_Byte0 4;
BA_ "Description" SG_ 1465 RLSAU_RLLBCU_GST_Byte0 "TP Index : 211";
BA_ "Version" SG_ 1465 RLSAU_RLLBCU_GST_Byte2 "22.10.20";
BA_ "NetworkRequestHoldingTime" SG_ 1465 RLSAU_RLLBCU_GST_Byte2 5000;
BA_ "NetworkRequest" SG_ 1465 RLSAU_RLLBCU_GST_Byte2 0;
BA_ "UserSigValidity" SG_ 1465 RLSAU_RLLBCU_GST_Byte2 0;
BA_ "UsrSigPurpose" SG_ 1465 RLSAU_RLLBCU_GST_Byte2 4;
BA_ "Description" SG_ 1465 RLSAU_RLLBCU_GST_Byte2 "TP Index : 211";
BA_ "Version" SG_ 1465 RLSAU_RLLBCU_GST_Byte3 "22.10.20";
BA_ "NetworkRequestHoldingTime" SG_ 1465 RLSAU_RLLBCU_GST_Byte3 5000;
BA_ "NetworkRequest" SG_ 1465 RLSAU_RLLBCU_GST_Byte3 0;
BA_ "UserSigValidity" SG_ 1465 RLSAU_RLLBCU_GST_Byte3 0;
BA_ "UsrSigPurpose" SG_ 1465 RLSAU_RLLBCU_GST_Byte3 4;
BA_ "Description" SG_ 1465 RLSAU_RLLBCU_GST_Byte3 "TP Index : 211";
BA_ "Version" SG_ 1465 RLSAU_RLLBCU_GST_Byte4 "22.10.20";
BA_ "NetworkRequestHoldingTime" SG_ 1465 RLSAU_RLLBCU_GST_Byte4 5000;
BA_ "NetworkRequest" SG_ 1465 RLSAU_RLLBCU_GST_Byte4 0;
BA_ "UserSigValidity" SG_ 1465 RLSAU_RLLBCU_GST_Byte4 0;
BA_ "UsrSigPurpose" SG_ 1465 RLSAU_RLLBCU_GST_Byte4 4;
BA_ "Description" SG_ 1465 RLSAU_RLLBCU_GST_Byte4 "TP Index : 211";
BA_ "Version" SG_ 1465 RLSAU_RLLBCU_GST_Byte5 "22.10.20";
BA_ "NetworkRequestHoldingTime" SG_ 1465 RLSAU_RLLBCU_GST_Byte5 5000;
BA_ "NetworkRequest" SG_ 1465 RLSAU_RLLBCU_GST_Byte5 0;
BA_ "UserSigValidity" SG_ 1465 RLSAU_RLLBCU_GST_Byte5 0;
BA_ "UsrSigPurpose" SG_ 1465 RLSAU_RLLBCU_GST_Byte5 4;
BA_ "Description" SG_ 1465 RLSAU_RLLBCU_GST_Byte5 "TP Index : 211";
BA_ "Version" SG_ 1465 RLSAU_RLLBCU_GST_Byte6 "22.10.20";
BA_ "NetworkRequestHoldingTime" SG_ 1465 RLSAU_RLLBCU_GST_Byte6 5000;
BA_ "NetworkRequest" SG_ 1465 RLSAU_RLLBCU_GST_Byte6 0;
BA_ "UserSigValidity" SG_ 1465 RLSAU_RLLBCU_GST_Byte6 0;
BA_ "UsrSigPurpose" SG_ 1465 RLSAU_RLLBCU_GST_Byte6 4;
BA_ "Description" SG_ 1465 RLSAU_RLLBCU_GST_Byte6 "TP Index : 211";
BA_ "Version" SG_ 1465 RLSAU_RLLBCU_GST_Byte7 "22.10.20";
BA_ "NetworkRequestHoldingTime" SG_ 1465 RLSAU_RLLBCU_GST_Byte7 5000;
BA_ "NetworkRequest" SG_ 1465 RLSAU_RLLBCU_GST_Byte7 0;
BA_ "UserSigValidity" SG_ 1465 RLSAU_RLLBCU_GST_Byte7 0;
BA_ "UsrSigPurpose" SG_ 1465 RLSAU_RLLBCU_GST_Byte7 4;
BA_ "Description" SG_ 1465 RLSAU_RLLBCU_GST_Byte7 "TP Index : 211";
BA_ "Version" SG_ 1465 RLSAU_RLLBCU_GST_Byte1 "22.10.20";
BA_ "NetworkRequestHoldingTime" SG_ 1465 RLSAU_RLLBCU_GST_Byte1 5000;
BA_ "NetworkRequest" SG_ 1465 RLSAU_RLLBCU_GST_Byte1 0;
BA_ "UserSigValidity" SG_ 1465 RLSAU_RLLBCU_GST_Byte1 0;
BA_ "UsrSigPurpose" SG_ 1465 RLSAU_RLLBCU_GST_Byte1 4;
BA_ "Description" SG_ 1465 RLSAU_RLLBCU_GST_Byte1 "TP Index : 211";
BA_ "Version" SG_ 1466 ATS_GST_Byte0 "22.07.01";
BA_ "NetworkRequestHoldingTime" SG_ 1466 ATS_GST_Byte0 5000;
BA_ "NetworkRequest" SG_ 1466 ATS_GST_Byte0 0;
BA_ "UserSigValidity" SG_ 1466 ATS_GST_Byte0 0;
BA_ "UsrSigPurpose" SG_ 1466 ATS_GST_Byte0 4;
BA_ "Description" SG_ 1466 ATS_GST_Byte0 "TP Index : 212";
BA_ "Version" SG_ 1466 ATS_GST_Byte2 "22.07.01";
BA_ "NetworkRequestHoldingTime" SG_ 1466 ATS_GST_Byte2 5000;
BA_ "NetworkRequest" SG_ 1466 ATS_GST_Byte2 0;
BA_ "UserSigValidity" SG_ 1466 ATS_GST_Byte2 0;
BA_ "UsrSigPurpose" SG_ 1466 ATS_GST_Byte2 4;
BA_ "Description" SG_ 1466 ATS_GST_Byte2 "TP Index : 212";
BA_ "Version" SG_ 1466 ATS_GST_Byte3 "22.07.01";
BA_ "NetworkRequestHoldingTime" SG_ 1466 ATS_GST_Byte3 5000;
BA_ "NetworkRequest" SG_ 1466 ATS_GST_Byte3 0;
BA_ "UserSigValidity" SG_ 1466 ATS_GST_Byte3 0;
BA_ "UsrSigPurpose" SG_ 1466 ATS_GST_Byte3 4;
BA_ "Description" SG_ 1466 ATS_GST_Byte3 "TP Index : 212";
BA_ "Version" SG_ 1466 ATS_GST_Byte4 "22.07.01";
BA_ "NetworkRequestHoldingTime" SG_ 1466 ATS_GST_Byte4 5000;
BA_ "NetworkRequest" SG_ 1466 ATS_GST_Byte4 0;
BA_ "UserSigValidity" SG_ 1466 ATS_GST_Byte4 0;
BA_ "UsrSigPurpose" SG_ 1466 ATS_GST_Byte4 4;
BA_ "Description" SG_ 1466 ATS_GST_Byte4 "TP Index : 212";
BA_ "Version" SG_ 1466 ATS_GST_Byte5 "22.07.01";
BA_ "NetworkRequestHoldingTime" SG_ 1466 ATS_GST_Byte5 5000;
BA_ "NetworkRequest" SG_ 1466 ATS_GST_Byte5 0;
BA_ "UserSigValidity" SG_ 1466 ATS_GST_Byte5 0;
BA_ "UsrSigPurpose" SG_ 1466 ATS_GST_Byte5 4;
BA_ "Description" SG_ 1466 ATS_GST_Byte5 "TP Index : 212";
BA_ "Version" SG_ 1466 ATS_GST_Byte6 "22.07.01";
BA_ "NetworkRequestHoldingTime" SG_ 1466 ATS_GST_Byte6 5000;
BA_ "NetworkRequest" SG_ 1466 ATS_GST_Byte6 0;
BA_ "UserSigValidity" SG_ 1466 ATS_GST_Byte6 0;
BA_ "UsrSigPurpose" SG_ 1466 ATS_GST_Byte6 4;
BA_ "Description" SG_ 1466 ATS_GST_Byte6 "TP Index : 212";
BA_ "Version" SG_ 1466 ATS_GST_Byte7 "22.07.01";
BA_ "NetworkRequestHoldingTime" SG_ 1466 ATS_GST_Byte7 5000;
BA_ "NetworkRequest" SG_ 1466 ATS_GST_Byte7 0;
BA_ "UserSigValidity" SG_ 1466 ATS_GST_Byte7 0;
BA_ "UsrSigPurpose" SG_ 1466 ATS_GST_Byte7 4;
BA_ "Description" SG_ 1466 ATS_GST_Byte7 "TP Index : 212";
BA_ "Version" SG_ 1466 ATS_GST_Byte1 "22.07.01";
BA_ "NetworkRequestHoldingTime" SG_ 1466 ATS_GST_Byte1 5000;
BA_ "NetworkRequest" SG_ 1466 ATS_GST_Byte1 0;
BA_ "UserSigValidity" SG_ 1466 ATS_GST_Byte1 0;
BA_ "UsrSigPurpose" SG_ 1466 ATS_GST_Byte1 4;
BA_ "Description" SG_ 1466 ATS_GST_Byte1 "TP Index : 212";
BA_ "Version" SG_ 491 CF_AVN_Roof_OprLvSet "21.07.05";
BA_ "UserSigValidity" SG_ 491 CF_AVN_Roof_OprLvSet 3;
BA_ "GenSigSendType" SG_ 491 CF_AVN_Roof_OprLvSet 4;
BA_ "Description" SG_ 491 CF_AVN_Roof_OprLvSet "Smart Glass(Roof) usm setting signal";
BA_ "Version" SG_ 491 CF_AVN_3rdRightDoor_OptLvlSet "21.07.05";
BA_ "UserSigValidity" SG_ 491 CF_AVN_3rdRightDoor_OptLvlSet 3;
BA_ "GenSigSendType" SG_ 491 CF_AVN_3rdRightDoor_OptLvlSet 4;
BA_ "Description" SG_ 491 CF_AVN_3rdRightDoor_OptLvlSet "Smart Glass (3rd Right Door) usm set signal";
BA_ "Version" SG_ 491 CF_AVN_RearDoor_OptLvlSet "21.07.05";
BA_ "UserSigValidity" SG_ 491 CF_AVN_RearDoor_OptLvlSet 3;
BA_ "GenSigSendType" SG_ 491 CF_AVN_RearDoor_OptLvlSet 4;
BA_ "Description" SG_ 491 CF_AVN_RearDoor_OptLvlSet "Smart Glass (Rear Door) usm set signal";
BA_ "Version" SG_ 491 CF_AVN_RollBlindOnOffSet "21.07.07";
BA_ "UserSigValidity" SG_ 491 CF_AVN_RollBlindOnOffSet 3;
BA_ "GenSigSendType" SG_ 491 CF_AVN_RollBlindOnOffSet 4;
BA_ "Description" SG_ 491 CF_AVN_RollBlindOnOffSet "Related Smar Glass RollBlind On,Off for USM set signal";
BA_ "Version" SG_ 491 CF_AVN_CluThmAutoSet_New "21.11.07";
BA_ "UserSigValidity" SG_ 491 CF_AVN_CluThmAutoSet_New 3;
BA_ "GenSigSendType" SG_ 491 CF_AVN_CluThmAutoSet_New 4;
BA_ "Description" SG_ 491 CF_AVN_CluThmAutoSet_New "this signal is Cluster theme Auto set signal for New cluster theme";
BA_ "Version" SG_ 491 CF_AVN_CluThmSet_New "21.11.07";
BA_ "UserSigValidity" SG_ 491 CF_AVN_CluThmSet_New 3;
BA_ "GenSigSendType" SG_ 491 CF_AVN_CluThmSet_New 4;
BA_ "Description" SG_ 491 CF_AVN_CluThmSet_New "This signal is Cluster theme large category menu select for Cluster New theme";
BA_ "Version" SG_ 491 CF_AVN_CluThmDtlSet_New "23.01.03";
BA_ "UserSigValidity" SG_ 491 CF_AVN_CluThmDtlSet_New 3;
BA_ "GenSigSendType" SG_ 491 CF_AVN_CluThmDtlSet_New 4;
BA_ "Description" SG_ 491 CF_AVN_CluThmDtlSet_New "This signal is Cluster Theme small category menu select for Cluster New Theme";
BA_ "Version" SG_ 491 CF_AVN_MdLmpAIVoiceUSMNValueSet "21.12.06";
BA_ "UserSigValidity" SG_ 491 CF_AVN_MdLmpAIVoiceUSMNValueSet 3;
BA_ "GenSigSendType" SG_ 491 CF_AVN_MdLmpAIVoiceUSMNValueSet 4;
BA_ "Description" SG_ 491 CF_AVN_MdLmpAIVoiceUSMNValueSet "Voice recognition link to modd lamp set signal";
BA_ "Version" SG_ 491 CF_AVN_2ndLeftDoor_OptLvSet "21.07.05";
BA_ "UserSigValidity" SG_ 491 CF_AVN_2ndLeftDoor_OptLvSet 3;
BA_ "GenSigSendType" SG_ 491 CF_AVN_2ndLeftDoor_OptLvSet 4;
BA_ "Description" SG_ 491 CF_AVN_2ndLeftDoor_OptLvSet "Smart Glass (2nd Left Door) Usm set signal";
BA_ "Version" SG_ 491 CF_AVN_DWL_SelectNvalueSet "22.05.02";
BA_ "UserSigValidity" SG_ 491 CF_AVN_DWL_SelectNvalueSet 3;
BA_ "GenSigSendType" SG_ 491 CF_AVN_DWL_SelectNvalueSet 4;
BA_ "Description" SG_ 491 CF_AVN_DWL_SelectNvalueSet "Dynamic welcome light usm set signal";
BA_ "Version" SG_ 491 PwrDRClosingDrvDrReq "22.04.01";
BA_ "UserSigValidity" SG_ 491 PwrDRClosingDrvDrReq 3;
BA_ "GenSigSendType" SG_ 491 PwrDRClosingDrvDrReq 4;
BA_ "Description" SG_ 491 PwrDRClosingDrvDrReq "Request signal for Driver Power Door Closing";
BA_ "Version" SG_ 491 CF_Gway_WPCAnimationNvalueSet "22.04.01";
BA_ "UserSigValidity" SG_ 491 CF_Gway_WPCAnimationNvalueSet 3;
BA_ "GenSigSendType" SG_ 491 CF_Gway_WPCAnimationNvalueSet 4;
BA_ "Description" SG_ 491 CF_Gway_WPCAnimationNvalueSet "USM set signal for wireless charging indicator";
BA_ "Version" SG_ 491 PwrDRClosingAstDrReq "22.04.01";
BA_ "UserSigValidity" SG_ 491 PwrDRClosingAstDrReq 3;
BA_ "GenSigSendType" SG_ 491 PwrDRClosingAstDrReq 4;
BA_ "Description" SG_ 491 PwrDRClosingAstDrReq "Request signal for Assistant Power Door Closing";
BA_ "Version" SG_ 491 PwrDRClosingRLDrReq "22.04.01";
BA_ "UserSigValidity" SG_ 491 PwrDRClosingRLDrReq 3;
BA_ "GenSigSendType" SG_ 491 PwrDRClosingRLDrReq 4;
BA_ "Description" SG_ 491 PwrDRClosingRLDrReq "Request signal for Rear Left Power Door Closing";
BA_ "Version" SG_ 491 PwrDrClosingRRDrReq "22.04.01";
BA_ "UserSigValidity" SG_ 491 PwrDrClosingRRDrReq 3;
BA_ "GenSigSendType" SG_ 491 PwrDrClosingRRDrReq 4;
BA_ "Description" SG_ 491 PwrDrClosingRRDrReq "Request signal for Rear Right Power Door Closing";
BA_ "Version" SG_ 491 USM_BtnIllumiAlwaysOnReq "22.04.02";
BA_ "UserSigValidity" SG_ 491 USM_BtnIllumiAlwaysOnReq 3;
BA_ "GenSigSendType" SG_ 491 USM_BtnIllumiAlwaysOnReq 4;
BA_ "Description" SG_ 491 USM_BtnIllumiAlwaysOnReq "USM Request for always turning on button illumination.";
BA_ "Version" SG_ 491 CF_AVN_LKAWrngVolNvalueSet "22.05.04";
BA_ "UserSigValidity" SG_ 491 CF_AVN_LKAWrngVolNvalueSet 3;
BA_ "GenSigSendType" SG_ 491 CF_AVN_LKAWrngVolNvalueSet 4;
BA_ "Description" SG_ 491 CF_AVN_LKAWrngVolNvalueSet "LKA Warning Volume USM Set signal";
BA_ "Version" SG_ 491 DAB_IlluminationVrModeSet "22.06.00";
BA_ "UserSigValidity" SG_ 491 DAB_IlluminationVrModeSet 3;
BA_ "GenSigSendType" SG_ 491 DAB_IlluminationVrModeSet 4;
BA_ "Version" SG_ 491 USM_IllAlwaysOnwithPSTNReq "22.06.00";
BA_ "UserSigValidity" SG_ 491 USM_IllAlwaysOnwithPSTNReq 3;
BA_ "GenSigSendType" SG_ 491 USM_IllAlwaysOnwithPSTNReq 4;
BA_ "Description" SG_ 491 USM_IllAlwaysOnwithPSTNReq "USM set signal for Illumination & PSTN";
BA_ "Version" SG_ 491 CF_AVN_AutoStopTimerResetSet "22.06.05";
BA_ "UserSigValidity" SG_ 491 CF_AVN_AutoStopTimerResetSet 3;
BA_ "GenSigSendType" SG_ 491 CF_AVN_AutoStopTimerResetSet 4;
BA_ "Description" SG_ 491 CF_AVN_AutoStopTimerResetSet "USM Set signal for Cluster Auto stop reset menu";
BA_ "Version" SG_ 491 CF_AVN_2ndRightDoor_OptLvSet "21.07.05";
BA_ "UserSigValidity" SG_ 491 CF_AVN_2ndRightDoor_OptLvSet 3;
BA_ "GenSigSendType" SG_ 491 CF_AVN_2ndRightDoor_OptLvSet 4;
BA_ "Description" SG_ 491 CF_AVN_2ndRightDoor_OptLvSet "Smart Glass (2nd Right Door) usm set signal";
BA_ "Version" SG_ 491 USM_RrCurtainSet "22.07.01";
BA_ "UserSigValidity" SG_ 491 USM_RrCurtainSet 3;
BA_ "GenSigSendType" SG_ 491 USM_RrCurtainSet 4;
BA_ "Description" SG_ 491 USM_RrCurtainSet "USM request for Rear Curtain On/Off setting";
BA_ "Version" SG_ 491 CF_AVN_3rdLeftDoor_OptLvlSet "21.07.05";
BA_ "UserSigValidity" SG_ 491 CF_AVN_3rdLeftDoor_OptLvlSet 3;
BA_ "GenSigSendType" SG_ 491 CF_AVN_3rdLeftDoor_OptLvlSet 4;
BA_ "Description" SG_ 491 CF_AVN_3rdLeftDoor_OptLvlSet "Smart Glass (3rd left door) usm set signal";
BA_ "Version" SG_ 2151682049 ACU_Crc2Val "21.09.03";
BA_ "UserSigValidity" SG_ 2151682049 ACU_Crc2Val 3;
BA_ "GenSigStartValue" SG_ 2151682049 ACU_Crc2Val 65535;
BA_ "GenSigSendType" SG_ 2151682049 ACU_Crc2Val 2;
BA_ "Description" SG_ 2151682049 ACU_Crc2Val "The data area for CRC calculation is based on the data length (DLC) of the message DB.

The CRC shall be calculated over the entire data block (excluding the CRC bytes) including the user data, alive counter and Data ID



- CRC Polynomial (0x1021) , Ini";
BA_ "Version" SG_ 2151682049 ACU_AlvCnt2Val "21.09.03";
BA_ "UserSigValidity" SG_ 2151682049 ACU_AlvCnt2Val 3;
BA_ "GenSigSendType" SG_ 2151682049 ACU_AlvCnt2Val 2;
BA_ "Description" SG_ 2151682049 ACU_AlvCnt2Val "For the first transmission request for a data element the counter shall be initialized with 0 and shall be incremented by 1 for every subsequent send request. 

When the counter reaches the maximum value(0xFF), then it shall restart with 0 for the next s";
BA_ "Version" SG_ 2151682049 ACU_CrshActvSta "17.12.00";
BA_ "UserSigValidity" SG_ 2151682049 ACU_CrshActvSta 3;
BA_ "GenSigSendType" SG_ 2151682049 ACU_CrshActvSta 2;
BA_ "Description" SG_ 2151682049 ACU_CrshActvSta "Information regarding the crash. It indicates crash is active or inactive.";
BA_ "Version" SG_ 2151682049 ACU_CrshInfo "19.02.06";
BA_ "UserSigValidity" SG_ 2151682049 ACU_CrshInfo 3;
BA_ "GenSigSendType" SG_ 2151682049 ACU_CrshInfo 2;
BA_ "Description" SG_ 2151682049 ACU_CrshInfo "1)When crash output is issued, this signal is transmitted as 0x2. 

2)When crash output is not issued and ACU meets MCB requirement of ESC.  this signal is transmitted as 0x1.



Just then If ACU receives feedback signal from ESC this signal is transmitt";
BA_ "Version" SG_ 2151682049 ACU_CrshTyp "19.02.06";
BA_ "UserSigValidity" SG_ 2151682049 ACU_CrshTyp 3;
BA_ "GenSigSendType" SG_ 2151682049 ACU_CrshTyp 2;
BA_ "Description" SG_ 2151682049 ACU_CrshTyp "This signal indicates types of  crash. 

If a collision occurs continuously at same IGN cycle each crash type bit set to 1 according to the type of collision.



1)First byte Information 

xxxx xxxxB : No deployment Crash (Crash output signal not issued)";
BA_ "Version" SG_ 550 PSS_RL_StSldFwdMvBtn "22.10.20";
BA_ "NetworkRequestHoldingTime" SG_ 550 PSS_RL_StSldFwdMvBtn 5000;
BA_ "NetworkRequest" SG_ 550 PSS_RL_StSldFwdMvBtn 0;
BA_ "UserSigValidity" SG_ 550 PSS_RL_StSldFwdMvBtn 0;
BA_ "GenSigSendType" SG_ 550 PSS_RL_StSldFwdMvBtn 4;
BA_ "Description" SG_ 550 PSS_RL_StSldFwdMvBtn "PSS_RL_SlideForwardMoveButton";
BA_ "Version" SG_ 550 PSS_RL_StTltDnMvBtn "22.10.20";
BA_ "NetworkRequestHoldingTime" SG_ 550 PSS_RL_StTltDnMvBtn 5000;
BA_ "NetworkRequest" SG_ 550 PSS_RL_StTltDnMvBtn 0;
BA_ "UserSigValidity" SG_ 550 PSS_RL_StTltDnMvBtn 0;
BA_ "GenSigSendType" SG_ 550 PSS_RL_StTltDnMvBtn 4;
BA_ "Description" SG_ 550 PSS_RL_StTltDnMvBtn "PSS_RL_TiltDownMoveButton";
BA_ "Version" SG_ 550 PSS_RL_StHRestUpMvBtn "22.10.20";
BA_ "NetworkRequestHoldingTime" SG_ 550 PSS_RL_StHRestUpMvBtn 5000;
BA_ "NetworkRequest" SG_ 550 PSS_RL_StHRestUpMvBtn 0;
BA_ "UserSigValidity" SG_ 550 PSS_RL_StHRestUpMvBtn 0;
BA_ "GenSigSendType" SG_ 550 PSS_RL_StHRestUpMvBtn 4;
BA_ "Description" SG_ 550 PSS_RL_StHRestUpMvBtn "PSS_RL_StHRestUpMvBtn";
BA_ "Version" SG_ 550 PSS_RL_StHRestDnMvBtn "22.10.20";
BA_ "NetworkRequestHoldingTime" SG_ 550 PSS_RL_StHRestDnMvBtn 5000;
BA_ "NetworkRequest" SG_ 550 PSS_RL_StHRestDnMvBtn 0;
BA_ "UserSigValidity" SG_ 550 PSS_RL_StHRestDnMvBtn 0;
BA_ "GenSigSendType" SG_ 550 PSS_RL_StHRestDnMvBtn 4;
BA_ "Description" SG_ 550 PSS_RL_StHRestDnMvBtn "PSS_RL_StHRestDnMvBtn";
BA_ "Version" SG_ 550 PSS_RL_StHRestFwdMvBtn "22.10.20";
BA_ "NetworkRequestHoldingTime" SG_ 550 PSS_RL_StHRestFwdMvBtn 5000;
BA_ "NetworkRequest" SG_ 550 PSS_RL_StHRestFwdMvBtn 0;
BA_ "UserSigValidity" SG_ 550 PSS_RL_StHRestFwdMvBtn 0;
BA_ "GenSigSendType" SG_ 550 PSS_RL_StHRestFwdMvBtn 4;
BA_ "Description" SG_ 550 PSS_RL_StHRestFwdMvBtn "PSS_RL_StHRestFwdMvBtn";
BA_ "Version" SG_ 550 PSS_RL_StHRestBwdMvBtn "22.10.20";
BA_ "NetworkRequestHoldingTime" SG_ 550 PSS_RL_StHRestBwdMvBtn 5000;
BA_ "NetworkRequest" SG_ 550 PSS_RL_StHRestBwdMvBtn 0;
BA_ "UserSigValidity" SG_ 550 PSS_RL_StHRestBwdMvBtn 0;
BA_ "GenSigSendType" SG_ 550 PSS_RL_StHRestBwdMvBtn 4;
BA_ "Description" SG_ 550 PSS_RL_StHRestBwdMvBtn "PSS_RL_StHRestBwdMvBtn";
BA_ "Version" SG_ 550 PSS_RL_StSldBwdMvBtn "22.10.20";
BA_ "NetworkRequestHoldingTime" SG_ 550 PSS_RL_StSldBwdMvBtn 5000;
BA_ "NetworkRequest" SG_ 550 PSS_RL_StSldBwdMvBtn 0;
BA_ "UserSigValidity" SG_ 550 PSS_RL_StSldBwdMvBtn 0;
BA_ "GenSigSendType" SG_ 550 PSS_RL_StSldBwdMvBtn 4;
BA_ "Description" SG_ 550 PSS_RL_StSldBwdMvBtn "PSS_RL_SlideBackwardMoveButton";
BA_ "Version" SG_ 550 PSS_RL_StLegRestUpBtn "22.10.20";
BA_ "NetworkRequestHoldingTime" SG_ 550 PSS_RL_StLegRestUpBtn 5000;
BA_ "NetworkRequest" SG_ 550 PSS_RL_StLegRestUpBtn 0;
BA_ "UserSigValidity" SG_ 550 PSS_RL_StLegRestUpBtn 0;
BA_ "GenSigSendType" SG_ 550 PSS_RL_StLegRestUpBtn 4;
BA_ "Description" SG_ 550 PSS_RL_StLegRestUpBtn "PSS_RL_LegUpMoveButton";
BA_ "Version" SG_ 550 PSS_RL_StLegRestDnBtn "22.10.20";
BA_ "NetworkRequestHoldingTime" SG_ 550 PSS_RL_StLegRestDnBtn 5000;
BA_ "NetworkRequest" SG_ 550 PSS_RL_StLegRestDnBtn 0;
BA_ "UserSigValidity" SG_ 550 PSS_RL_StLegRestDnBtn 0;
BA_ "GenSigSendType" SG_ 550 PSS_RL_StLegRestDnBtn 4;
BA_ "Description" SG_ 550 PSS_RL_StLegRestDnBtn "PSS_RL_LegDownMoveButton";
BA_ "Version" SG_ 550 PSS_RL_StLegRestExtFwdBtn "22.11.09";
BA_ "NetworkRequestHoldingTime" SG_ 550 PSS_RL_StLegRestExtFwdBtn 5000;
BA_ "NetworkRequest" SG_ 550 PSS_RL_StLegRestExtFwdBtn 0;
BA_ "UserSigValidity" SG_ 550 PSS_RL_StLegRestExtFwdBtn 0;
BA_ "GenSigSendType" SG_ 550 PSS_RL_StLegRestExtFwdBtn 4;
BA_ "Description" SG_ 550 PSS_RL_StLegRestExtFwdBtn "PSS_RL_LegExtFwdMoveButton";
BA_ "Version" SG_ 550 PSS_RL_StLegRestExtBwdBtn "22.11.09";
BA_ "NetworkRequestHoldingTime" SG_ 550 PSS_RL_StLegRestExtBwdBtn 5000;
BA_ "NetworkRequest" SG_ 550 PSS_RL_StLegRestExtBwdBtn 0;
BA_ "UserSigValidity" SG_ 550 PSS_RL_StLegRestExtBwdBtn 0;
BA_ "GenSigSendType" SG_ 550 PSS_RL_StLegRestExtBwdBtn 4;
BA_ "Description" SG_ 550 PSS_RL_StLegRestExtBwdBtn "PSS_RL_LegExtBwdMoveButton";
BA_ "Version" SG_ 550 PSS_RL_StRlxModeBtn "22.10.20";
BA_ "NetworkRequestHoldingTime" SG_ 550 PSS_RL_StRlxModeBtn 5000;
BA_ "NetworkRequest" SG_ 550 PSS_RL_StRlxModeBtn 0;
BA_ "UserSigValidity" SG_ 550 PSS_RL_StRlxModeBtn 0;
BA_ "GenSigSendType" SG_ 550 PSS_RL_StRlxModeBtn 4;
BA_ "Description" SG_ 550 PSS_RL_StRlxModeBtn "PSS_RL_RelaxModeButton";
BA_ "Version" SG_ 550 PSS_RL_StRlxReturnBtn "22.10.20";
BA_ "NetworkRequestHoldingTime" SG_ 550 PSS_RL_StRlxReturnBtn 5000;
BA_ "NetworkRequest" SG_ 550 PSS_RL_StRlxReturnBtn 0;
BA_ "UserSigValidity" SG_ 550 PSS_RL_StRlxReturnBtn 0;
BA_ "GenSigSendType" SG_ 550 PSS_RL_StRlxReturnBtn 4;
BA_ "Description" SG_ 550 PSS_RL_StRlxReturnBtn "PSS_RL_RelaxReturnButton";
BA_ "Version" SG_ 550 PSS_RL_StRlxTltUpMvBtn "22.10.20";
BA_ "NetworkRequestHoldingTime" SG_ 550 PSS_RL_StRlxTltUpMvBtn 5000;
BA_ "NetworkRequest" SG_ 550 PSS_RL_StRlxTltUpMvBtn 0;
BA_ "UserSigValidity" SG_ 550 PSS_RL_StRlxTltUpMvBtn 0;
BA_ "GenSigSendType" SG_ 550 PSS_RL_StRlxTltUpMvBtn 4;
BA_ "Description" SG_ 550 PSS_RL_StRlxTltUpMvBtn "PSS_RL_RelaxTiltUpMoveButton";
BA_ "Version" SG_ 550 PSS_RL_StRlxTltDnMvBtn "22.10.20";
BA_ "NetworkRequestHoldingTime" SG_ 550 PSS_RL_StRlxTltDnMvBtn 5000;
BA_ "NetworkRequest" SG_ 550 PSS_RL_StRlxTltDnMvBtn 0;
BA_ "UserSigValidity" SG_ 550 PSS_RL_StRlxTltDnMvBtn 0;
BA_ "GenSigSendType" SG_ 550 PSS_RL_StRlxTltDnMvBtn 4;
BA_ "Description" SG_ 550 PSS_RL_StRlxTltDnMvBtn "PSS_RL_RelaxTiltDownMoveButton";
BA_ "Version" SG_ 550 PSS_RL_StMnlRlxModeBtn "22.10.20";
BA_ "NetworkRequestHoldingTime" SG_ 550 PSS_RL_StMnlRlxModeBtn 5000;
BA_ "NetworkRequest" SG_ 550 PSS_RL_StMnlRlxModeBtn 0;
BA_ "UserSigValidity" SG_ 550 PSS_RL_StMnlRlxModeBtn 0;
BA_ "GenSigSendType" SG_ 550 PSS_RL_StMnlRlxModeBtn 4;
BA_ "Description" SG_ 550 PSS_RL_StMnlRlxModeBtn "PSS_RL_MnlRelaxModeButton";
BA_ "Version" SG_ 550 PSS_RL_StMnlRlxReturnBtn "22.10.20";
BA_ "NetworkRequestHoldingTime" SG_ 550 PSS_RL_StMnlRlxReturnBtn 5000;
BA_ "NetworkRequest" SG_ 550 PSS_RL_StMnlRlxReturnBtn 0;
BA_ "UserSigValidity" SG_ 550 PSS_RL_StMnlRlxReturnBtn 0;
BA_ "GenSigSendType" SG_ 550 PSS_RL_StMnlRlxReturnBtn 4;
BA_ "Description" SG_ 550 PSS_RL_StMnlRlxReturnBtn "PSS_RL_MnlRelaxReturnButton";
BA_ "Version" SG_ 550 PSS_RL_StRclFwdMvBtn "22.10.20";
BA_ "NetworkRequestHoldingTime" SG_ 550 PSS_RL_StRclFwdMvBtn 5000;
BA_ "NetworkRequest" SG_ 550 PSS_RL_StRclFwdMvBtn 0;
BA_ "UserSigValidity" SG_ 550 PSS_RL_StRclFwdMvBtn 0;
BA_ "GenSigSendType" SG_ 550 PSS_RL_StRclFwdMvBtn 4;
BA_ "Description" SG_ 550 PSS_RL_StRclFwdMvBtn "PSS_RL_ReclinerForwardMoveButton";
BA_ "Version" SG_ 550 PSS_RL_WalkInSwitchSts "22.10.20";
BA_ "NetworkRequestHoldingTime" SG_ 550 PSS_RL_WalkInSwitchSts 5000;
BA_ "NetworkRequest" SG_ 550 PSS_RL_WalkInSwitchSts 0;
BA_ "UserSigValidity" SG_ 550 PSS_RL_WalkInSwitchSts 0;
BA_ "GenSigSendType" SG_ 550 PSS_RL_WalkInSwitchSts 4;
BA_ "Description" SG_ 550 PSS_RL_WalkInSwitchSts "PSS_RL_WalkInSwitchStatus";
BA_ "Version" SG_ 550 PSS_RL_StRclBwdMvBtn "22.10.20";
BA_ "NetworkRequestHoldingTime" SG_ 550 PSS_RL_StRclBwdMvBtn 5000;
BA_ "NetworkRequest" SG_ 550 PSS_RL_StRclBwdMvBtn 0;
BA_ "UserSigValidity" SG_ 550 PSS_RL_StRclBwdMvBtn 0;
BA_ "GenSigSendType" SG_ 550 PSS_RL_StRclBwdMvBtn 4;
BA_ "Description" SG_ 550 PSS_RL_StRclBwdMvBtn "PSS_RL_ReclinerBackwardMoveButton";
BA_ "Version" SG_ 550 PSS_RL_StTltUpMvBtn "22.10.20";
BA_ "NetworkRequestHoldingTime" SG_ 550 PSS_RL_StTltUpMvBtn 5000;
BA_ "NetworkRequest" SG_ 550 PSS_RL_StTltUpMvBtn 0;
BA_ "UserSigValidity" SG_ 550 PSS_RL_StTltUpMvBtn 0;
BA_ "GenSigSendType" SG_ 550 PSS_RL_StTltUpMvBtn 4;
BA_ "Description" SG_ 550 PSS_RL_StTltUpMvBtn "PSS_RL_TiltUpMoveButton";
BA_ "Version" SG_ 551 PSS_RL_StOneTchWlkinCushBtn "22.10.20";
BA_ "NetworkRequestHoldingTime" SG_ 551 PSS_RL_StOneTchWlkinCushBtn 5000;
BA_ "NetworkRequest" SG_ 551 PSS_RL_StOneTchWlkinCushBtn 0;
BA_ "UserSigValidity" SG_ 551 PSS_RL_StOneTchWlkinCushBtn 0;
BA_ "GenSigSendType" SG_ 551 PSS_RL_StOneTchWlkinCushBtn 4;
BA_ "Description" SG_ 551 PSS_RL_StOneTchWlkinCushBtn "PSS_RL_OnetouchWalkinCushMoveButton";
BA_ "Version" SG_ 551 PSS_RL_StOneTchWlkinBackBtn "22.10.20";
BA_ "NetworkRequestHoldingTime" SG_ 551 PSS_RL_StOneTchWlkinBackBtn 5000;
BA_ "NetworkRequest" SG_ 551 PSS_RL_StOneTchWlkinBackBtn 0;
BA_ "UserSigValidity" SG_ 551 PSS_RL_StOneTchWlkinBackBtn 0;
BA_ "GenSigSendType" SG_ 551 PSS_RL_StOneTchWlkinBackBtn 4;
BA_ "Description" SG_ 551 PSS_RL_StOneTchWlkinBackBtn "PSS_RL_OnetouchWalkinBackMoveButton";
BA_ "Version" SG_ 551 PSS_RL_MomoryP1Cmd "22.10.20";
BA_ "NetworkRequestHoldingTime" SG_ 551 PSS_RL_MomoryP1Cmd 5000;
BA_ "NetworkRequest" SG_ 551 PSS_RL_MomoryP1Cmd 0;
BA_ "UserSigValidity" SG_ 551 PSS_RL_MomoryP1Cmd 0;
BA_ "GenSigSendType" SG_ 551 PSS_RL_MomoryP1Cmd 4;
BA_ "Description" SG_ 551 PSS_RL_MomoryP1Cmd "PSS_RL_SeatPositionMemoryP1Request";
BA_ "Version" SG_ 551 PSS_RL_MomoryP2Cmd "22.10.20";
BA_ "NetworkRequestHoldingTime" SG_ 551 PSS_RL_MomoryP2Cmd 5000;
BA_ "NetworkRequest" SG_ 551 PSS_RL_MomoryP2Cmd 0;
BA_ "UserSigValidity" SG_ 551 PSS_RL_MomoryP2Cmd 0;
BA_ "GenSigSendType" SG_ 551 PSS_RL_MomoryP2Cmd 4;
BA_ "Description" SG_ 551 PSS_RL_MomoryP2Cmd "PSS_RL_SeatPositionMemoryP2Request";
BA_ "Version" SG_ 2378399489 GATEWAY_CrcVal "21.09.03";
BA_ "RoutingFactor" SG_ 2378399489 GATEWAY_CrcVal 0;
BA_ "UserSigValidity" SG_ 2378399489 GATEWAY_CrcVal 0;
BA_ "Description" SG_ 2378399489 GATEWAY_CrcVal "The data area for CRC calculation is based on the data length (DLC) of the message DB.

The CRC shall be calculated over the entire data block (excluding the CRC bytes) including the user data, alive counter and Data ID 

 

- CRC Polynomial (0x1D) , Ini";
BA_ "Version" SG_ 2378399489 GATEWAY_AlvCntVal "21.09.03";
BA_ "RoutingFactor" SG_ 2378399489 GATEWAY_AlvCntVal 0;
BA_ "UserSigValidity" SG_ 2378399489 GATEWAY_AlvCntVal 0;
BA_ "Description" SG_ 2378399489 GATEWAY_AlvCntVal "For the first transmission request for a data element the counter shall be initialized with 0 and shall be incremented by 1

for every subsequent send request. When the counter reaches the maximum value(0xE), then it shall restart with 0 for the next sen";
BA_ "Version" SG_ 2378399489 GATEWAY_HS_B1_STS "21.06.12";
BA_ "RoutingFactor" SG_ 2378399489 GATEWAY_HS_B1_STS 0;
BA_ "UserSigValidity" SG_ 2378399489 GATEWAY_HS_B1_STS 0;
BA_ "Version" SG_ 2378399489 GATEWAY_HS_B2_STS "21.06.12";
BA_ "RoutingFactor" SG_ 2378399489 GATEWAY_HS_B2_STS 0;
BA_ "UserSigValidity" SG_ 2378399489 GATEWAY_HS_B2_STS 0;
BA_ "Version" SG_ 2378399489 GATEWAY_HS_D_STS "19.01.12";
BA_ "RoutingFactor" SG_ 2378399489 GATEWAY_HS_D_STS 0;
BA_ "UserSigValidity" SG_ 2378399489 GATEWAY_HS_D_STS 0;
BA_ "Version" SG_ 2378399489 GATEWAY_HS_I_STS "17.11.00";
BA_ "RoutingFactor" SG_ 2378399489 GATEWAY_HS_I_STS 0;
BA_ "UserSigValidity" SG_ 2378399489 GATEWAY_HS_I_STS 0;
BA_ "Version" SG_ 2378399489 GATEWAY_HS_M_STS "21.06.12";
BA_ "RoutingFactor" SG_ 2378399489 GATEWAY_HS_M_STS 0;
BA_ "UserSigValidity" SG_ 2378399489 GATEWAY_HS_M_STS 0;
BA_ "Version" SG_ 2378399489 GATEWAY_FD_C_STS "17.11.00";
BA_ "RoutingFactor" SG_ 2378399489 GATEWAY_FD_C_STS 0;
BA_ "UserSigValidity" SG_ 2378399489 GATEWAY_FD_C_STS 0;
BA_ "Version" SG_ 2378399489 GATEWAY_FD_P1_STS "21.06.12";
BA_ "RoutingFactor" SG_ 2378399489 GATEWAY_FD_P1_STS 0;
BA_ "UserSigValidity" SG_ 2378399489 GATEWAY_FD_P1_STS 0;
BA_ "Version" SG_ 2378399489 GATEWAY_FD_P2_STS "21.06.12";
BA_ "RoutingFactor" SG_ 2378399489 GATEWAY_FD_P2_STS 0;
BA_ "UserSigValidity" SG_ 2378399489 GATEWAY_FD_P2_STS 0;
BA_ "Version" SG_ 2378399489 GATEWAY_FD_E_STS "17.11.00";
BA_ "RoutingFactor" SG_ 2378399489 GATEWAY_FD_E_STS 0;
BA_ "UserSigValidity" SG_ 2378399489 GATEWAY_FD_E_STS 0;
BA_ "Version" SG_ 2378399489 GATEWAY_FD_I_STS "20.03.01";
BA_ "RoutingFactor" SG_ 2378399489 GATEWAY_FD_I_STS 0;
BA_ "UserSigValidity" SG_ 2378399489 GATEWAY_FD_I_STS 0;
BA_ "Version" SG_ 2378399489 GATEWAY_ERT_ACT_STS "22.05.02";
BA_ "RoutingFactor" SG_ 2378399489 GATEWAY_ERT_ACT_STS 0;
BA_ "UserSigValidity" SG_ 2378399489 GATEWAY_ERT_ACT_STS 0;
BA_ "Description" SG_ 2378399489 GATEWAY_ERT_ACT_STS "ERT_ACT Value";
BA_ "Version" SG_ 552 PSS_RL_AstHRestFwdMvBtn "22.10.20";
BA_ "NetworkRequestHoldingTime" SG_ 552 PSS_RL_AstHRestFwdMvBtn 5000;
BA_ "NetworkRequest" SG_ 552 PSS_RL_AstHRestFwdMvBtn 0;
BA_ "UserSigValidity" SG_ 552 PSS_RL_AstHRestFwdMvBtn 0;
BA_ "GenSigSendType" SG_ 552 PSS_RL_AstHRestFwdMvBtn 4;
BA_ "Description" SG_ 552 PSS_RL_AstHRestFwdMvBtn "PSS_RL_AstStHead Rest UpMoveButton";
BA_ "Version" SG_ 552 PSS_RL_AstRclBwdMvBtn "22.10.20";
BA_ "NetworkRequestHoldingTime" SG_ 552 PSS_RL_AstRclBwdMvBtn 5000;
BA_ "NetworkRequest" SG_ 552 PSS_RL_AstRclBwdMvBtn 0;
BA_ "UserSigValidity" SG_ 552 PSS_RL_AstRclBwdMvBtn 0;
BA_ "GenSigSendType" SG_ 552 PSS_RL_AstRclBwdMvBtn 4;
BA_ "Description" SG_ 552 PSS_RL_AstRclBwdMvBtn "PSS_RL_AstStReclinerBackwardMoveButton";
BA_ "Version" SG_ 552 PSS_RL_AstSldFwdMvBtn "22.10.20";
BA_ "NetworkRequestHoldingTime" SG_ 552 PSS_RL_AstSldFwdMvBtn 5000;
BA_ "NetworkRequest" SG_ 552 PSS_RL_AstSldFwdMvBtn 0;
BA_ "UserSigValidity" SG_ 552 PSS_RL_AstSldFwdMvBtn 0;
BA_ "GenSigSendType" SG_ 552 PSS_RL_AstSldFwdMvBtn 4;
BA_ "Description" SG_ 552 PSS_RL_AstSldFwdMvBtn "PSS_RL_AstStSlideForwardMoveButton";
BA_ "Version" SG_ 552 PSS_RL_AstSldBwdMvBtn "22.10.20";
BA_ "NetworkRequestHoldingTime" SG_ 552 PSS_RL_AstSldBwdMvBtn 5000;
BA_ "NetworkRequest" SG_ 552 PSS_RL_AstSldBwdMvBtn 0;
BA_ "UserSigValidity" SG_ 552 PSS_RL_AstSldBwdMvBtn 0;
BA_ "GenSigSendType" SG_ 552 PSS_RL_AstSldBwdMvBtn 4;
BA_ "Description" SG_ 552 PSS_RL_AstSldBwdMvBtn "PSS_RL_AstStSlideBackwardMoveButton";
BA_ "Version" SG_ 552 PSS_RL_AstHgtUpMvBtn "22.10.20";
BA_ "NetworkRequestHoldingTime" SG_ 552 PSS_RL_AstHgtUpMvBtn 5000;
BA_ "NetworkRequest" SG_ 552 PSS_RL_AstHgtUpMvBtn 0;
BA_ "UserSigValidity" SG_ 552 PSS_RL_AstHgtUpMvBtn 0;
BA_ "GenSigSendType" SG_ 552 PSS_RL_AstHgtUpMvBtn 4;
BA_ "Description" SG_ 552 PSS_RL_AstHgtUpMvBtn "PSS_RL_AstStHeightUpMoveButton";
BA_ "Version" SG_ 552 PSS_RL_AstHgtDnMvBtn "22.10.20";
BA_ "NetworkRequestHoldingTime" SG_ 552 PSS_RL_AstHgtDnMvBtn 5000;
BA_ "NetworkRequest" SG_ 552 PSS_RL_AstHgtDnMvBtn 0;
BA_ "UserSigValidity" SG_ 552 PSS_RL_AstHgtDnMvBtn 0;
BA_ "GenSigSendType" SG_ 552 PSS_RL_AstHgtDnMvBtn 4;
BA_ "Description" SG_ 552 PSS_RL_AstHgtDnMvBtn "PSS_RL_AstStHeightDownMoveButton";
BA_ "Version" SG_ 552 PSS_RL_AstHRestBwdMvBtn "22.10.20";
BA_ "NetworkRequestHoldingTime" SG_ 552 PSS_RL_AstHRestBwdMvBtn 5000;
BA_ "NetworkRequest" SG_ 552 PSS_RL_AstHRestBwdMvBtn 0;
BA_ "UserSigValidity" SG_ 552 PSS_RL_AstHRestBwdMvBtn 0;
BA_ "GenSigSendType" SG_ 552 PSS_RL_AstHRestBwdMvBtn 4;
BA_ "Description" SG_ 552 PSS_RL_AstHRestBwdMvBtn "PSS_RL_AstStHead Rest DownMoveButton";
BA_ "Version" SG_ 552 PSS_RL_AstFRestOpenMvBtn "22.10.20";
BA_ "NetworkRequestHoldingTime" SG_ 552 PSS_RL_AstFRestOpenMvBtn 5000;
BA_ "NetworkRequest" SG_ 552 PSS_RL_AstFRestOpenMvBtn 0;
BA_ "UserSigValidity" SG_ 552 PSS_RL_AstFRestOpenMvBtn 0;
BA_ "GenSigSendType" SG_ 552 PSS_RL_AstFRestOpenMvBtn 4;
BA_ "Description" SG_ 552 PSS_RL_AstFRestOpenMvBtn "PSS_RL_AstStFootrestOpenButton";
BA_ "Version" SG_ 552 PSS_RL_AstFRestCloseMvBtn "22.10.20";
BA_ "NetworkRequestHoldingTime" SG_ 552 PSS_RL_AstFRestCloseMvBtn 5000;
BA_ "NetworkRequest" SG_ 552 PSS_RL_AstFRestCloseMvBtn 0;
BA_ "UserSigValidity" SG_ 552 PSS_RL_AstFRestCloseMvBtn 0;
BA_ "GenSigSendType" SG_ 552 PSS_RL_AstFRestCloseMvBtn 4;
BA_ "Description" SG_ 552 PSS_RL_AstFRestCloseMvBtn "PSS_RL_AstStFootrestCloseButton";
BA_ "Version" SG_ 552 PSS_RL_AstHRestUpMvBtn "22.10.20";
BA_ "NetworkRequestHoldingTime" SG_ 552 PSS_RL_AstHRestUpMvBtn 5000;
BA_ "NetworkRequest" SG_ 552 PSS_RL_AstHRestUpMvBtn 0;
BA_ "UserSigValidity" SG_ 552 PSS_RL_AstHRestUpMvBtn 0;
BA_ "GenSigSendType" SG_ 552 PSS_RL_AstHRestUpMvBtn 4;
BA_ "Description" SG_ 552 PSS_RL_AstHRestUpMvBtn "PSS_RL_AstStHead Rest ForwardMoveButton";
BA_ "Version" SG_ 552 PSS_RL_AstHRestDnMvBtn "22.10.20";
BA_ "NetworkRequestHoldingTime" SG_ 552 PSS_RL_AstHRestDnMvBtn 5000;
BA_ "NetworkRequest" SG_ 552 PSS_RL_AstHRestDnMvBtn 0;
BA_ "UserSigValidity" SG_ 552 PSS_RL_AstHRestDnMvBtn 0;
BA_ "GenSigSendType" SG_ 552 PSS_RL_AstHRestDnMvBtn 4;
BA_ "Description" SG_ 552 PSS_RL_AstHRestDnMvBtn "PSS_RL_AstStHead Rest BackwardMoveButton";
BA_ "Version" SG_ 552 PSS_RL_AstRclFwdMvBtn "22.10.20";
BA_ "NetworkRequestHoldingTime" SG_ 552 PSS_RL_AstRclFwdMvBtn 5000;
BA_ "NetworkRequest" SG_ 552 PSS_RL_AstRclFwdMvBtn 0;
BA_ "UserSigValidity" SG_ 552 PSS_RL_AstRclFwdMvBtn 0;
BA_ "GenSigSendType" SG_ 552 PSS_RL_AstRclFwdMvBtn 4;
BA_ "Description" SG_ 552 PSS_RL_AstRclFwdMvBtn "PSS_RL_AstStReclinerForwardMoveButton";
BA_ "Version" SG_ 553 PSS_RL_LumbarUpSw "22.10.20";
BA_ "NetworkRequestHoldingTime" SG_ 553 PSS_RL_LumbarUpSw 5000;
BA_ "NetworkRequest" SG_ 553 PSS_RL_LumbarUpSw 0;
BA_ "UserSigValidity" SG_ 553 PSS_RL_LumbarUpSw 0;
BA_ "GenSigSendType" SG_ 553 PSS_RL_LumbarUpSw 4;
BA_ "Description" SG_ 553 PSS_RL_LumbarUpSw "PSS_RL_LumbarUpSwMoveButton";
BA_ "Version" SG_ 553 PSS_RL_BolsterDefSw "22.10.20";
BA_ "NetworkRequestHoldingTime" SG_ 553 PSS_RL_BolsterDefSw 5000;
BA_ "NetworkRequest" SG_ 553 PSS_RL_BolsterDefSw 0;
BA_ "UserSigValidity" SG_ 553 PSS_RL_BolsterDefSw 0;
BA_ "GenSigSendType" SG_ 553 PSS_RL_BolsterDefSw 4;
BA_ "Description" SG_ 553 PSS_RL_BolsterDefSw "PSS_RL_BolsterBwdMoveButton";
BA_ "Version" SG_ 553 PSS_RL_ActiveSw "22.10.20";
BA_ "NetworkRequestHoldingTime" SG_ 553 PSS_RL_ActiveSw 5000;
BA_ "NetworkRequest" SG_ 553 PSS_RL_ActiveSw 0;
BA_ "UserSigValidity" SG_ 553 PSS_RL_ActiveSw 0;
BA_ "GenSigSendType" SG_ 553 PSS_RL_ActiveSw 4;
BA_ "Description" SG_ 553 PSS_RL_ActiveSw "PSS_RL_ActiveSw";
BA_ "Version" SG_ 553 PSS_RL_LumbarMidSw "22.10.20";
BA_ "NetworkRequestHoldingTime" SG_ 553 PSS_RL_LumbarMidSw 5000;
BA_ "NetworkRequest" SG_ 553 PSS_RL_LumbarMidSw 0;
BA_ "UserSigValidity" SG_ 553 PSS_RL_LumbarMidSw 0;
BA_ "GenSigSendType" SG_ 553 PSS_RL_LumbarMidSw 4;
BA_ "Description" SG_ 553 PSS_RL_LumbarMidSw "PSS_RL_LumbarFwdSwMoveButton";
BA_ "Version" SG_ 553 PSS_RL_LumbarLowSw "22.10.20";
BA_ "NetworkRequestHoldingTime" SG_ 553 PSS_RL_LumbarLowSw 5000;
BA_ "NetworkRequest" SG_ 553 PSS_RL_LumbarLowSw 0;
BA_ "UserSigValidity" SG_ 553 PSS_RL_LumbarLowSw 0;
BA_ "GenSigSendType" SG_ 553 PSS_RL_LumbarLowSw 4;
BA_ "Description" SG_ 553 PSS_RL_LumbarLowSw "PSS_RL_LumbarDnSwMoveButton";
BA_ "Version" SG_ 553 PSS_RL_LumbarDefSw "22.10.20";
BA_ "NetworkRequestHoldingTime" SG_ 553 PSS_RL_LumbarDefSw 5000;
BA_ "NetworkRequest" SG_ 553 PSS_RL_LumbarDefSw 0;
BA_ "UserSigValidity" SG_ 553 PSS_RL_LumbarDefSw 0;
BA_ "GenSigSendType" SG_ 553 PSS_RL_LumbarDefSw 4;
BA_ "Description" SG_ 553 PSS_RL_LumbarDefSw "PSS_RL_LumbarBwdSwMoveButton";
BA_ "Version" SG_ 553 PSS_RL_BolsterInfSw "22.10.20";
BA_ "NetworkRequestHoldingTime" SG_ 553 PSS_RL_BolsterInfSw 5000;
BA_ "NetworkRequest" SG_ 553 PSS_RL_BolsterInfSw 0;
BA_ "UserSigValidity" SG_ 553 PSS_RL_BolsterInfSw 0;
BA_ "GenSigSendType" SG_ 553 PSS_RL_BolsterInfSw 4;
BA_ "Description" SG_ 553 PSS_RL_BolsterInfSw "PSS_RL_BolsterFwdMoveButton";
BA_ "Version" SG_ 2449771009 ODS_Crc1Val "18.11.08";
BA_ "UserSigValidity" SG_ 2449771009 ODS_Crc1Val 3;
BA_ "GenSigStartValue" SG_ 2449771009 ODS_Crc1Val 65535;
BA_ "Description" SG_ 2449771009 ODS_Crc1Val "The data area for CRC calculation is based on the data length (DLC) of the message DB.

The CRC shall be calculated over the entire data block (excluding the CRC bytes) including the user data, alive counter and Data ID

 

- CRC Polynomial (0x1021) , In";
BA_ "Version" SG_ 2449771009 ODS_AlvCnt1Val "18.11.08";
BA_ "UserSigValidity" SG_ 2449771009 ODS_AlvCnt1Val 3;
BA_ "Description" SG_ 2449771009 ODS_AlvCnt1Val "For the first transmission request for a data element the counter shall be initialized with 0 and shall be incremented by 1 for every subsequent send request. 

When the counter reaches the maximum value(0xFF), then it shall restart with 0 for the next s";
BA_ "Version" SG_ 2449771009 ODS_IdVal "17.12.02";
BA_ "UserSigValidity" SG_ 2449771009 ODS_IdVal 3;
BA_ "Description" SG_ 2449771009 ODS_IdVal "Information of Vehicle seat ID as defined by customer.



¡Ø Initial Value °ª(0x0) ¹«½Ã (Àü»ê ½Ã½ºÅÛ µî·Ï Â÷ ÀÓÀÇ·Î 0x0°ª µî·Ï)

: Initial(Start) Value : Current Value";
BA_ "Version" SG_ 2449771009 ODS_OccClassSta "17.12.02";
BA_ "UserSigValidity" SG_ 2449771009 ODS_OccClassSta 3;
BA_ "GenSigStartValue" SG_ 2449771009 ODS_OccClassSta 4;
BA_ "Description" SG_ 2449771009 ODS_OccClassSta "Signal Value Table : reference with ODS Communiction instruction";
BA_ "Version" SG_ 2449771009 ODS_DiagSta "17.12.02";
BA_ "UserSigValidity" SG_ 2449771009 ODS_DiagSta 3;
BA_ "Description" SG_ 2449771009 ODS_DiagSta "CR_WCS_Errstat signal describes PODS-G & BOSE system error that is diagnosed by itself. Each Type set Diagnostic Status explains 3 kinds of fault.

[PODS-G]

Bit 1 : If ODS Have some errors, ODS set the bit, sends the ALR Defect signal to ACU and notifie";
BA_ "Version" SG_ 2449771009 ODS_SBRClassSta "19.05.02";
BA_ "UserSigValidity" SG_ 2449771009 ODS_SBRClassSta 3;
BA_ "Description" SG_ 2449771009 ODS_SBRClassSta "Refer to Signal Value table";
BA_ "Version" SG_ 2395189505 DATC_Crc9Val "21.09.03";
BA_ "UserSigValidity" SG_ 2395189505 DATC_Crc9Val 3;
BA_ "GenSigStartValue" SG_ 2395189505 DATC_Crc9Val 65535;
BA_ "GenSigSendType" SG_ 2395189505 DATC_Crc9Val 4;
BA_ "Description" SG_ 2395189505 DATC_Crc9Val "The data area for CRC calculation is based on the data length (DLC) of the message DB.

The CRC shall be calculated over the entire data block (excluding the CRC bytes) including the user data, alive counter and Data ID



- CRC Polynomial (0x1021) , Ini";
BA_ "Version" SG_ 2395189505 DATC_AlvCnt9Val "21.09.03";
BA_ "UserSigValidity" SG_ 2395189505 DATC_AlvCnt9Val 3;
BA_ "GenSigSendType" SG_ 2395189505 DATC_AlvCnt9Val 4;
BA_ "Description" SG_ 2395189505 DATC_AlvCnt9Val "For the first transmission request for a data element the counter shall be initialized with 0 and shall be incremented by 1 for every subsequent send request. 

When the counter reaches the maximum value(0xFF), then it shall restart with 0 for the next s";
BA_ "Version" SG_ 2395189505 DATC_FragranceStrhSta "20.03.00";
BA_ "UserSigValidity" SG_ 2395189505 DATC_FragranceStrhSta 7;
BA_ "GenSigSendType" SG_ 2395189505 DATC_FragranceStrhSta 4;
BA_ "Description" SG_ 2395189505 DATC_FragranceStrhSta "This signal indicate frangrance strength state";
BA_ "Version" SG_ 2395189505 DATC_FragranceKindSta "20.03.00";
BA_ "UserSigValidity" SG_ 2395189505 DATC_FragranceKindSta 7;
BA_ "GenSigSendType" SG_ 2395189505 DATC_FragranceKindSta 4;
BA_ "Description" SG_ 2395189505 DATC_FragranceKindSta "This signal indicate fragrance kind state.";
BA_ "Version" SG_ 2395189505 DATC_AfterBlowOpSta "20.09.00";
BA_ "UserSigValidity" SG_ 2395189505 DATC_AfterBlowOpSta 7;
BA_ "GenSigSendType" SG_ 2395189505 DATC_AfterBlowOpSta 4;
BA_ "Description" SG_ 2395189505 DATC_AfterBlowOpSta "Operating Status of AfterBlow";
BA_ "Version" SG_ 2395189505 DATC_RrBlwDis "21.07.06";
BA_ "UserSigValidity" SG_ 2395189505 DATC_RrBlwDis 7;
BA_ "GenSigSendType" SG_ 2395189505 DATC_RrBlwDis 4;
BA_ "Version" SG_ 2395189505 DATC_RrClmtAutoOffUSMSta "20.12.04";
BA_ "UserSigValidity" SG_ 2395189505 DATC_RrClmtAutoOffUSMSta 7;
BA_ "GenSigSendType" SG_ 2395189505 DATC_RrClmtAutoOffUSMSta 4;
BA_ "Description" SG_ 2395189505 DATC_RrClmtAutoOffUSMSta "This signal indicate Rear Climate Auto Off USM State.";
BA_ "Version" SG_ 2395189505 DATC_KeyOffBlowOpReq "22.05.02";
BA_ "UserSigValidity" SG_ 2395189505 DATC_KeyOffBlowOpReq 7;
BA_ "GenSigSendType" SG_ 2395189505 DATC_KeyOffBlowOpReq 4;
BA_ "Description" SG_ 2395189505 DATC_KeyOffBlowOpReq "Operating Request of AfterBlow";
BA_ "Version" SG_ 2395189505 DATC_ArClnSysOSD "19.08.01";
BA_ "UserSigValidity" SG_ 2395189505 DATC_ArClnSysOSD 7;
BA_ "GenSigSendType" SG_ 2395189505 DATC_ArClnSysOSD 4;
BA_ "Description" SG_ 2395189505 DATC_ArClnSysOSD "This signal indicate the feature of OSD POP UP about Air Cleaning System.";
BA_ "Version" SG_ 2395189505 DATC_ArClnStepClr "19.02.03";
BA_ "UserSigValidity" SG_ 2395189505 DATC_ArClnStepClr 7;
BA_ "GenSigSendType" SG_ 2395189505 DATC_ArClnStepClr 4;
BA_ "Description" SG_ 2395189505 DATC_ArClnStepClr "This signal indicate the information about Color of AirCleaning Symbol displaying in the AVN";
BA_ "Version" SG_ 2395189505 DATC_ArClnSmblTyp "18.12.08";
BA_ "UserSigValidity" SG_ 2395189505 DATC_ArClnSmblTyp 7;
BA_ "GenSigSendType" SG_ 2395189505 DATC_ArClnSmblTyp 4;
BA_ "Description" SG_ 2395189505 DATC_ArClnSmblTyp "This signal indicate the feature of Air Cleaning Symbol displaying in AVN";
BA_ "Version" SG_ 2395189505 DATC_AfterBlowUSMSta "19.10.06";
BA_ "UserSigValidity" SG_ 2395189505 DATC_AfterBlowUSMSta 7;
BA_ "GenSigSendType" SG_ 2395189505 DATC_AfterBlowUSMSta 4;
BA_ "Description" SG_ 2395189505 DATC_AfterBlowUSMSta "This signal indicate activation status of USM setting menu about After Blow.";
BA_ "Version" SG_ 2395189505 DATC_SchdldVntUSMSta "19.08.08";
BA_ "UserSigValidity" SG_ 2395189505 DATC_SchdldVntUSMSta 7;
BA_ "GenSigSendType" SG_ 2395189505 DATC_SchdldVntUSMSta 4;
BA_ "Description" SG_ 2395189505 DATC_SchdldVntUSMSta "This signal indicate activation status of USM setting menu about Scheduled Ventilation";
BA_ "Version" SG_ 2395189505 DATC_SchdldVntHrSta "19.08.08";
BA_ "UserSigValidity" SG_ 2395189505 DATC_SchdldVntHrSta 7;
BA_ "GenSigSendType" SG_ 2395189505 DATC_SchdldVntHrSta 4;
BA_ "Description" SG_ 2395189505 DATC_SchdldVntHrSta "This signal indicates the value corresponding to 'hour' among the set time values of the scheduled ventilation USM";
BA_ "Version" SG_ 2395189505 DATC_SchdldVntMinSta "19.08.08";
BA_ "UserSigValidity" SG_ 2395189505 DATC_SchdldVntMinSta 7;
BA_ "GenSigSendType" SG_ 2395189505 DATC_SchdldVntMinSta 4;
BA_ "Description" SG_ 2395189505 DATC_SchdldVntMinSta "This signal indicates the value corresponding to 'minutes' among the set time values of the scheduled ventilation USM.";
BA_ "Version" SG_ 527 ATS_DrvStRseFwdBtn "19.09.02";
BA_ "NetworkRequestHoldingTime" SG_ 527 ATS_DrvStRseFwdBtn 5000;
BA_ "NetworkRequest" SG_ 527 ATS_DrvStRseFwdBtn 0;
BA_ "UserSigValidity" SG_ 527 ATS_DrvStRseFwdBtn 3;
BA_ "GenSigSendType" SG_ 527 ATS_DrvStRseFwdBtn 4;
BA_ "Description" SG_ 527 ATS_DrvStRseFwdBtn "¿îÀü¼® ¸ð´ÏÅÍ °¢µµ Á¶Àý Àü¹æ ÀÌµ¿";
BA_ "Version" SG_ 527 ATS_DrvStRseBwdBtn "19.09.02";
BA_ "NetworkRequestHoldingTime" SG_ 527 ATS_DrvStRseBwdBtn 5000;
BA_ "NetworkRequest" SG_ 527 ATS_DrvStRseBwdBtn 0;
BA_ "UserSigValidity" SG_ 527 ATS_DrvStRseBwdBtn 3;
BA_ "GenSigSendType" SG_ 527 ATS_DrvStRseBwdBtn 4;
BA_ "Description" SG_ 527 ATS_DrvStRseBwdBtn "¿îÀü¼® ¸ð´ÏÅÍ °¢µµ Á¶Àý ÈÄ¹æ ÀÌµ¿";
BA_ "Version" SG_ 527 ATS_RRRestModBtn "19.09.02";
BA_ "NetworkRequestHoldingTime" SG_ 527 ATS_RRRestModBtn 5000;
BA_ "NetworkRequest" SG_ 527 ATS_RRRestModBtn 0;
BA_ "UserSigValidity" SG_ 527 ATS_RRRestModBtn 3;
BA_ "GenSigSendType" SG_ 527 ATS_RRRestModBtn 4;
BA_ "Description" SG_ 527 ATS_RRRestModBtn "ÈÄ¼® RH REST ¸ðµå ÀÛµ¿";
BA_ "Version" SG_ 527 ATS_RRResetModBtn "19.09.02";
BA_ "NetworkRequestHoldingTime" SG_ 527 ATS_RRResetModBtn 5000;
BA_ "NetworkRequest" SG_ 527 ATS_RRResetModBtn 0;
BA_ "UserSigValidity" SG_ 527 ATS_RRResetModBtn 3;
BA_ "GenSigSendType" SG_ 527 ATS_RRResetModBtn 4;
BA_ "Description" SG_ 527 ATS_RRResetModBtn "ÈÄ¼® RH RETURN ¸ðµå ÀÛµ¿";
BA_ "Version" SG_ 527 ATS_RRAvWtcModBtn "19.09.02";
BA_ "NetworkRequestHoldingTime" SG_ 527 ATS_RRAvWtcModBtn 5000;
BA_ "NetworkRequest" SG_ 527 ATS_RRAvWtcModBtn 0;
BA_ "UserSigValidity" SG_ 527 ATS_RRAvWtcModBtn 3;
BA_ "GenSigSendType" SG_ 527 ATS_RRAvWtcModBtn 4;
BA_ "Description" SG_ 527 ATS_RRAvWtcModBtn "ÈÄ¼® RH AVN ¸ðµå ÀÛµ¿";
BA_ "Version" SG_ 527 ATS_RRReadingModBtn "19.09.02";
BA_ "NetworkRequestHoldingTime" SG_ 527 ATS_RRReadingModBtn 5000;
BA_ "NetworkRequest" SG_ 527 ATS_RRReadingModBtn 0;
BA_ "UserSigValidity" SG_ 527 ATS_RRReadingModBtn 3;
BA_ "GenSigSendType" SG_ 527 ATS_RRReadingModBtn 4;
BA_ "Description" SG_ 527 ATS_RRReadingModBtn "ÈÄ¼® RH READING ¸ðµå ÀÛµ¿";
BA_ "Version" SG_ 527 ATS_RLRestModBtn "19.09.02";
BA_ "NetworkRequestHoldingTime" SG_ 527 ATS_RLRestModBtn 5000;
BA_ "NetworkRequest" SG_ 527 ATS_RLRestModBtn 0;
BA_ "UserSigValidity" SG_ 527 ATS_RLRestModBtn 3;
BA_ "GenSigSendType" SG_ 527 ATS_RLRestModBtn 4;
BA_ "Description" SG_ 527 ATS_RLRestModBtn "ÈÄ¼® LH REST ¸ðµå ÀÛµ¿";
BA_ "Version" SG_ 527 ATS_RLResetModBtn "19.09.02";
BA_ "NetworkRequestHoldingTime" SG_ 527 ATS_RLResetModBtn 5000;
BA_ "NetworkRequest" SG_ 527 ATS_RLResetModBtn 0;
BA_ "UserSigValidity" SG_ 527 ATS_RLResetModBtn 3;
BA_ "GenSigSendType" SG_ 527 ATS_RLResetModBtn 4;
BA_ "Description" SG_ 527 ATS_RLResetModBtn "ÈÄ¼® LH RETURN ¸ðµå ÀÛµ¿";
BA_ "Version" SG_ 1616 MKBD_IllumiState "20.04.02";
BA_ "UserSigValidity" SG_ 1616 MKBD_IllumiState 1;
BA_ "GenSigStartValue" SG_ 1616 MKBD_IllumiState 3;
BA_ "GenSigSendType" SG_ 1616 MKBD_IllumiState 4;
BA_ "Version" SG_ 1616 MKBD_SeatKeySet "20.06.07";
BA_ "UserSigValidity" SG_ 1616 MKBD_SeatKeySet 3;
BA_ "GenSigStartValue" SG_ 1616 MKBD_SeatKeySet 3;
BA_ "GenSigSendType" SG_ 1616 MKBD_SeatKeySet 4;
BA_ "Description" SG_ 1616 MKBD_SeatKeySet "The signal for transmitting Seat Key inputs from MKBD to Seat ECU

Release : 0x0 / Press : 0x1";
BA_ "Version" SG_ 543 ATS_AstStSldFwdBtn "19.09.02";
BA_ "NetworkRequestHoldingTime" SG_ 543 ATS_AstStSldFwdBtn 5000;
BA_ "NetworkRequest" SG_ 543 ATS_AstStSldFwdBtn 0;
BA_ "UserSigValidity" SG_ 543 ATS_AstStSldFwdBtn 3;
BA_ "GenSigSendType" SG_ 543 ATS_AstStSldFwdBtn 4;
BA_ "Description" SG_ 543 ATS_AstStSldFwdBtn "µ¿½Â¼® ½½¶óÀÌµù Àü¹æ ÀÌµ¿ (¿öÅ©ÀÎ ÀÛµ¿)";
BA_ "Version" SG_ 543 ATS_AstStSldBwdBtn "19.09.02";
BA_ "NetworkRequestHoldingTime" SG_ 543 ATS_AstStSldBwdBtn 5000;
BA_ "NetworkRequest" SG_ 543 ATS_AstStSldBwdBtn 0;
BA_ "UserSigValidity" SG_ 543 ATS_AstStSldBwdBtn 3;
BA_ "GenSigSendType" SG_ 543 ATS_AstStSldBwdBtn 4;
BA_ "Description" SG_ 543 ATS_AstStSldBwdBtn "µ¿½Â¼® ½½¶óÀÌµù ÈÄ¹æ ÀÌµ¿ (¿öÅ©ÀÎ ÀÛµ¿)";
BA_ "Version" SG_ 543 ATS_AstStRclFwdBtn "19.09.02";
BA_ "NetworkRequestHoldingTime" SG_ 543 ATS_AstStRclFwdBtn 5000;
BA_ "NetworkRequest" SG_ 543 ATS_AstStRclFwdBtn 0;
BA_ "UserSigValidity" SG_ 543 ATS_AstStRclFwdBtn 3;
BA_ "GenSigSendType" SG_ 543 ATS_AstStRclFwdBtn 4;
BA_ "Description" SG_ 543 ATS_AstStRclFwdBtn "µ¿½Â¼® ¸®Å¬¶óÀÌ´× Àü¹æ ÀÌµ¿ (¿öÅ©ÀÎ ÀÛµ¿)";
BA_ "Version" SG_ 543 ATS_AstStRclBwdBtn "19.09.02";
BA_ "NetworkRequestHoldingTime" SG_ 543 ATS_AstStRclBwdBtn 5000;
BA_ "NetworkRequest" SG_ 543 ATS_AstStRclBwdBtn 0;
BA_ "UserSigValidity" SG_ 543 ATS_AstStRclBwdBtn 3;
BA_ "GenSigSendType" SG_ 543 ATS_AstStRclBwdBtn 4;
BA_ "Description" SG_ 543 ATS_AstStRclBwdBtn "µ¿½Â¼® ¸®Å¬¶óÀÌ´× ÈÄ¹æ ÀÌµ¿ (¿öÅ©ÀÎ ÀÛµ¿)";
BA_ "Version" SG_ 543 ATS_AstStHgtUpBtn "19.09.02";
BA_ "NetworkRequestHoldingTime" SG_ 543 ATS_AstStHgtUpBtn 5000;
BA_ "NetworkRequest" SG_ 543 ATS_AstStHgtUpBtn 0;
BA_ "UserSigValidity" SG_ 543 ATS_AstStHgtUpBtn 3;
BA_ "GenSigSendType" SG_ 543 ATS_AstStHgtUpBtn 4;
BA_ "Description" SG_ 543 ATS_AstStHgtUpBtn "µ¿½Â¼® ÇÏÀÌÆ® ¾÷ ÀÌµ¿ (¿öÅ©ÀÎ ÀÛµ¿)";
BA_ "Version" SG_ 543 ATS_AstStHgtDnBtn "19.09.02";
BA_ "NetworkRequestHoldingTime" SG_ 543 ATS_AstStHgtDnBtn 5000;
BA_ "NetworkRequest" SG_ 543 ATS_AstStHgtDnBtn 0;
BA_ "UserSigValidity" SG_ 543 ATS_AstStHgtDnBtn 3;
BA_ "GenSigSendType" SG_ 543 ATS_AstStHgtDnBtn 4;
BA_ "Description" SG_ 543 ATS_AstStHgtDnBtn "µ¿½Â¼® ÇÏÀÌÆ® ´Ù¿î ÀÌµ¿ (¿öÅ©ÀÎ ÀÛµ¿)";
BA_ "Version" SG_ 543 ATS_AstStHRestUpBtn "19.09.02";
BA_ "NetworkRequestHoldingTime" SG_ 543 ATS_AstStHRestUpBtn 5000;
BA_ "NetworkRequest" SG_ 543 ATS_AstStHRestUpBtn 0;
BA_ "UserSigValidity" SG_ 543 ATS_AstStHRestUpBtn 3;
BA_ "GenSigSendType" SG_ 543 ATS_AstStHRestUpBtn 4;
BA_ "Description" SG_ 543 ATS_AstStHRestUpBtn "µ¿½Â¼® Çìµå·¹½ºÆ® ¾÷ ÀÌµ¿ (¿öÅ©ÀÎ ÀÛµ¿)";
BA_ "Version" SG_ 543 ATS_AstStHRestDnBtn "19.09.02";
BA_ "NetworkRequestHoldingTime" SG_ 543 ATS_AstStHRestDnBtn 5000;
BA_ "NetworkRequest" SG_ 543 ATS_AstStHRestDnBtn 0;
BA_ "UserSigValidity" SG_ 543 ATS_AstStHRestDnBtn 3;
BA_ "GenSigSendType" SG_ 543 ATS_AstStHRestDnBtn 4;
BA_ "Description" SG_ 543 ATS_AstStHRestDnBtn "µ¿½Â¼® Çìµå·¹½ºÆ® ´Ù¿î ÀÌµ¿ (¿öÅ©ÀÎ ÀÛµ¿)";
BA_ "Version" SG_ 543 ATS_AstStHRestFwdBtn "19.09.02";
BA_ "NetworkRequestHoldingTime" SG_ 543 ATS_AstStHRestFwdBtn 5000;
BA_ "NetworkRequest" SG_ 543 ATS_AstStHRestFwdBtn 0;
BA_ "UserSigValidity" SG_ 543 ATS_AstStHRestFwdBtn 3;
BA_ "GenSigSendType" SG_ 543 ATS_AstStHRestFwdBtn 4;
BA_ "Description" SG_ 543 ATS_AstStHRestFwdBtn "µ¿½Â¼® Çìµå·¹½ºÆ® Àü¹æ ÀÌµ¿ (¿öÅ©ÀÎ ÀÛµ¿)";
BA_ "Version" SG_ 543 ATS_AstStHRestBwdBtn "19.09.02";
BA_ "NetworkRequestHoldingTime" SG_ 543 ATS_AstStHRestBwdBtn 5000;
BA_ "NetworkRequest" SG_ 543 ATS_AstStHRestBwdBtn 0;
BA_ "UserSigValidity" SG_ 543 ATS_AstStHRestBwdBtn 3;
BA_ "GenSigSendType" SG_ 543 ATS_AstStHRestBwdBtn 4;
BA_ "Description" SG_ 543 ATS_AstStHRestBwdBtn "µ¿½Â¼® Çìµå·¹½ºÆ® ÈÄ¹æ ÀÌµ¿ (¿öÅ©ÀÎ ÀÛµ¿)";
BA_ "Version" SG_ 543 ATS_AstStHRestFldBtn "19.09.02";
BA_ "NetworkRequestHoldingTime" SG_ 543 ATS_AstStHRestFldBtn 5000;
BA_ "NetworkRequest" SG_ 543 ATS_AstStHRestFldBtn 0;
BA_ "UserSigValidity" SG_ 543 ATS_AstStHRestFldBtn 3;
BA_ "GenSigSendType" SG_ 543 ATS_AstStHRestFldBtn 4;
BA_ "Description" SG_ 543 ATS_AstStHRestFldBtn "µ¿½Â¼® Çìµå·¹½ºÆ® Æúµù ÀÌµ¿ (¿öÅ©ÀÎ ÀÛµ¿)";
BA_ "Version" SG_ 543 ATS_AstStHRestUnFldBtn "19.09.02";
BA_ "NetworkRequestHoldingTime" SG_ 543 ATS_AstStHRestUnFldBtn 5000;
BA_ "NetworkRequest" SG_ 543 ATS_AstStHRestUnFldBtn 0;
BA_ "UserSigValidity" SG_ 543 ATS_AstStHRestUnFldBtn 3;
BA_ "GenSigSendType" SG_ 543 ATS_AstStHRestUnFldBtn 4;
BA_ "Description" SG_ 543 ATS_AstStHRestUnFldBtn "µ¿½Â¼® Çìµå·¹½ºÆ® ¾ðÆúµù ÀÌµ¿ (¿öÅ©ÀÎ ÀÛµ¿)";
BA_ "Version" SG_ 543 ATS_AstStRseFwdBtn "19.09.02";
BA_ "NetworkRequestHoldingTime" SG_ 543 ATS_AstStRseFwdBtn 5000;
BA_ "NetworkRequest" SG_ 543 ATS_AstStRseFwdBtn 0;
BA_ "UserSigValidity" SG_ 543 ATS_AstStRseFwdBtn 3;
BA_ "GenSigSendType" SG_ 543 ATS_AstStRseFwdBtn 4;
BA_ "Description" SG_ 543 ATS_AstStRseFwdBtn "µ¿½Â¼® ¸ð´ÏÅÍ °¢µµ Á¶Àý Àü¹æ ÀÌµ¿";
BA_ "Version" SG_ 543 ATS_AstStRseBwdBtn "19.09.02";
BA_ "NetworkRequestHoldingTime" SG_ 543 ATS_AstStRseBwdBtn 5000;
BA_ "NetworkRequest" SG_ 543 ATS_AstStRseBwdBtn 0;
BA_ "UserSigValidity" SG_ 543 ATS_AstStRseBwdBtn 3;
BA_ "GenSigSendType" SG_ 543 ATS_AstStRseBwdBtn 4;
BA_ "Description" SG_ 543 ATS_AstStRseBwdBtn "µ¿½Â¼® ¸ð´ÏÅÍ °¢µµ Á¶Àý ÈÄ¹æ ÀÌµ¿";
BA_ "Version" SG_ 543 ATS_AstStFRestFldBtn "19.09.02";
BA_ "NetworkRequestHoldingTime" SG_ 543 ATS_AstStFRestFldBtn 5000;
BA_ "NetworkRequest" SG_ 543 ATS_AstStFRestFldBtn 0;
BA_ "UserSigValidity" SG_ 543 ATS_AstStFRestFldBtn 3;
BA_ "GenSigSendType" SG_ 543 ATS_AstStFRestFldBtn 4;
BA_ "Description" SG_ 543 ATS_AstStFRestFldBtn "µ¿½Â¼® Ç²·¹½ºÆ® Æúµù ÀÌµ¿ (¿öÅ©ÀÎ ÀÛµ¿)";
BA_ "Version" SG_ 543 ATS_AstStFRestUnFldBtn "19.09.02";
BA_ "NetworkRequestHoldingTime" SG_ 543 ATS_AstStFRestUnFldBtn 5000;
BA_ "NetworkRequest" SG_ 543 ATS_AstStFRestUnFldBtn 0;
BA_ "UserSigValidity" SG_ 543 ATS_AstStFRestUnFldBtn 3;
BA_ "GenSigSendType" SG_ 543 ATS_AstStFRestUnFldBtn 4;
BA_ "Description" SG_ 543 ATS_AstStFRestUnFldBtn "µ¿½Â¼® Ç²·¹½ºÆ® ¾ðÆúµù ÀÌµ¿ (¿öÅ©ÀÎ ÀÛµ¿)";
BA_ "Version" SG_ 543 ATS_AstTltUpBtn "19.12.00";
BA_ "NetworkRequestHoldingTime" SG_ 543 ATS_AstTltUpBtn 5000;
BA_ "NetworkRequest" SG_ 543 ATS_AstTltUpBtn 0;
BA_ "UserSigValidity" SG_ 543 ATS_AstTltUpBtn 3;
BA_ "GenSigSendType" SG_ 543 ATS_AstTltUpBtn 4;
BA_ "Description" SG_ 543 ATS_AstTltUpBtn "µ¿½Â¼® Æ¿Æ® UP ÀÌµ¿ (¿öÅ©ÀÎ ÀÛµ¿)";
BA_ "Version" SG_ 543 ATS_AstTltDnBtn "19.12.00";
BA_ "NetworkRequestHoldingTime" SG_ 543 ATS_AstTltDnBtn 5000;
BA_ "NetworkRequest" SG_ 543 ATS_AstTltDnBtn 0;
BA_ "UserSigValidity" SG_ 543 ATS_AstTltDnBtn 3;
BA_ "GenSigSendType" SG_ 543 ATS_AstTltDnBtn 4;
BA_ "Description" SG_ 543 ATS_AstTltDnBtn "µ¿½Â¼® Æ¿Æ® DOWN ÀÌµ¿ (¿öÅ©ÀÎ ÀÛµ¿)";
BA_REL_ "GenSigTimeoutTime" BU_SG_REL_ CGW_CCU SG_ 1518 APSS_GST_Byte0 0;
BA_REL_ "GenSigTimeoutTime" BU_SG_REL_ CGW_CCU SG_ 1518 APSS_GST_Byte2 0;
BA_REL_ "GenSigTimeoutTime" BU_SG_REL_ CGW_CCU SG_ 1518 APSS_GST_Byte3 0;
BA_REL_ "GenSigTimeoutTime" BU_SG_REL_ CGW_CCU SG_ 1518 APSS_GST_Byte4 0;
BA_REL_ "GenSigTimeoutTime" BU_SG_REL_ CGW_CCU SG_ 1518 APSS_GST_Byte5 0;
BA_REL_ "GenSigTimeoutTime" BU_SG_REL_ CGW_CCU SG_ 1518 APSS_GST_Byte6 0;
BA_REL_ "GenSigTimeoutTime" BU_SG_REL_ CGW_CCU SG_ 1518 APSS_GST_Byte7 0;
BA_REL_ "GenSigTimeoutTime" BU_SG_REL_ CGW_CCU SG_ 1518 APSS_GST_Byte1 0;
BA_REL_ "GenSigTimeoutTime" BU_SG_REL_ RCM SG_ 1426 GST_RCM_Byte0 0;
BA_REL_ "GenSigTimeoutTime" BU_SG_REL_ RCM SG_ 1426 GST_RCM_Byte2 0;
BA_REL_ "GenSigTimeoutTime" BU_SG_REL_ RCM SG_ 1426 GST_RCM_Byte3 0;
BA_REL_ "GenSigTimeoutTime" BU_SG_REL_ RCM SG_ 1426 GST_RCM_Byte4 0;
BA_REL_ "GenSigTimeoutTime" BU_SG_REL_ RCM SG_ 1426 GST_RCM_Byte5 0;
BA_REL_ "GenSigTimeoutTime" BU_SG_REL_ RCM SG_ 1426 GST_RCM_Byte6 0;
BA_REL_ "GenSigTimeoutTime" BU_SG_REL_ RCM SG_ 1426 GST_RCM_Byte7 0;
BA_REL_ "GenSigTimeoutTime" BU_SG_REL_ RCM SG_ 1426 GST_RCM_Byte1 0;
BA_REL_ "GenSigTimeoutTime" BU_SG_REL_ CGW_CCU SG_ 479 ALBCU_ActiveDis 1500;
BA_REL_ "GenSigTimeoutTime" BU_SG_REL_ CGW_CCU SG_ 479 ALBCU_DrvModUSMSta 1500;
BA_REL_ "GenSigTimeoutTime" BU_SG_REL_ CGW_CCU SG_ 479 ALBCU_ActiveStrSta 1500;
BA_REL_ "GenSigTimeoutTime" BU_SG_REL_ CGW_CCU SG_ 479 ALBCU_ActiveTimeSta 1500;
BA_REL_ "GenSigTimeoutTime" BU_SG_REL_ CGW_CCU SG_ 479 ALBCU_CellOpt 1500;
BA_REL_ "GenSigTimeoutTime" BU_SG_REL_ CGW_CCU SG_ 479 ALBCU_BodySpprtSta 1500;
BA_REL_ "GenSigTimeoutTime" BU_SG_REL_ CGW_CCU SG_ 479 ALBCU_MoodTrpyRValueSet 1500;
BA_REL_ "GenSigTimeoutTime" BU_SG_REL_ CGW_CCU SG_ 479 ALBCU_MoodTrpyCareSta 1500;
BA_REL_ "GenSigTimeoutTime" BU_SG_REL_ CGW_CCU SG_ 479 ALBCU_MoodTrpyComfSta 1500;
BA_REL_ "GenSigTimeoutTime" BU_SG_REL_ CGW_CCU SG_ 479 ALBCU_CushLeftPSnsrVtg 1500;
BA_REL_ "GenSigTimeoutTime" BU_SG_REL_ CGW_CCU SG_ 479 ALBCU_CushRightPSnsrVtg 1500;
BA_REL_ "GenSigTimeoutTime" BU_SG_REL_ CGW_CCU SG_ 1434 RCM_GST_Byte0 0;
BA_REL_ "GenSigTimeoutTime" BU_SG_REL_ CGW_CCU SG_ 1434 RCM_GST_Byte2 0;
BA_REL_ "GenSigTimeoutTime" BU_SG_REL_ CGW_CCU SG_ 1434 RCM_GST_Byte3 0;
BA_REL_ "GenSigTimeoutTime" BU_SG_REL_ CGW_CCU SG_ 1434 RCM_GST_Byte4 0;
BA_REL_ "GenSigTimeoutTime" BU_SG_REL_ CGW_CCU SG_ 1434 RCM_GST_Byte5 0;
BA_REL_ "GenSigTimeoutTime" BU_SG_REL_ CGW_CCU SG_ 1434 RCM_GST_Byte6 0;
BA_REL_ "GenSigTimeoutTime" BU_SG_REL_ CGW_CCU SG_ 1434 RCM_GST_Byte7 0;
BA_REL_ "GenSigTimeoutTime" BU_SG_REL_ CGW_CCU SG_ 1434 RCM_GST_Byte1 0;
BA_REL_ "GenSigTimeoutTime" BU_SG_REL_ EMCU SG_ 1414 GST_EMCU_Byte0 0;
BA_REL_ "GenSigTimeoutTime" BU_SG_REL_ EMCU SG_ 1414 GST_EMCU_Byte2 0;
BA_REL_ "GenSigTimeoutTime" BU_SG_REL_ EMCU SG_ 1414 GST_EMCU_Byte3 0;
BA_REL_ "GenSigTimeoutTime" BU_SG_REL_ EMCU SG_ 1414 GST_EMCU_Byte4 0;
BA_REL_ "GenSigTimeoutTime" BU_SG_REL_ EMCU SG_ 1414 GST_EMCU_Byte5 0;
BA_REL_ "GenSigTimeoutTime" BU_SG_REL_ EMCU SG_ 1414 GST_EMCU_Byte6 0;
BA_REL_ "GenSigTimeoutTime" BU_SG_REL_ EMCU SG_ 1414 GST_EMCU_Byte7 0;
BA_REL_ "GenSigTimeoutTime" BU_SG_REL_ EMCU SG_ 1414 GST_EMCU_Byte1 0;
BA_REL_ "GenSigTimeoutTime" BU_SG_REL_ SGU SG_ 1412 GST_SGU_Byte0 0;
BA_REL_ "GenSigTimeoutTime" BU_SG_REL_ SGU SG_ 1412 GST_SGU_Byte2 0;
BA_REL_ "GenSigTimeoutTime" BU_SG_REL_ SGU SG_ 1412 GST_SGU_Byte3 0;
BA_REL_ "GenSigTimeoutTime" BU_SG_REL_ SGU SG_ 1412 GST_SGU_Byte4 0;
BA_REL_ "GenSigTimeoutTime" BU_SG_REL_ SGU SG_ 1412 GST_SGU_Byte5 0;
BA_REL_ "GenSigTimeoutTime" BU_SG_REL_ SGU SG_ 1412 GST_SGU_Byte6 0;
BA_REL_ "GenSigTimeoutTime" BU_SG_REL_ SGU SG_ 1412 GST_SGU_Byte7 0;
BA_REL_ "GenSigTimeoutTime" BU_SG_REL_ SGU SG_ 1412 GST_SGU_Byte1 0;
BA_REL_ "GenSigTimeoutTime" BU_SG_REL_ CGW_CCU SG_ 1422 EMCU_GST_Byte0 0;
BA_REL_ "GenSigTimeoutTime" BU_SG_REL_ CGW_CCU SG_ 1422 EMCU_GST_Byte2 0;
BA_REL_ "GenSigTimeoutTime" BU_SG_REL_ CGW_CCU SG_ 1422 EMCU_GST_Byte3 0;
BA_REL_ "GenSigTimeoutTime" BU_SG_REL_ CGW_CCU SG_ 1422 EMCU_GST_Byte4 0;
BA_REL_ "GenSigTimeoutTime" BU_SG_REL_ CGW_CCU SG_ 1422 EMCU_GST_Byte5 0;
BA_REL_ "GenSigTimeoutTime" BU_SG_REL_ CGW_CCU SG_ 1422 EMCU_GST_Byte6 0;
BA_REL_ "GenSigTimeoutTime" BU_SG_REL_ CGW_CCU SG_ 1422 EMCU_GST_Byte7 0;
BA_REL_ "GenSigTimeoutTime" BU_SG_REL_ CGW_CCU SG_ 1422 EMCU_GST_Byte1 0;
BA_REL_ "GenSigTimeoutTime" BU_SG_REL_ CGW_CCU SG_ 1420 SGU_GST_Byte0 0;
BA_REL_ "GenSigTimeoutTime" BU_SG_REL_ CGW_CCU SG_ 1420 SGU_GST_Byte2 0;
BA_REL_ "GenSigTimeoutTime" BU_SG_REL_ CGW_CCU SG_ 1420 SGU_GST_Byte3 0;
BA_REL_ "GenSigTimeoutTime" BU_SG_REL_ CGW_CCU SG_ 1420 SGU_GST_Byte4 0;
BA_REL_ "GenSigTimeoutTime" BU_SG_REL_ CGW_CCU SG_ 1420 SGU_GST_Byte5 0;
BA_REL_ "GenSigTimeoutTime" BU_SG_REL_ CGW_CCU SG_ 1420 SGU_GST_Byte6 0;
BA_REL_ "GenSigTimeoutTime" BU_SG_REL_ CGW_CCU SG_ 1420 SGU_GST_Byte7 0;
BA_REL_ "GenSigTimeoutTime" BU_SG_REL_ CGW_CCU SG_ 1420 SGU_GST_Byte1 0;
BA_REL_ "GenSigTimeoutTime" BU_SG_REL_ RCS SG_ 2382595329 DMIC_OffRdModActvSta 1500;
BA_REL_ "GenSigTimeoutTime" BU_SG_REL_ EMCU SG_ 2382595329 ESC_LongGrdntPerc 1500;
BA_REL_ "GenSigTimeoutTime" BU_SG_REL_ EMCU SG_ 2382595329 ESC_LatGrdntPerc 1500;
BA_REL_ "GenSigTimeoutTime" BU_SG_REL_ GW_DLBCU SG_ 1456 GST_RRSAU_RRLBCU_Byte0 0;
BA_REL_ "GenSigTimeoutTime" BU_SG_REL_ GW_DLBCU SG_ 1456 GST_RRSAU_RRLBCU_Byte2 0;
BA_REL_ "GenSigTimeoutTime" BU_SG_REL_ GW_DLBCU SG_ 1456 GST_RRSAU_RRLBCU_Byte3 0;
BA_REL_ "GenSigTimeoutTime" BU_SG_REL_ GW_DLBCU SG_ 1456 GST_RRSAU_RRLBCU_Byte4 0;
BA_REL_ "GenSigTimeoutTime" BU_SG_REL_ GW_DLBCU SG_ 1456 GST_RRSAU_RRLBCU_Byte5 0;
BA_REL_ "GenSigTimeoutTime" BU_SG_REL_ GW_DLBCU SG_ 1456 GST_RRSAU_RRLBCU_Byte6 0;
BA_REL_ "GenSigTimeoutTime" BU_SG_REL_ GW_DLBCU SG_ 1456 GST_RRSAU_RRLBCU_Byte7 0;
BA_REL_ "GenSigTimeoutTime" BU_SG_REL_ GW_DLBCU SG_ 1456 GST_RRSAU_RRLBCU_Byte1 0;
BA_REL_ "GenSigTimeoutTime" BU_SG_REL_ GW_DLBCU SG_ 1457 GST_RLSAU_RLLBCU_Byte0 0;
BA_REL_ "GenSigTimeoutTime" BU_SG_REL_ GW_DLBCU SG_ 1457 GST_RLSAU_RLLBCU_Byte2 0;
BA_REL_ "GenSigTimeoutTime" BU_SG_REL_ GW_DLBCU SG_ 1457 GST_RLSAU_RLLBCU_Byte3 0;
BA_REL_ "GenSigTimeoutTime" BU_SG_REL_ GW_DLBCU SG_ 1457 GST_RLSAU_RLLBCU_Byte4 0;
BA_REL_ "GenSigTimeoutTime" BU_SG_REL_ GW_DLBCU SG_ 1457 GST_RLSAU_RLLBCU_Byte5 0;
BA_REL_ "GenSigTimeoutTime" BU_SG_REL_ GW_DLBCU SG_ 1457 GST_RLSAU_RLLBCU_Byte6 0;
BA_REL_ "GenSigTimeoutTime" BU_SG_REL_ GW_DLBCU SG_ 1457 GST_RLSAU_RLLBCU_Byte7 0;
BA_REL_ "GenSigTimeoutTime" BU_SG_REL_ GW_DLBCU SG_ 1457 GST_RLSAU_RLLBCU_Byte1 0;
BA_REL_ "GenSigTimeoutTime" BU_SG_REL_ ATS SG_ 1458 GST_ATS_Byte0 0;
BA_REL_ "GenSigTimeoutTime" BU_SG_REL_ ATS SG_ 1458 GST_ATS_Byte2 0;
BA_REL_ "GenSigTimeoutTime" BU_SG_REL_ ATS SG_ 1458 GST_ATS_Byte3 0;
BA_REL_ "GenSigTimeoutTime" BU_SG_REL_ ATS SG_ 1458 GST_ATS_Byte4 0;
BA_REL_ "GenSigTimeoutTime" BU_SG_REL_ ATS SG_ 1458 GST_ATS_Byte5 0;
BA_REL_ "GenSigTimeoutTime" BU_SG_REL_ ATS SG_ 1458 GST_ATS_Byte6 0;
BA_REL_ "GenSigTimeoutTime" BU_SG_REL_ ATS SG_ 1458 GST_ATS_Byte7 0;
BA_REL_ "GenSigTimeoutTime" BU_SG_REL_ ATS SG_ 1458 GST_ATS_Byte1 0;
BA_REL_ "GenSigTimeoutTime" BU_SG_REL_ ATS SG_ 2328014850 DATC_FnDstStp 1500;
BA_REL_ "GenSigTimeoutTime" BU_SG_REL_ ATS SG_ 2328014850 DATC_OutTempDispC 1500;
BA_REL_ "GenSigTimeoutTime" BU_SG_REL_ ATS SG_ 2328014850 DATC_OutTempDispF 1500;
BA_REL_ "GenSigTimeoutTime" BU_SG_REL_ ATS SG_ 2328014850 DATC_FnDstStp_Detail 1500;
BA_REL_ "GenSigTimeoutTime" BU_SG_REL_ CGW_CCU SG_ 1464 RRSAU_RRLBCU_GST_Byte0 0;
BA_REL_ "GenSigTimeoutTime" BU_SG_REL_ CGW_CCU SG_ 1464 RRSAU_RRLBCU_GST_Byte2 0;
BA_REL_ "GenSigTimeoutTime" BU_SG_REL_ CGW_CCU SG_ 1464 RRSAU_RRLBCU_GST_Byte3 0;
BA_REL_ "GenSigTimeoutTime" BU_SG_REL_ CGW_CCU SG_ 1464 RRSAU_RRLBCU_GST_Byte4 0;
BA_REL_ "GenSigTimeoutTime" BU_SG_REL_ CGW_CCU SG_ 1464 RRSAU_RRLBCU_GST_Byte5 0;
BA_REL_ "GenSigTimeoutTime" BU_SG_REL_ CGW_CCU SG_ 1464 RRSAU_RRLBCU_GST_Byte6 0;
BA_REL_ "GenSigTimeoutTime" BU_SG_REL_ CGW_CCU SG_ 1464 RRSAU_RRLBCU_GST_Byte7 0;
BA_REL_ "GenSigTimeoutTime" BU_SG_REL_ CGW_CCU SG_ 1464 RRSAU_RRLBCU_GST_Byte1 0;
BA_REL_ "GenSigTimeoutTime" BU_SG_REL_ CGW_CCU SG_ 1465 RLSAU_RLLBCU_GST_Byte0 0;
BA_REL_ "GenSigTimeoutTime" BU_SG_REL_ CGW_CCU SG_ 1465 RLSAU_RLLBCU_GST_Byte2 0;
BA_REL_ "GenSigTimeoutTime" BU_SG_REL_ CGW_CCU SG_ 1465 RLSAU_RLLBCU_GST_Byte3 0;
BA_REL_ "GenSigTimeoutTime" BU_SG_REL_ CGW_CCU SG_ 1465 RLSAU_RLLBCU_GST_Byte4 0;
BA_REL_ "GenSigTimeoutTime" BU_SG_REL_ CGW_CCU SG_ 1465 RLSAU_RLLBCU_GST_Byte5 0;
BA_REL_ "GenSigTimeoutTime" BU_SG_REL_ CGW_CCU SG_ 1465 RLSAU_RLLBCU_GST_Byte6 0;
BA_REL_ "GenSigTimeoutTime" BU_SG_REL_ CGW_CCU SG_ 1465 RLSAU_RLLBCU_GST_Byte7 0;
BA_REL_ "GenSigTimeoutTime" BU_SG_REL_ CGW_CCU SG_ 1465 RLSAU_RLLBCU_GST_Byte1 0;
BA_REL_ "GenSigTimeoutTime" BU_SG_REL_ CGW_CCU SG_ 1466 ATS_GST_Byte0 0;
BA_REL_ "GenSigTimeoutTime" BU_SG_REL_ CGW_CCU SG_ 1466 ATS_GST_Byte2 0;
BA_REL_ "GenSigTimeoutTime" BU_SG_REL_ CGW_CCU SG_ 1466 ATS_GST_Byte3 0;
BA_REL_ "GenSigTimeoutTime" BU_SG_REL_ CGW_CCU SG_ 1466 ATS_GST_Byte4 0;
BA_REL_ "GenSigTimeoutTime" BU_SG_REL_ CGW_CCU SG_ 1466 ATS_GST_Byte5 0;
BA_REL_ "GenSigTimeoutTime" BU_SG_REL_ CGW_CCU SG_ 1466 ATS_GST_Byte6 0;
BA_REL_ "GenSigTimeoutTime" BU_SG_REL_ CGW_CCU SG_ 1466 ATS_GST_Byte7 0;
BA_REL_ "GenSigTimeoutTime" BU_SG_REL_ CGW_CCU SG_ 1466 ATS_GST_Byte1 0;
BA_REL_ "GenSigTimeoutTime" BU_SG_REL_ SGU SG_ 491 CF_AVN_Roof_OprLvSet 0;
BA_REL_ "GenSigTimeoutTime" BU_SG_REL_ SGU SG_ 491 CF_AVN_3rdRightDoor_OptLvlSet 0;
BA_REL_ "GenSigTimeoutTime" BU_SG_REL_ SGU SG_ 491 CF_AVN_RearDoor_OptLvlSet 0;
BA_REL_ "GenSigTimeoutTime" BU_SG_REL_ SGU SG_ 491 CF_AVN_RollBlindOnOffSet 0;
BA_REL_ "GenSigTimeoutTime" BU_SG_REL_ SGU SG_ 491 CF_AVN_2ndLeftDoor_OptLvSet 0;
BA_REL_ "GenSigTimeoutTime" BU_SG_REL_ RWPC SG_ 491 CF_Gway_WPCAnimationNvalueSet 0;
BA_REL_ "GenSigTimeoutTime" BU_SG_REL_ WPC SG_ 491 CF_Gway_WPCAnimationNvalueSet 0;
BA_REL_ "GenSigTimeoutTime" BU_SG_REL_ WPC2 SG_ 491 CF_Gway_WPCAnimationNvalueSet 0;
BA_REL_ "GenSigTimeoutTime" BU_SG_REL_ SWRC SG_ 491 DAB_IlluminationVrModeSet 0;
BA_REL_ "GenSigTimeoutTime" BU_SG_REL_ SGU SG_ 491 CF_AVN_2ndRightDoor_OptLvSet 0;
BA_REL_ "GenSigTimeoutTime" BU_SG_REL_ SGU SG_ 491 CF_AVN_3rdLeftDoor_OptLvlSet 0;
BA_REL_ "GenSigTimeoutTime" BU_SG_REL_ GW_APSU SG_ 2151682049 ACU_CrshActvSta 0;
BA_REL_ "GenSigTimeoutTime" BU_SG_REL_ GW_DPSU SG_ 2151682049 ACU_CrshActvSta 0;
BA_REL_ "GenSigTimeoutTime" BU_SG_REL_ GW_RLPSU SG_ 2151682049 ACU_CrshActvSta 0;
BA_REL_ "GenSigTimeoutTime" BU_SG_REL_ GW_RRPSU SG_ 2151682049 ACU_CrshActvSta 0;
BA_REL_ "GenSigTimeoutTime" BU_SG_REL_ CGW_CCU SG_ 550 PSS_RL_StSldFwdMvBtn 1500;
BA_REL_ "GenSigTimeoutTime" BU_SG_REL_ CGW_CCU SG_ 550 PSS_RL_StTltDnMvBtn 1500;
BA_REL_ "GenSigTimeoutTime" BU_SG_REL_ CGW_CCU SG_ 550 PSS_RL_StHRestUpMvBtn 1500;
BA_REL_ "GenSigTimeoutTime" BU_SG_REL_ CGW_CCU SG_ 550 PSS_RL_StHRestDnMvBtn 1500;
BA_REL_ "GenSigTimeoutTime" BU_SG_REL_ CGW_CCU SG_ 550 PSS_RL_StHRestFwdMvBtn 1500;
BA_REL_ "GenSigTimeoutTime" BU_SG_REL_ CGW_CCU SG_ 550 PSS_RL_StHRestBwdMvBtn 1500;
BA_REL_ "GenSigTimeoutTime" BU_SG_REL_ CGW_CCU SG_ 550 PSS_RL_StSldBwdMvBtn 1500;
BA_REL_ "GenSigTimeoutTime" BU_SG_REL_ CGW_CCU SG_ 550 PSS_RL_StLegRestUpBtn 1500;
BA_REL_ "GenSigTimeoutTime" BU_SG_REL_ CGW_CCU SG_ 550 PSS_RL_StLegRestDnBtn 1500;
BA_REL_ "GenSigTimeoutTime" BU_SG_REL_ CGW_CCU SG_ 550 PSS_RL_StLegRestExtFwdBtn 1500;
BA_REL_ "GenSigTimeoutTime" BU_SG_REL_ CGW_CCU SG_ 550 PSS_RL_StLegRestExtBwdBtn 1500;
BA_REL_ "GenSigTimeoutTime" BU_SG_REL_ CGW_CCU SG_ 550 PSS_RL_StRlxModeBtn 1500;
BA_REL_ "GenSigTimeoutTime" BU_SG_REL_ CGW_CCU SG_ 550 PSS_RL_StRlxReturnBtn 1500;
BA_REL_ "GenSigTimeoutTime" BU_SG_REL_ CGW_CCU SG_ 550 PSS_RL_StRlxTltUpMvBtn 1500;
BA_REL_ "GenSigTimeoutTime" BU_SG_REL_ CGW_CCU SG_ 550 PSS_RL_StRlxTltDnMvBtn 1500;
BA_REL_ "GenSigTimeoutTime" BU_SG_REL_ CGW_CCU SG_ 550 PSS_RL_StMnlRlxModeBtn 1500;
BA_REL_ "GenSigTimeoutTime" BU_SG_REL_ CGW_CCU SG_ 550 PSS_RL_StMnlRlxReturnBtn 1500;
BA_REL_ "GenSigTimeoutTime" BU_SG_REL_ CGW_CCU SG_ 550 PSS_RL_StRclFwdMvBtn 1500;
BA_REL_ "GenSigTimeoutTime" BU_SG_REL_ CGW_CCU SG_ 550 PSS_RL_WalkInSwitchSts 1500;
BA_REL_ "GenSigTimeoutTime" BU_SG_REL_ CGW_CCU SG_ 550 PSS_RL_StRclBwdMvBtn 1500;
BA_REL_ "GenSigTimeoutTime" BU_SG_REL_ CGW_CCU SG_ 550 PSS_RL_StTltUpMvBtn 1500;
BA_REL_ "GenSigTimeoutTime" BU_SG_REL_ CGW_CCU SG_ 551 PSS_RL_StOneTchWlkinCushBtn 1500;
BA_REL_ "GenSigTimeoutTime" BU_SG_REL_ CGW_CCU SG_ 551 PSS_RL_StOneTchWlkinBackBtn 1500;
BA_REL_ "GenSigTimeoutTime" BU_SG_REL_ CGW_CCU SG_ 551 PSS_RL_MomoryP1Cmd 1500;
BA_REL_ "GenSigTimeoutTime" BU_SG_REL_ CGW_CCU SG_ 551 PSS_RL_MomoryP2Cmd 1500;
BA_REL_ "GenSigTimeoutTime" BU_SG_REL_ vHS_B2 SG_ 2378399489 GATEWAY_CrcVal 1500;
BA_REL_ "GenSigTimeoutTime" BU_SG_REL_ vHS_B2 SG_ 2378399489 GATEWAY_HS_B1_STS 1500;
BA_REL_ "GenSigTimeoutTime" BU_SG_REL_ vHS_B2 SG_ 2378399489 GATEWAY_HS_B2_STS 1500;
BA_REL_ "GenSigTimeoutTime" BU_SG_REL_ vHS_B2 SG_ 2378399489 GATEWAY_HS_D_STS 1500;
BA_REL_ "GenSigTimeoutTime" BU_SG_REL_ vHS_B2 SG_ 2378399489 GATEWAY_FD_I_STS 1500;
BA_REL_ "GenSigTimeoutTime" BU_SG_REL_ CGW_CCU SG_ 552 PSS_RL_AstHRestFwdMvBtn 1500;
BA_REL_ "GenSigTimeoutTime" BU_SG_REL_ CGW_CCU SG_ 552 PSS_RL_AstRclBwdMvBtn 1500;
BA_REL_ "GenSigTimeoutTime" BU_SG_REL_ CGW_CCU SG_ 552 PSS_RL_AstSldFwdMvBtn 1500;
BA_REL_ "GenSigTimeoutTime" BU_SG_REL_ CGW_CCU SG_ 552 PSS_RL_AstSldBwdMvBtn 1500;
BA_REL_ "GenSigTimeoutTime" BU_SG_REL_ CGW_CCU SG_ 552 PSS_RL_AstHgtUpMvBtn 1500;
BA_REL_ "GenSigTimeoutTime" BU_SG_REL_ CGW_CCU SG_ 552 PSS_RL_AstHgtDnMvBtn 1500;
BA_REL_ "GenSigTimeoutTime" BU_SG_REL_ CGW_CCU SG_ 552 PSS_RL_AstHRestBwdMvBtn 1500;
BA_REL_ "GenSigTimeoutTime" BU_SG_REL_ CGW_CCU SG_ 552 PSS_RL_AstFRestOpenMvBtn 1500;
BA_REL_ "GenSigTimeoutTime" BU_SG_REL_ CGW_CCU SG_ 552 PSS_RL_AstFRestCloseMvBtn 1500;
BA_REL_ "GenSigTimeoutTime" BU_SG_REL_ CGW_CCU SG_ 552 PSS_RL_AstHRestUpMvBtn 1500;
BA_REL_ "GenSigTimeoutTime" BU_SG_REL_ CGW_CCU SG_ 552 PSS_RL_AstHRestDnMvBtn 1500;
BA_REL_ "GenSigTimeoutTime" BU_SG_REL_ CGW_CCU SG_ 552 PSS_RL_AstRclFwdMvBtn 1500;
BA_REL_ "GenSigTimeoutTime" BU_SG_REL_ CGW_CCU SG_ 553 PSS_RL_LumbarUpSw 1500;
BA_REL_ "GenSigTimeoutTime" BU_SG_REL_ DSAU SG_ 553 PSS_RL_LumbarUpSw 1500;
BA_REL_ "GenSigTimeoutTime" BU_SG_REL_ GW_DLBCU SG_ 553 PSS_RL_LumbarUpSw 1500;
BA_REL_ "GenSigTimeoutTime" BU_SG_REL_ CGW_CCU SG_ 553 PSS_RL_BolsterDefSw 1500;
BA_REL_ "GenSigTimeoutTime" BU_SG_REL_ DSAU SG_ 553 PSS_RL_BolsterDefSw 1500;
BA_REL_ "GenSigTimeoutTime" BU_SG_REL_ GW_DLBCU SG_ 553 PSS_RL_BolsterDefSw 1500;
BA_REL_ "GenSigTimeoutTime" BU_SG_REL_ CGW_CCU SG_ 553 PSS_RL_ActiveSw 1500;
BA_REL_ "GenSigTimeoutTime" BU_SG_REL_ DSAU SG_ 553 PSS_RL_ActiveSw 1500;
BA_REL_ "GenSigTimeoutTime" BU_SG_REL_ GW_DLBCU SG_ 553 PSS_RL_ActiveSw 1500;
BA_REL_ "GenSigTimeoutTime" BU_SG_REL_ CGW_CCU SG_ 553 PSS_RL_LumbarMidSw 1500;
BA_REL_ "GenSigTimeoutTime" BU_SG_REL_ DSAU SG_ 553 PSS_RL_LumbarMidSw 1500;
BA_REL_ "GenSigTimeoutTime" BU_SG_REL_ GW_DLBCU SG_ 553 PSS_RL_LumbarMidSw 1500;
BA_REL_ "GenSigTimeoutTime" BU_SG_REL_ CGW_CCU SG_ 553 PSS_RL_LumbarLowSw 1500;
BA_REL_ "GenSigTimeoutTime" BU_SG_REL_ DSAU SG_ 553 PSS_RL_LumbarLowSw 1500;
BA_REL_ "GenSigTimeoutTime" BU_SG_REL_ GW_DLBCU SG_ 553 PSS_RL_LumbarLowSw 1500;
BA_REL_ "GenSigTimeoutTime" BU_SG_REL_ CGW_CCU SG_ 553 PSS_RL_LumbarDefSw 1500;
BA_REL_ "GenSigTimeoutTime" BU_SG_REL_ DSAU SG_ 553 PSS_RL_LumbarDefSw 1500;
BA_REL_ "GenSigTimeoutTime" BU_SG_REL_ GW_DLBCU SG_ 553 PSS_RL_LumbarDefSw 1500;
BA_REL_ "GenSigTimeoutTime" BU_SG_REL_ CGW_CCU SG_ 553 PSS_RL_BolsterInfSw 1500;
BA_REL_ "GenSigTimeoutTime" BU_SG_REL_ DSAU SG_ 553 PSS_RL_BolsterInfSw 1500;
BA_REL_ "GenSigTimeoutTime" BU_SG_REL_ GW_DLBCU SG_ 553 PSS_RL_BolsterInfSw 1500;
BA_REL_ "GenSigTimeoutTime" BU_SG_REL_ ATS SG_ 2449771009 ODS_OccClassSta 5000;
BA_REL_ "GenSigTimeoutTime" BU_SG_REL_ GW_APSU SG_ 2449771009 ODS_OccClassSta 5000;
BA_REL_ "GenSigTimeoutTime" BU_SG_REL_ GW_DPSU SG_ 2449771009 ODS_OccClassSta 5000;
BA_REL_ "GenSigTimeoutTime" BU_SG_REL_ GW_RLPSU SG_ 2449771009 ODS_OccClassSta 5000;
BA_REL_ "GenSigTimeoutTime" BU_SG_REL_ GW_RRPSU SG_ 2449771009 ODS_OccClassSta 5000;
BA_REL_ "GenSigTimeoutTime" BU_SG_REL_ ATS SG_ 2395189505 DATC_FragranceStrhSta 1500;
BA_REL_ "GenSigTimeoutTime" BU_SG_REL_ ATS SG_ 2395189505 DATC_FragranceKindSta 1500;
BA_REL_ "GenSigTimeoutTime" BU_SG_REL_ ATS SG_ 2395189505 DATC_RrBlwDis 1500;
BA_REL_ "GenSigTimeoutTime" BU_SG_REL_ ATS SG_ 2395189505 DATC_ArClnStepClr 1500;
BA_REL_ "GenSigTimeoutTime" BU_SG_REL_ ATS SG_ 2395189505 DATC_ArClnSmblTyp 1500;
BA_REL_ "GenSigTimeoutTime" BU_SG_REL_ GW_APSU SG_ 1616 MKBD_SeatKeySet 0;
BA_REL_ "GenSigTimeoutTime" BU_SG_REL_ GW_DPSU SG_ 1616 MKBD_SeatKeySet 0;
BA_REL_ "GenSigTimeoutTime" BU_SG_REL_ SHVU_FR SG_ 1616 MKBD_SeatKeySet 0;
VAL_ 479 ALBCU_LumbarUpDis 0 "default" 1 "off" 2 "on" 3 "invalid" ;
VAL_ 479 ALBCU_BolsterDefDis 0 "default" 1 "off" 2 "on" 3 "invalid" ;
VAL_ 479 ALBCU_CushInfDis 0 "default" 1 "off" 2 "on" 3 "invalid" ;
VAL_ 479 ALBCU_CushDefDis 0 "default" 1 "off" 2 "on" 3 "invalid" ;
VAL_ 479 ALBCU_ActiveDis 0 "Default" 1 "Off" 2 "Mode1" 3 "Mode2" 4 "Mode3" 5 "Reserved" 6 "Reserved" 7 "Invalid" ;
VAL_ 479 ALBCU_DrvModUSMSta 0 "Default" 1 "Off" 2 "On" 3 "Invalid" ;
VAL_ 479 ALBCU_LumbarMidDis 0 "default" 1 "off" 2 "on" 3 "invalid" ;
VAL_ 479 ALBCU_ActiveStrSta 0 "Default" 1 "Normal" 2 "Intensity" 3 "Invalid" ;
VAL_ 479 ALBCU_ActiveTimeSta 0 "Default" 1 "10min" 2 "15min" 3 "20min" 4 "Reserved" 5 "Reserved" 6 "Reserved" 7 "Invalid" ;
VAL_ 479 ALBCU_CellOpt 0 "Default" 1 "3Cell" 2 "5Cell" 3 "7Cell" 4 "Invalid" 5 "Invalid" 6 "Invalid" 7 "Invalid" ;
VAL_ 479 ALBCU_BodySpprtSta 0 "Default" 1 "Off" 2 "On" 3 "Invalid" ;
VAL_ 479 ALBCU_BodySpprtDis 0 "Default" 1 "Off" 2 "On" 3 "Invalid" ;
VAL_ 479 ALBCU_SmartCtrl_Set_Rvalue 0 "Init" 1 "Off" 2 "10min" 3 "20min" 4 "30min" 5 "40min" 6 "50min" 7 "60min" 8 "RESERVED" 9 "RESERVED" 10 "RESERVED" 11 "RESERVED" 12 "RESERVED" 13 "RESERVED" 14 "RESERVED" 15 "Invalid" ;
VAL_ 479 ALBCU_MoodTrpyRValueSet 0 "Default" 1 "Off" 2 "On" 3 "Invalid" ;
VAL_ 479 ALBCU_MoodTrpyCareSta 0 "Default" 1 "Off" 2 "On" 3 "Invalid" ;
VAL_ 479 ALBCU_LumbarLowDis 0 "default" 1 "off" 2 "on" 3 "invalid" ;
VAL_ 479 ALBCU_MoodTrpyComfSta 0 "Default" 1 "Off" 2 "On" 3 "Invalid" ;
VAL_ 479 ALBCU_CushLeftPSnsrVtg 0 "Voltage" 1 "Voltage" 2 "Voltage" 3 "Voltage" 4 "Voltage" 5 "Voltage" 6 "Voltage" 7 "Voltage" 8 "Voltage" 9 "Voltage" 10 "Voltage" 11 "Voltage" 12 "Voltage" 13 "Voltage" 14 "Voltage" 15 "Voltage" 16 "Voltage" 17 "Voltage" 18 "Voltage" 19 "Voltage" 20 "Voltage" 21 "Voltage" 22 "Voltage" 23 "Voltage" 24 "Voltage" 25 "Voltage" 26 "Voltage" 27 "Voltage" 28 "Voltage" 29 "Voltage" 30 "Voltage" 31 "Voltage" 32 "Voltage" 33 "Voltage" 34 "Voltage" 35 "Voltage" 36 "Voltage" 37 "Voltage" 38 "Voltage" 39 "Voltage" 40 "Voltage" 41 "Voltage" 42 "Voltage" 43 "Voltage" 44 "Voltage" 45 "Voltage" 46 "Voltage" 47 "RESERVED" 48 "RESERVED" 49 "RESERVED" 50 "RESERVED" 51 "RESERVED" 52 "RESERVED" 53 "RESERVED" 54 "RESERVED" 55 "RESERVED" 56 "RESERVED" 57 "RESERVED" 58 "RESERVED" 59 "RESERVED" 60 "RESERVED" 61 "RESERVED" 62 "RESERVED" 63 "Invalid" ;
VAL_ 479 ALBCU_CushRightPSnsrVtg 0 "Voltage" 1 "Voltage" 2 "Voltage" 3 "Voltage" 4 "Voltage" 5 "Voltage" 6 "Voltage" 7 "Voltage" 8 "Voltage" 9 "Voltage" 10 "Voltage" 11 "Voltage" 12 "Voltage" 13 "Voltage" 14 "Voltage" 15 "Voltage" 16 "Voltage" 17 "Voltage" 18 "Voltage" 19 "Voltage" 20 "Voltage" 21 "Voltage" 22 "Voltage" 23 "Voltage" 24 "Voltage" 25 "Voltage" 26 "Voltage" 27 "Voltage" 28 "Voltage" 29 "Voltage" 30 "Voltage" 31 "Voltage" 32 "Voltage" 33 "Voltage" 34 "Voltage" 35 "Voltage" 36 "Voltage" 37 "Voltage" 38 "Voltage" 39 "Voltage" 40 "Voltage" 41 "Voltage" 42 "Voltage" 43 "Voltage" 44 "Voltage" 45 "Voltage" 46 "Voltage" 47 "RESERVED" 48 "RESERVED" 49 "RESERVED" 50 "RESERVED" 51 "RESERVED" 52 "RESERVED" 53 "RESERVED" 54 "RESERVED" 55 "RESERVED" 56 "RESERVED" 57 "RESERVED" 58 "RESERVED" 59 "RESERVED" 60 "RESERVED" 61 "RESERVED" 62 "RESERVED" 63 "Invalid" ;
VAL_ 479 ALBCU_LumbarDefDis 0 "default" 1 "off" 2 "on" 3 "invalid" ;
VAL_ 479 ALBCU_BolsterInfDis 0 "default" 1 "off" 2 "on" 3 "invalid" ;
VAL_ 2223056129 SAS_AnglVal 0 "0x0x0000~0x7FFE:real value" 32766 "0x0x0000~0x7FFE:real value" 32767 "Error Indicator" 32768 "0x8000~0xFFFF:real value" 65535 "0x8000~0xFFFF:real value" ;
VAL_ 2223056129 SAS_SpdVal 0 "0x0x00~0xFE:real value" 254 "0x0x00~0xFE:real value" 255 "Error Indicator" ;
VAL_ 2223056129 SAS_IntSta 0 "real vaule" 1 "real vaule" 2 "real vaule" 3 "real vaule" 4 "real vaule" 5 "real vaule" 6 "real vaule" 7 "real vaule" 8 "real vaule" 9 "real vaule" 10 "real vaule" 11 "real vaule" 12 "real vaule" 13 "real vaule" 14 "real vaule" 15 "real vaule" 16 "0x10~0xFF:RESERVED" 255 "0x10~0xFF:RESERVED" ;
VAL_ 463 SWRC_Crc3Val 0 "0x0x0~0xFF:CRCValue" 255 "0x0x0~0xFF:CRCValue" ;
VAL_ 463 SWRC_AlvCnt3Val 0 "AlvCntValue" 1 "AlvCntValue" 2 "AlvCntValue" 3 "AlvCntValue" 4 "AlvCntValue" 5 "AlvCntValue" 6 "AlvCntValue" 7 "AlvCntValue" 8 "AlvCntValue" 9 "AlvCntValue" 10 "AlvCntValue" 11 "AlvCntValue" 12 "AlvCntValue" 13 "AlvCntValue" 14 "AlvCntValue" 15 "AlvCntValue" ;
VAL_ 463 SWRC_CrsSwSta 0 "Idle Position" 1 "Plus/Set" 2 "Minus/Set" 3 "Time gap (Distance, SCC only)" 4 "Pause/Resume" 5 "RESERVED" 6 "RESERVED" 7 "RESERVED" ;
VAL_ 463 SWRC_CrsMainSwSta 0 "Off" 1 "Key On" 2 "RESERVED" 3 "Invalid" ;
VAL_ 463 SWRC_SldMainSwSta 0 "Off" 1 "Key On" 2 "Reserved" 3 "Invalid" ;
VAL_ 463 SWRC_LFASwSta 0 "Off" 1 "Key On" 2 "RESERVED" 3 "Invalid" ;
VAL_ 463 SWRC_PaddleUpSwSta 0 "Off" 1 "Key On" 2 "Reserved" 3 "Invalid" ;
VAL_ 463 SWRC_PaddleDnSwSta 0 "Off" 1 "Key On" 2 "Reserved" 3 "Invalid" ;
VAL_ 463 SWRC_Info 0 "Off" 1 "ON(CAN Type)" 2 "RESERVED" 3 "Error Indicator" ;
VAL_ 463 SWRC_HdpSwSta 0 "Off" 1 "Key On" 2 "Reserved" 3 "Invalid" ;
VAL_ 463 SWRC_HDPSpprtSWVer 0 "Not Support (Init)" 1 "Software Version" 2 "Software Version" 3 "Software Version" 4 "Software Version" 5 "Software Version" 6 "Software Version" 7 "Software Version" 8 "Software Version" 9 "Software Version" 10 "Software Version" 11 "Software Version" 12 "Software Version" 13 "Software Version" 14 "Software Version" 15 "Software Version" 16 "Software Version" 17 "Software Version" 18 "Software Version" 19 "Software Version" 20 "Software Version" 21 "Software Version" 22 "Software Version" 23 "Software Version" 24 "Software Version" 25 "Software Version" 26 "Software Version" 27 "Software Version" 28 "Software Version" 29 "Software Version" 30 "Software Version" 31 "Software Version" ;
VAL_ 2382595329 ICSC_Crc3Val 0 "0x0x0~0xFFFF:CRCValue" 65535 "0x0x0~0xFFFF:CRCValue" ;
VAL_ 2382595329 ICSC_AlvCnt3Val 0 "0x0x0~0xFF:AlvCntValue" 255 "0x0x0~0xFF:AlvCntValue" ;
VAL_ 2382595329 DMIC_OffRdMod 0 "Default" 1 "Snow" 2 "Sand" 3 "Mud" 4 "AWD Lock" 5 "Rock" 6 "RESERVED" 7 "Error Indicator" ;
VAL_ 2382595329 DMIC_OffRdModActvSta 0 "ONROAD" 1 "OFFROAD" 2 "Not used" 3 "Error Indicator" ;
VAL_ 2382595329 DMIC_OffRdModSta 0 "Selected Mode" 1 "Changed Mode" 2 "Not used" 3 "Error Indicator" ;
VAL_ 2382595329 OFFROAD_TypeSta 0 "not applied" 1 "Terrain w/Botton" 2 "Traction w/Botton" 3 "w/o Botton" ;
VAL_ 2328014850 DATC_FnDstStp 0 "Default" 1 "Good" 2 "Normal" 3 "Poor" 4 "Very Poor" 5 "Reserved" 6 "Reserved" 7 "Error Indicator" ;
VAL_ 2328014850 DATC_OutTempOpt 0 "Not Applied (Default)" 1 "Applied (Send)" 2 "Reserved" 3 "Error Indicator" ;
VAL_ 2328014850 DATC_OutTempDispC 0 "Default" 1 "Blank Display" 254 "Sensor Fail (--Display)" 255 "Invalid" ;
VAL_ 2328014850 DATC_OutTempDispF 0 "Default" 1 "Blank Display" 254 "Sensor Fail (--Display)" 255 "Invalid" ;
VAL_ 2328014850 DATC_EngOffReqWaterTemp 0 "(Default)" 1 "Reserved" 2 "40¡É~100¡É" 3 "40¡É~100¡É" 4 "40¡É~100¡É" 5 "40¡É~100¡É" 6 "40¡É~100¡É" 7 "40¡É~100¡É" 8 "40¡É~100¡É" 9 "40¡É~100¡É" 10 "40¡É~100¡É" 11 "40¡É~100¡É" 12 "40¡É~100¡É" 13 "40¡É~100¡É" 14 "40¡É~100¡É" 15 "40¡É~100¡É" 16 "40¡É~100¡É" 17 "40¡É~100¡É" 18 "40¡É~100¡É" 19 "40¡É~100¡É" 20 "40¡É~100¡É" 21 "40¡É~100¡É" 22 "40¡É~100¡É" 23 "40¡É~100¡É" 24 "40¡É~100¡É" 25 "40¡É~100¡É" 26 "40¡É~100¡É" 27 "40¡É~100¡É" 28 "40¡É~100¡É" 29 "40¡É~100¡É" 30 "40¡É~100¡É" 31 "40¡É~100¡É" 32 "40¡É~100¡É" 33 "40¡É~100¡É" 34 "40¡É~100¡É" 35 "40¡É~100¡É" 36 "40¡É~100¡É" 37 "40¡É~100¡É" 38 "40¡É~100¡É" 39 "40¡É~100¡É" 40 "40¡É~100¡É" 41 "40¡É~100¡É" 42 "40¡É~100¡É" 43 "40¡É~100¡É" 44 "40¡É~100¡É" 45 "40¡É~100¡É" 46 "40¡É~100¡É" 47 "40¡É~100¡É" 48 "40¡É~100¡É" 49 "40¡É~100¡É" 50 "40¡É~100¡É" 51 "40¡É~100¡É" 52 "40¡É~100¡É" 53 "40¡É~100¡É" 54 "40¡É~100¡É" 55 "40¡É~100¡É" 56 "40¡É~100¡É" 57 "40¡É~100¡É" 58 "40¡É~100¡É" 59 "40¡É~100¡É" 60 "40¡É~100¡É" 61 "40¡É~100¡É" 62 "40¡É~100¡É" 63 "Error Indicator" ;
VAL_ 2328014850 DATC_CELOModeSta 0 "Not CELO (Default)" 1 "CELO Def" 2 "CELO Mix" 3 "Error Indicator" ;
VAL_ 2328014850 DATC_HDPDfg_Sta 0 "Default" 1 "Defog Deactivate for HDP" 2 "Defog Activate for HDP" 3 "Error Indicator" ;
VAL_ 2328014850 DATC_HDPSpprtSWVer 0 "Not support" 1 "Spec Ver" 2 "Spec Ver" 3 "Spec Ver" 4 "Spec Ver" 5 "Spec Ver" 6 "Spec Ver" 7 "Spec Ver" 8 "Spec Ver" 9 "Spec Ver" 10 "Spec Ver" 11 "Spec Ver" 12 "Spec Ver" 13 "Spec Ver" 14 "Spec Ver" 15 "Spec Ver" 16 "Spec Ver" 17 "Spec Ver" 18 "Spec Ver" 19 "Spec Ver" 20 "Spec Ver" 21 "Spec Ver" 22 "Spec Ver" 23 "Spec Ver" 24 "Spec Ver" 25 "Spec Ver" 26 "Spec Ver" 27 "Spec Ver" 28 "Spec Ver" 29 "Spec Ver" 30 "Spec Ver" 31 "Error Indicator" ;
VAL_ 2328014850 DATC_HDPHumidity_Sta 0 "Default" 1 "Not Need ADS for HDP" 2 "Need ADS for HDP" 3 "Error Indicator" ;
VAL_ 2328014850 DATC_FnDstStp_Detail 0 "Default" 1 "Good_0" 2 "Good_1" 3 "Good_2" 4 "Good_3" 5 "Good_4" 6 "Normal_1" 7 "Normal_2" 8 "Normal_3" 9 "Normal_4" 10 "Poor_1" 11 "Poor_2" 12 "Poor_3" 13 "Poor_4" 14 "Very Poor_1" 15 "Very Poor_2" 16 "Very Poor_3" 17 "Very Poor_4" 18 "Reserved" 19 "Reserved" 20 "Reserved" 21 "Reserved" 22 "Reserved" 23 "Reserved" 24 "Reserved" 25 "Reserved" 26 "Reserved" 27 "Reserved" 28 "Sensor Off" 29 "Sensor Initializing" 30 "Sensor Fail" 31 "Error Indicator" ;
VAL_ 2328014849 DATC_Crc17Val 0 "0x0x0~0xFFFF:CRCValue" 65535 "0x0x0~0xFFFF:CRCValue" ;
VAL_ 2328014849 DATC_AlvCnt17Val 0 "0x0x0~0xFF:AlvCntValue" 255 "0x0x0~0xFF:AlvCntValue" ;
VAL_ 2328014849 DATC_FrontPwmIsVolt 255 "Error Indicator" ;
VAL_ 2328014849 DATC_FrontBlwDuty 255 "Error Indicator" ;
VAL_ 2328014849 DATC_FrontBlwDiagStat 0 "Default" 1 "Normal State" 2 "Blower Motor Stall" 3 "Reserved" 4 "Reserved" 5 "Reserved" 6 "Reserved" 7 "Error Indicator" ;
VAL_ 2328014849 DATC_BlwrLvl_Ps 0 "OFF" 1 "0 Level" 2 "1 Level" 3 "2 Level" 4 "3 Level" 5 "4 Level" 6 "5 Level" 7 "6 Level" 8 "7 Level" 9 "8 Level" 10 "Reserved" 11 "Reserved" 12 "Reserved" 13 "Reserved" 14 "Reserved" 15 "Error Indicator" ;
VAL_ 2328014849 DATC_BlwrLvl_Rr 0 "OFF" 1 "0 level" 2 "1 level" 3 "2 level" 4 "3 level" 5 "4 level" 6 "5 level" 7 "6 level" 8 "7 evel" 9 "8 level" 10 "Reserved" 11 "Reserved" 12 "Reserved" 13 "Reserved" 14 "Reserved" 15 "Error Indicator" ;
VAL_ 2328014849 DATC_SwlSta 0 "ON LAMP OFF&OFF LAMP OFF" 1 "ON LAMP OFF&OFF LAMP ON" 2 "ON LAMP ON&OFF LAMP OFF" 3 "ON LAMP ON&OFF LAMP ON" 4 "ACU message error" 7 "Lamp Circuit Failure" ;
VAL_ 2328014849 DATC_FnDstSnsrVal 508 "Sensor Off" 509 "Sensor Initializing" 510 "Sensor Fail" 511 "Error Indicator" ;
VAL_ 491 CF_AVN_Roof_OprLvSet 0 "Default" 1 "Off" 2 "Level1" 3 "Level2" 4 "Level3" 5 "Level4" 6 "Level5" 7 "Invalid" ;
VAL_ 491 CF_AVN_3rdRightDoor_OptLvlSet 0 "Default" 1 "Off" 2 "Level1" 3 "Level2" 4 "Level3" 5 "Level4" 6 "Level5" 7 "Invalid" ;
VAL_ 491 CF_AVN_RearDoor_OptLvlSet 0 "Default" 1 "Off" 2 "Level1" 3 "Level2" 4 "Level3" 5 "Level4" 6 "Level5" 7 "Invalid" ;
VAL_ 491 CF_AVN_RollBlindOnOffSet 0 "Default" 1 "Off" 2 "On" 3 "Invalid" ;
VAL_ 491 CF_AVN_CluThmAutoSet_New 0 "Default" 1 "Disable" 2 "Enable" 3 "Invalid" ;
VAL_ 491 CF_AVN_CluThmSet_New 0 "Default" 1 "Select Theme 1" 2 "Select Theme 2" 3 "Select Theme 3" 4 "Select Theme 4" 5 "Select Theme 5" 6 "Select Theme 6" 7 "Invalid" ;
VAL_ 491 CF_AVN_CluThmDtlSet_New 0 "Default" 1 "Select Theme 1" 2 "Select Theme 2" 3 "Select Theme 3" 4 "Select Theme 4" 5 "Select Theme 5" 6 "Select Theme 6 (Link to Drive Mode)" 7 "Invalid" ;
VAL_ 491 CF_AVN_MdLmpAIVoiceUSMNValueSet 0 "Default" 1 "Off" 2 "On" 3 "Invalid" ;
VAL_ 491 CF_AVN_2ndLeftDoor_OptLvSet 0 "Default" 1 "Off" 2 "Level1" 3 "Level2" 4 "Level3" 5 "Level4" 6 "Level5" 7 "Invalid" ;
VAL_ 491 CF_AVN_DWL_SelectNvalueSet 0 "Default" 1 "Select Concept A" 2 "Select Concept B" 3 "Select Concept C" 4 "Select Concept D" 5 "Select Concept E" 6 "Select Concept F" 7 "Select Concept G" 8 "Select Concept H" 9 "Select Concept I" 10 "Select Concept J" 11 "RESERVED" 12 "RESERVED" 13 "RESERVED" 14 "RESERVED" 15 "Invalid" ;
VAL_ 491 PwrDRClosingDrvDrReq 0 "Default" 1 "Close" 2 "Stop" 3 "Invalid" ;
VAL_ 491 CF_Gway_WPCAnimationNvalueSet 0 "Default" 1 "Type 1 (Animation Off)" 2 "Type 2 (Animation On)" 3 "Reserved" 4 "Reserved" 5 "Reserved" 6 "Reserved" 7 "Invalid" ;
VAL_ 491 PwrDRClosingAstDrReq 0 "Default" 1 "Close" 2 "Stop" 3 "Invalid" ;
VAL_ 491 PwrDRClosingRLDrReq 0 "Default" 1 "Close" 2 "Stop" 3 "Invalid" ;
VAL_ 491 PwrDrClosingRRDrReq 0 "Default" 1 "Close" 2 "Stop" 3 "Invalid" ;
VAL_ 491 USM_BtnIllumiAlwaysOnReq 0 "Default" 1 "Off" 2 "On" 3 "Invalid" ;
VAL_ 491 CF_AVN_LKAWrngVolNvalueSet 0 "Default" 1 "Off" 2 "On" 3 "Invalid" ;
VAL_ 491 DAB_IlluminationVrModeSet 0 "Default" 1 "AI Voice Start" 2 "User Response" 3 "User No Response" 4 "Processing" 5 "AI Voice Response" 6 "AI Voice End" 7 "Invalid" ;
VAL_ 491 USM_IllAlwaysOnwithPSTNReq 0 "Default" 1 "OFF" 2 "illumination Always On" 3 "illumination Always On with PSTN" 4 "RESERVED" 5 "RESERVED" 6 "RESERVED" 7 "Invalid" ;
VAL_ 491 CF_AVN_AutoStopTimerResetSet 0 "Default" 1 "Manual Reset" 2 "Link to Current Trip" 3 "Since Refueling" 4 "Since Reset" 5 "RESERVED" 6 "RESERVED" 7 "Invalid" ;
VAL_ 491 CF_AVN_2ndRightDoor_OptLvSet 0 "Default" 1 "Off" 2 "Level1" 3 "Level2" 4 "Level3" 5 "Level4" 6 "Level5" 7 "Invalid" ;
VAL_ 491 USM_RrCurtainSet 0 "Default" 1 "Off" 2 "On" 3 "Invalid" ;
VAL_ 491 CF_AVN_3rdLeftDoor_OptLvlSet 0 "Default" 1 "Off" 2 "Level1" 3 "Level2" 4 "Level3" 5 "Level4" 6 "Level5" 7 "Invalid" ;
VAL_ 2151682049 ACU_Crc2Val 0 "0x0x0~0xFFFF:CRCValue" 65535 "0x0x0~0xFFFF:CRCValue" ;
VAL_ 2151682049 ACU_AlvCnt2Val 0 "0x0x0~0xFF:AlvCntValue" 255 "0x0x0~0xFF:AlvCntValue" ;
VAL_ 2151682049 ACU_CrshActvSta 0 "Crash Active time is expired (Crash is Inactive)" 1 "Crash Active time started (Crash Detected)" 2 "Not used" 3 "Error Indicator" ;
VAL_ 2151682049 ACU_CrshInfo 0 "Received ESC feedback signal" 1 "Crash output signal not issued" 2 "Crash output signal issued" ;
VAL_ 550 PSS_RL_StSldFwdMvBtn 0 "Default" 1 "Off" 2 "On" 3 "Invalid" ;
VAL_ 550 PSS_RL_StTltDnMvBtn 0 "Default" 1 "Off" 2 "On" 3 "Invalid" ;
VAL_ 550 PSS_RL_StHRestUpMvBtn 0 "Default" 1 "Off" 2 "On" 3 "Invalid" ;
VAL_ 550 PSS_RL_StHRestDnMvBtn 0 "Default" 1 "Off" 2 "On" 3 "Invalid" ;
VAL_ 550 PSS_RL_StHRestFwdMvBtn 0 "Default" 1 "Off" 2 "On" 3 "Invalid" ;
VAL_ 550 PSS_RL_StHRestBwdMvBtn 0 "Default" 1 "Off" 2 "On" 3 "Invalid" ;
VAL_ 550 PSS_RL_StSldBwdMvBtn 0 "Default" 1 "Off" 2 "On" 3 "Invalid" ;
VAL_ 550 PSS_RL_StLegRestUpBtn 0 "Default" 1 "Off" 2 "On" 3 "Invalid" ;
VAL_ 550 PSS_RL_StLegRestDnBtn 0 "Default" 1 "Off" 2 "On" 3 "Invalid" ;
VAL_ 550 PSS_RL_StLegRestExtFwdBtn 0 "Default" 1 "Off" 2 "On" 3 "Invalid" ;
VAL_ 550 PSS_RL_StLegRestExtBwdBtn 0 "Default" 1 "Off" 2 "On" 3 "Invalid" ;
VAL_ 550 PSS_RL_StRlxModeBtn 0 "Default" 1 "Off" 2 "On" 3 "Invalid" ;
VAL_ 550 PSS_RL_StRlxReturnBtn 0 "Default" 1 "Off" 2 "On" 3 "Invalid" ;
VAL_ 550 PSS_RL_StRlxTltUpMvBtn 0 "Default" 1 "Off" 2 "On" 3 "Invalid" ;
VAL_ 550 PSS_RL_StRlxTltDnMvBtn 0 "Default" 1 "Off" 2 "On" 3 "Invalid" ;
VAL_ 550 PSS_RL_StMnlRlxModeBtn 0 "Default" 1 "Off" 2 "On" 3 "Invalid" ;
VAL_ 550 PSS_RL_StMnlRlxReturnBtn 0 "Default" 1 "Off" 2 "On" 3 "Invalid" ;
VAL_ 550 PSS_RL_StRclFwdMvBtn 0 "Default" 1 "Off" 2 "On" 3 "Invalid" ;
VAL_ 550 PSS_RL_WalkInSwitchSts 0 "Default" 1 "Off" 2 "On" 3 "Invalid" ;
VAL_ 550 PSS_RL_StRclBwdMvBtn 0 "Default" 1 "Off" 2 "On" 3 "Invalid" ;
VAL_ 550 PSS_RL_StTltUpMvBtn 0 "Default" 1 "Off" 2 "On" 3 "Invalid" ;
VAL_ 551 PSS_RL_StOneTchWlkinCushBtn 0 "Default" 1 "Off" 2 "On" 3 "Invalid" ;
VAL_ 551 PSS_RL_StOneTchWlkinBackBtn 0 "Default" 1 "Off" 2 "On" 3 "Invalid" ;
VAL_ 551 PSS_RL_MomoryP1Cmd 0 "Default" 1 "Off" 2 "On" 3 "Invalid" ;
VAL_ 551 PSS_RL_MomoryP2Cmd 0 "Default" 1 "Off" 2 "On" 3 "Invalid" ;
VAL_ 2378399489 GATEWAY_CrcVal 0 "0x0x0~0xFF:CRCValue" 255 "0x0x0~0xFF:CRCValue" ;
VAL_ 2378399489 GATEWAY_AlvCntVal 0 "AlvCntValue" 1 "AlvCntValue" 2 "AlvCntValue" 3 "AlvCntValue" 4 "AlvCntValue" 5 "AlvCntValue" 6 "AlvCntValue" 7 "AlvCntValue" 8 "AlvCntValue" 9 "AlvCntValue" 10 "AlvCntValue" 11 "AlvCntValue" 12 "AlvCntValue" 13 "AlvCntValue" 14 "AlvCntValue" 15 "AlvCntValue" ;
VAL_ 2378399489 GATEWAY_HS_B1_STS 0 "Default" 1 "Inactive" 2 "Active" 3 "Bus Off" 4 "Reserved" 5 "Reserved" 6 "Reserved" 7 "Error" ;
VAL_ 2378399489 GATEWAY_HS_B2_STS 0 "Default" 1 "Inactive" 2 "Active" 3 "Bus Off" 4 "Reserved" 5 "Reserved" 6 "Reserved" 7 "Error" ;
VAL_ 2378399489 GATEWAY_HS_D_STS 0 "Default" 1 "DiagMsgNotExist" 2 "DiagMsgExist" 3 "Reserved" 4 "Reserved" 5 "Reserved" 6 "Reserved" 7 "Error" ;
VAL_ 2378399489 GATEWAY_HS_I_STS 0 "Default" 1 "Inactive" 2 "Active" 3 "Bus Off" 4 "Reserved" 5 "Reserved" 6 "Reserved" 7 "Error" ;
VAL_ 2378399489 GATEWAY_HS_M_STS 0 "Default" 1 "Inactive" 2 "Active" 3 "Bus Off" 4 "Reserved" 5 "Reserved" 6 "Reserved" 7 "Error" ;
VAL_ 2378399489 GATEWAY_FD_C_STS 0 "Default" 1 "Inactive" 2 "Active" 3 "Bus Off" 4 "Reserved" 5 "Reserved" 6 "Reserved" 7 "Error" ;
VAL_ 2378399489 GATEWAY_FD_P1_STS 0 "Default" 1 "Inactive" 2 "Active" 3 "Bus Off" 4 "Reserved" 5 "Reserved" 6 "Reserved" 7 "Error" ;
VAL_ 2378399489 GATEWAY_FD_P2_STS 0 "Default" 1 "Inactive" 2 "Active" 3 "Bus Off" 4 "Reserved" 5 "Reserved" 6 "Reserved" 7 "Error" ;
VAL_ 2378399489 GATEWAY_FD_E_STS 0 "Default" 1 "Inactive" 2 "Active" 3 "Bus Off" 4 "Reserved" 5 "Reserved" 6 "Reserved" 7 "Error" ;
VAL_ 2378399489 GATEWAY_FD_I_STS 0 "Default" 1 "Inactive" 2 "Active" 3 "Bus Off" 4 "Reserved" 5 "Reserved" 6 "Reserved" 7 "Error" ;
VAL_ 2378399489 GATEWAY_ERT_ACT_STS 0 "Default" 1 "Off" 2 "On" 3 "RESERVED" ;
VAL_ 552 PSS_RL_AstHRestFwdMvBtn 0 "Default" 1 "Off" 2 "On" 3 "Invalid" ;
VAL_ 552 PSS_RL_AstRclBwdMvBtn 0 "Default" 1 "Off" 2 "On" 3 "Invalid" ;
VAL_ 552 PSS_RL_AstSldFwdMvBtn 0 "Default" 1 "Off" 2 "On" 3 "Invalid" ;
VAL_ 552 PSS_RL_AstSldBwdMvBtn 0 "Default" 1 "Off" 2 "On" 3 "Invalid" ;
VAL_ 552 PSS_RL_AstHgtUpMvBtn 0 "Default" 1 "Off" 2 "On" 3 "Invalid" ;
VAL_ 552 PSS_RL_AstHgtDnMvBtn 0 "Default" 1 "Off" 2 "On" 3 "Invalid" ;
VAL_ 552 PSS_RL_AstHRestBwdMvBtn 0 "Default" 1 "Off" 2 "On" 3 "Invalid" ;
VAL_ 552 PSS_RL_AstFRestOpenMvBtn 0 "Default" 1 "Off" 2 "On" 3 "Invalid" ;
VAL_ 552 PSS_RL_AstFRestCloseMvBtn 0 "Default" 1 "Off" 2 "On" 3 "Invalid" ;
VAL_ 552 PSS_RL_AstHRestUpMvBtn 0 "Default" 1 "Off" 2 "On" 3 "Invalid" ;
VAL_ 552 PSS_RL_AstHRestDnMvBtn 0 "Default" 1 "Off" 2 "On" 3 "Invalid" ;
VAL_ 552 PSS_RL_AstRclFwdMvBtn 0 "Default" 1 "Off" 2 "On" 3 "Invalid" ;
VAL_ 553 PSS_RL_LumbarUpSw 0 "Default" 1 "Off" 2 "On" 3 "Invalid" ;
VAL_ 553 PSS_RL_BolsterDefSw 0 "Default" 1 "Off" 2 "On" 3 "Invalid" ;
VAL_ 553 PSS_RL_ActiveSw 0 "Default" 1 "Off" 2 "On" 3 "Invalid" ;
VAL_ 553 PSS_RL_LumbarMidSw 0 "Default" 1 "Off" 2 "On" 3 "Invalid" ;
VAL_ 553 PSS_RL_LumbarLowSw 0 "Default" 1 "Off" 2 "On" 3 "Invalid" ;
VAL_ 553 PSS_RL_LumbarDefSw 0 "Default" 1 "Off" 2 "On" 3 "Invalid" ;
VAL_ 553 PSS_RL_BolsterInfSw 0 "Default" 1 "Off" 2 "On" 3 "Invalid" ;
VAL_ 2449771009 ODS_OccClassSta 1 "Class1" 2 "Class2" 4 "Indeterminate" ;
VAL_ 2449771009 ODS_SBRClassSta 0 "Empty / Indeterminate" 1 "Occupied" ;
VAL_ 2395189505 DATC_Crc9Val 0 "0x0x0~0xFFFF:CRCValue" 65535 "0x0x0~0xFFFF:CRCValue" ;
VAL_ 2395189505 DATC_AlvCnt9Val 0 "0x0x0~0xFF:AlvCntValue" 255 "0x0x0~0xFF:AlvCntValue" ;
VAL_ 2395189505 DATC_FragranceStrhSta 0 "Default" 1 "Off" 2 "Low" 3 "Medium" 4 "High" 5 "Reserved" 6 "Reserved" 7 "Error Indicator" ;
VAL_ 2395189505 DATC_FragranceKindSta 0 "Default" 1 "First" 2 "Second" 3 "Reserved" 4 "Reserved" 5 "Reserved" 6 "Reserved" 7 "Error Indicator" ;
VAL_ 2395189505 DATC_AfterBlowOpSta 0 "Default" 1 "Not Operation Status" 2 "Operation Status" 3 "Error Indicator" ;
VAL_ 2395189505 DATC_RrBlwDis 0 "OFF(Default)" 1 "Blank Display(Blower ´Ü¼ö ¹ÌÇ¥½Ã, ¿¹)Auto ½Ã)" 2 "1 Step" 3 "2 Step" 4 "3 Step" 5 "4 Step" 6 "5 Step" 7 "6 Step" 8 "7 Step" 9 "8 Step" 10 "BLOWER AUTO" 11 "Reserved" 12 "Reserved" 13 "Reserved" 14 "Reserved" 15 "Error Indicator" ;
VAL_ 2395189505 DATC_RrClmtAutoOffUSMSta 0 "Default" 1 "Off" 2 "On" 3 "Error Indicator" ;
VAL_ 2395189505 DATC_KeyOffBlowOpReq 0 "Off (Default)" 1 "On Request" 2 "RESERVED" 3 "Error Indicator" ;
VAL_ 2395189505 DATC_ArClnSysOSD 0 "Default (Initial Value)" 1 "AirCleaning SYS ON" 2 "AirCleaning SYS OFF" 3 "High Dust AirCleaning ON" 4 "High Dust AirCleaning OFF" 5 "Sensor AirCleaning SYS ON & Closing Window" 6 "Opening Warning" 7 "Reserved" 8 "Reserved" 9 "Reserved" 10 "Reserved" 11 "Reserved" 12 "Reserved" 13 "Reserved" 14 "Reserved" 15 "Invalid" ;
VAL_ 2395189505 DATC_ArClnStepClr 0 "Default (Initial Value)" 1 "Mono Color" 2 "Blue Color" 3 "Green Color" 4 "Orange Color" 5 "Red Color" 6 "Yellow Color" 7 "Reserved" 8 "Reserved" 9 "Reserved" 10 "Reserved" 11 "Reserved" 12 "Reserved" 13 "Reserved" 14 "Gray Color (Deactivate)" 15 "Invalid" ;
VAL_ 2395189505 DATC_ArClnSmblTyp 0 "Default" 1 "Blank (Initial Display)" 2 "Wood" 3 "Wood & Fixed Arrow" 4 "Wood & Rotating Arrow" 5 "White Wood & Fixed Arrow" 6 "White Wood & Rotating Arrow" 7 "Invaild" ;
VAL_ 2395189505 DATC_AfterBlowUSMSta 0 "Default" 1 "After Blow USM OFF" 2 "After Blow USM ON" 3 "Error Indicator" ;
VAL_ 2395189505 DATC_SchdldVntUSMSta 0 "Default" 1 "OFF" 2 "ON" 3 "Error Indicator" ;
VAL_ 2395189505 DATC_SchdldVntHrSta 0 "Default" 1 "0hr" 2 "1hr" 3 "2hr" 4 "3hr" 5 "4hr" 6 "5hr" 7 "6hr" 8 "7hr" 9 "8hr" 10 "9hr" 11 "10hr" 12 "11hr" 13 "12hr" 14 "13hr" 15 "14hr" 16 "15hr" 17 "16hr" 18 "17hr" 19 "18hr" 20 "19hr" 21 "20hr" 22 "21hr" 23 "22hr" 24 "23hr" 25 "Reserved" 26 "Reserved" 27 "Reserved" 28 "Reserved" 29 "Reserved" 30 "Reserved" 31 "Error Indicator" ;
VAL_ 2395189505 DATC_SchdldVntMinSta 0 "Default" 1 "0 Min" 2 "10 Min" 3 "20 Min" 4 "30 Min" 5 "40 Min" 6 "50 Min" 7 "Error Indicator" ;
VAL_ 527 ATS_DrvStRseFwdBtn 0 "Default" 1 "Off" 2 "On" 3 "Reserved" ;
VAL_ 527 ATS_DrvStRseBwdBtn 0 "Default" 1 "Off" 2 "On" 3 "Reserved" ;
VAL_ 527 ATS_RRRestModBtn 0 "Default" 1 "Off" 2 "On" 3 "Reserved" ;
VAL_ 527 ATS_RRResetModBtn 0 "Default" 1 "Off" 2 "On" 3 "Reserved" ;
VAL_ 527 ATS_RRAvWtcModBtn 0 "Default" 1 "Off" 2 "On" 3 "Reserved" ;
VAL_ 527 ATS_RRReadingModBtn 0 "Default" 1 "Off" 2 "On" 3 "Reserved" ;
VAL_ 527 ATS_RLRestModBtn 0 "Default" 1 "Off" 2 "On" 3 "Reserved" ;
VAL_ 527 ATS_RLResetModBtn 0 "Default" 1 "Off" 2 "On" 3 "Reserved" ;
VAL_ 1616 MKBD_IllumiState 0 "Not received" 1 "Receive Completed" 2 "Reserved" 3 "Invalid" ;
VAL_ 1616 MKBD_SeatKeySet 0 "Off" 1 "On" 2 "Reserved" 3 "Invalid" ;
VAL_ 543 ATS_AstStSldFwdBtn 0 "Default" 1 "Off" 2 "On" 3 "Reserved" ;
VAL_ 543 ATS_AstStSldBwdBtn 0 "Default" 1 "Off" 2 "On" 3 "Reserved" ;
VAL_ 543 ATS_AstStRclFwdBtn 0 "Default" 1 "Off" 2 "On" 3 "Reserved" ;
VAL_ 543 ATS_AstStRclBwdBtn 0 "Default" 1 "Off" 2 "On" 3 "Reserved" ;
VAL_ 543 ATS_AstStHgtUpBtn 0 "Default" 1 "Off" 2 "On" 3 "Reserved" ;
VAL_ 543 ATS_AstStHgtDnBtn 0 "Default" 1 "Off" 2 "On" 3 "Reserved" ;
VAL_ 543 ATS_AstStHRestUpBtn 0 "Default" 1 "Off" 2 "On" 3 "Reserved" ;
VAL_ 543 ATS_AstStHRestDnBtn 0 "Default" 1 "Off" 2 "On" 3 "Reserved" ;
VAL_ 543 ATS_AstStHRestFwdBtn 0 "Default" 1 "Off" 2 "On" 3 "Reserved" ;
VAL_ 543 ATS_AstStHRestBwdBtn 0 "Default" 1 "Off" 2 "On" 3 "Reserved" ;
VAL_ 543 ATS_AstStHRestFldBtn 0 "Default" 1 "Off" 2 "On" 3 "Reserved" ;
VAL_ 543 ATS_AstStHRestUnFldBtn 0 "Default" 1 "Off" 2 "On" 3 "Reserved" ;
VAL_ 543 ATS_AstStRseFwdBtn 0 "Default" 1 "Off" 2 "On" 3 "Reserved" ;
VAL_ 543 ATS_AstStRseBwdBtn 0 "Default" 1 "Off" 2 "On" 3 "Reserved" ;
VAL_ 543 ATS_AstStFRestFldBtn 0 "Default" 1 "Off" 2 "On" 3 "Reserved" ;
VAL_ 543 ATS_AstStFRestUnFldBtn 0 "Default" 1 "Off" 2 "On" 3 "Reserved" ;
VAL_ 543 ATS_AstTltUpBtn 0 "Default" 1 "Off" 2 "On" 3 "Reserved" ;
VAL_ 543 ATS_AstTltDnBtn 0 "Default" 1 "Off" 2 "On" 3 "Reserved" ;
